VERSION ""

NS_ :

BS_:

BU_: Engine2 Aftertreatment_1_GasOutlet BrakesSystemController Transmission1 Engine1

BO_ 2566799614 LD: 8 Vector__XXX
 SG_ ImplementRearWorkLight : 62|2@1+ (1,0) [0|3] "" Vector__XXX
 SG_ ImplementLeftFacingWorkLight : 60|2@1+ (1,0) [0|3] "" Vector__XXX
 SG_ ImplementRightForwardWorkLight : 58|2@1+ (1,0) [0|3] "" Vector__XXX
 SG_ ImplementLeftForwardWorkLight : 54|2@1+ (1,0) [0|3] "" Vector__XXX
 SG_ ImplementRightFacingWorkLight : 52|2@1+ (1,0) [0|3] "" Vector__XXX
 SG_ ImplementOEMOption1Light : 50|2@1+ (1,0) [0|3] "" Vector__XXX
 SG_ ImplementOEMOption2Light : 48|2@1+ (1,0) [0|3] "" Vector__XXX
 SG_ TrctorFrontHighMountedWorkLights : 46|2@1+ (1,0) [0|3] "" Vector__XXX
 SG_ TractorFrontLowMountedWorkLights : 44|2@1+ (1,0) [0|3] "" Vector__XXX
 SG_ TractorSideHighMountedWorkLights : 42|2@1+ (1,0) [0|3] "" Vector__XXX
 SG_ TractorSideLowMountedWorkLights : 40|2@1+ (1,0) [0|3] "" Vector__XXX
 SG_ TractorRearHighMountedWorkLights : 38|2@1+ (1,0) [0|3] "" Vector__XXX
 SG_ TractorRearLowMountedWorkLights : 36|2@1+ (1,0) [0|3] "" Vector__XXX
 SG_ TrctorUndersideMountedWorkLights : 34|2@1+ (1,0) [0|3] "" Vector__XXX
 SG_ RearFogLights : 32|2@1+ (1,0) [0|3] "" Vector__XXX
 SG_ TractorMarkerLight : 30|2@1+ (1,0) [0|3] "" Vector__XXX
 SG_ ImplementMarkerLight : 28|2@1+ (1,0) [0|3] "" Vector__XXX
 SG_ TractorClearanceLight : 26|2@1+ (1,0) [0|3] "" Vector__XXX
 SG_ ImplementClearanceLight : 24|2@1+ (1,0) [0|3] "" Vector__XXX
 SG_ LeftStopLight : 22|2@1+ (1,0) [0|3] "" Vector__XXX
 SG_ RightStopLight : 20|2@1+ (1,0) [0|3] "" Vector__XXX
 SG_ CenterStopLight : 18|2@1+ (1,0) [0|3] "" Vector__XXX
 SG_ BackUpLightAndAlarmHorn : 16|2@1+ (1,0) [0|3] "" Vector__XXX
 SG_ LeftTurnSignalLights : 14|2@1+ (1,0) [0|3] "" Vector__XXX
 SG_ RightTurnSignalLights : 12|2@1+ (1,0) [0|3] "" Vector__XXX
 SG_ RotatingBeaconLight : 10|2@1+ (1,0) [0|3] "" Vector__XXX
 SG_ TractorFrontFogLights : 8|2@1+ (1,0) [0|3] "" Vector__XXX
 SG_ HighBeamHeadLightData : 6|2@1+ (1,0) [0|3] "" Vector__XXX
 SG_ LowBeamHeadLightData : 4|2@1+ (1,0) [0|3] "" Vector__XXX
 SG_ AltBeamHeadLightData : 2|2@1+ (1,0) [0|3] "" Vector__XXX
 SG_ RunningLight : 0|2@1+ (1,0) [0|3] "" Vector__XXX

BO_ 2365473278 LCMD: 8 Vector__XXX
 SG_ ImplementRearWorkLightCmd : 62|2@1+ (1,0) [0|3] "" Vector__XXX
 SG_ ImplementLeftFacingWorkLightCmd : 60|2@1+ (1,0) [0|3] "" Vector__XXX
 SG_ ImplmentRightForwardWorkLightCmd : 58|2@1+ (1,0) [0|3] "" Vector__XXX
 SG_ LightingDataRqCmd : 56|2@1+ (1,0) [0|3] "" Vector__XXX
 SG_ ImplementLeftForwardWorkLightCmd : 54|2@1+ (1,0) [0|3] "" Vector__XXX
 SG_ ImplementRightFacingWorkLightCmd : 52|2@1+ (1,0) [0|3] "" Vector__XXX
 SG_ ImplementOEMOption1LightCmd : 50|2@1+ (1,0) [0|3] "" Vector__XXX
 SG_ ImplementOEMOption2LightCmd : 48|2@1+ (1,0) [0|3] "" Vector__XXX
 SG_ TrctrFrntHghMountedWorkLightsCmd : 46|2@1+ (1,0) [0|3] "" Vector__XXX
 SG_ TrctrFrntLowMountedWorkLightsCmd : 44|2@1+ (1,0) [0|3] "" Vector__XXX
 SG_ TrctrSdeHighMountedWorkLightsCmd : 42|2@1+ (1,0) [0|3] "" Vector__XXX
 SG_ TrctrSideLowMountedWorkLightsCmd : 40|2@1+ (1,0) [0|3] "" Vector__XXX
 SG_ TrctrRarHighMountedWorkLightsCmd : 38|2@1+ (1,0) [0|3] "" Vector__XXX
 SG_ TrctrRearLowMountedWorkLightsCmd : 36|2@1+ (1,0) [0|3] "" Vector__XXX
 SG_ TrctrUndrsdeMountedWorkLightsCmd : 34|2@1+ (1,0) [0|3] "" Vector__XXX
 SG_ RearFogLightCmd : 32|2@1+ (1,0) [0|3] "" Vector__XXX
 SG_ TractorMarkerLightCmd : 30|2@1+ (1,0) [0|3] "" Vector__XXX
 SG_ ImplementMarkerLightCmd : 28|2@1+ (1,0) [0|3] "" Vector__XXX
 SG_ TractorClearanceLightCmd : 26|2@1+ (1,0) [0|3] "" Vector__XXX
 SG_ ImplementClearanceLightCmd : 24|2@1+ (1,0) [0|3] "" Vector__XXX
 SG_ LeftStopLightCmd : 22|2@1+ (1,0) [0|3] "" Vector__XXX
 SG_ RightStopLightCmd : 20|2@1+ (1,0) [0|3] "" Vector__XXX
 SG_ CenterStopLightCmd : 18|2@1+ (1,0) [0|3] "" Vector__XXX
 SG_ BackUpLightAndAlarmHornCmd : 16|2@1+ (1,0) [0|3] "" Vector__XXX
 SG_ LeftTurnSignalLightsCmd : 14|2@1+ (1,0) [0|3] "" Vector__XXX
 SG_ RightTurnSignalLightsCmd : 12|2@1+ (1,0) [0|3] "" Vector__XXX
 SG_ RotatingBeaconLightCmd : 10|2@1+ (1,0) [0|3] "" Vector__XXX
 SG_ TractorFrontFogLightsCmd : 8|2@1+ (1,0) [0|3] "" Vector__XXX
 SG_ HighBeamHeadLightCmd : 6|2@1+ (1,0) [0|3] "" Vector__XXX
 SG_ LowBeamHeadLightCmd : 4|2@1+ (1,0) [0|3] "" Vector__XXX
 SG_ AltBeamHeadLightCmd : 2|2@1+ (1,0) [0|3] "" Vector__XXX
 SG_ RunningLightCmd : 0|2@1+ (1,0) [0|3] "" Vector__XXX

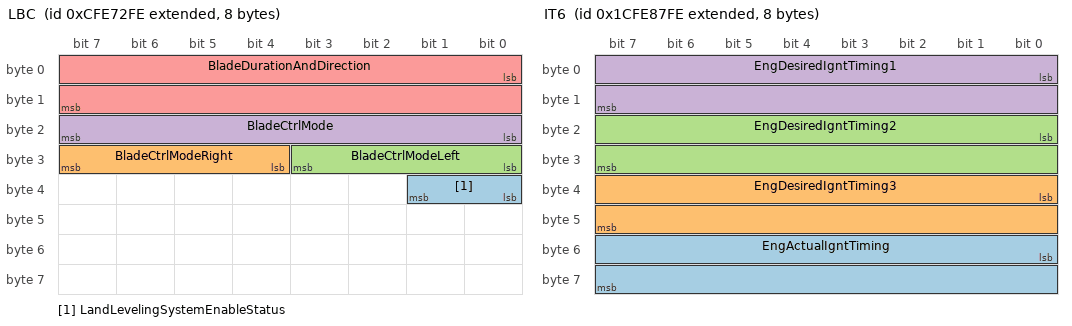
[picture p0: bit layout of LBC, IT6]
BO_ 2365485822 LBC: 8 Vector__XXX
 SG_ LandLevelingSystemEnableStatus : 32|2@1+ (1,0) [0|3] "" Vector__XXX
 SG_ BladeCtrlModeRight : 28|4@1+ (1,0) [0|15] "" Vector__XXX
 SG_ BladeCtrlModeLeft : 24|4@1+ (1,0) [0|15] "" Vector__XXX
 SG_ BladeCtrlMode : 16|8@1+ (1,0) [0|255] "" Vector__XXX
 SG_ BladeDurationAndDirection : 0|16@1+ (0.1,-3276.8) [-3276.8|3148.7] "sec" Vector__XXX

BO_ 2633926654 IT6: 8 Vector__XXX
 SG_ EngActualIgntTiming : 48|16@1+ (0.0078125,-200) [-200|301.99] "deg" Vector__XXX
 SG_ EngDesiredIgntTiming3 : 32|16@1+ (0.0078125,-200) [-200|301.99] "deg" Vector__XXX
 SG_ EngDesiredIgntTiming2 : 16|16@1+ (0.0078125,-200) [-200|301.99] "deg" Vector__XXX
 SG_ EngDesiredIgntTiming1 : 0|16@1+ (0.0078125,-200) [-200|301.99] "deg" Vector__XXX

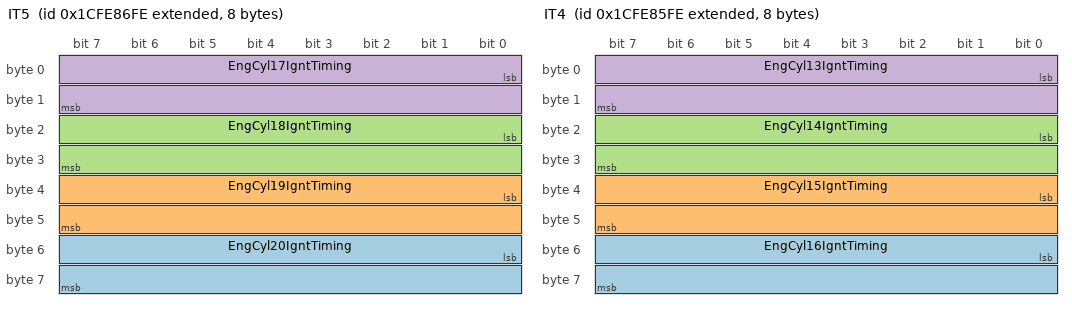
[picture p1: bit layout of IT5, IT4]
BO_ 2633926398 IT5: 8 Vector__XXX
 SG_ EngCyl20IgntTiming : 48|16@1+ (0.0078125,-200) [-200|301.99] "deg" Vector__XXX
 SG_ EngCyl19IgntTiming : 32|16@1+ (0.0078125,-200) [-200|301.99] "deg" Vector__XXX
 SG_ EngCyl18IgntTiming : 16|16@1+ (0.0078125,-200) [-200|301.99] "deg" Vector__XXX
 SG_ EngCyl17IgntTiming : 0|16@1+ (0.0078125,-200) [-200|301.99] "deg" Vector__XXX

BO_ 2633926142 IT4: 8 Vector__XXX
 SG_ EngCyl16IgntTiming : 48|16@1+ (0.0078125,-200) [-200|301.99] "deg" Vector__XXX
 SG_ EngCyl15IgntTiming : 32|16@1+ (0.0078125,-200) [-200|301.99] "deg" Vector__XXX
 SG_ EngCyl14IgntTiming : 16|16@1+ (0.0078125,-200) [-200|301.99] "deg" Vector__XXX
 SG_ EngCyl13IgntTiming : 0|16@1+ (0.0078125,-200) [-200|301.99] "deg" Vector__XXX

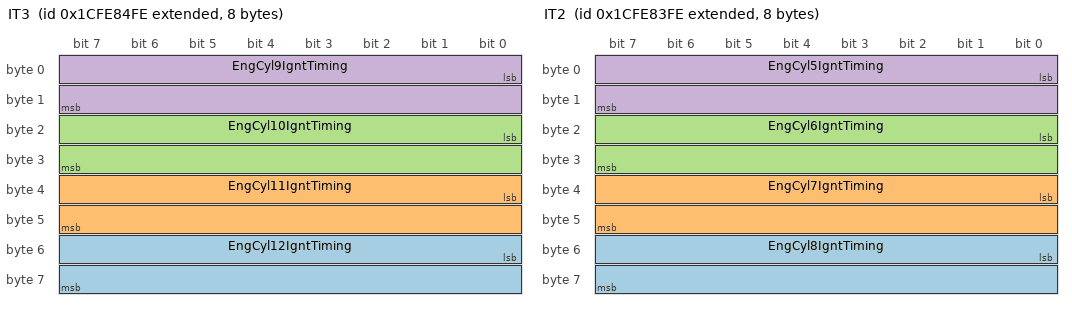
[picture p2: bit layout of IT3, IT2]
BO_ 2633925886 IT3: 8 Vector__XXX
 SG_ EngCyl12IgntTiming : 48|16@1+ (0.0078125,-200) [-200|301.99] "deg" Vector__XXX
 SG_ EngCyl11IgntTiming : 32|16@1+ (0.0078125,-200) [-200|301.99] "deg" Vector__XXX
 SG_ EngCyl10IgntTiming : 16|16@1+ (0.0078125,-200) [-200|301.99] "deg" Vector__XXX
 SG_ EngCyl9IgntTiming : 0|16@1+ (0.0078125,-200) [-200|301.99] "deg" Vector__XXX

BO_ 2633925630 IT2: 8 Vector__XXX
 SG_ EngCyl8IgntTiming : 48|16@1+ (0.0078125,-200) [-200|301.99] "deg" Vector__XXX
 SG_ EngCyl7IgntTiming : 32|16@1+ (0.0078125,-200) [-200|301.99] "deg" Vector__XXX
 SG_ EngCyl6IgntTiming : 16|16@1+ (0.0078125,-200) [-200|301.99] "deg" Vector__XXX
 SG_ EngCyl5IgntTiming : 0|16@1+ (0.0078125,-200) [-200|301.99] "deg" Vector__XXX

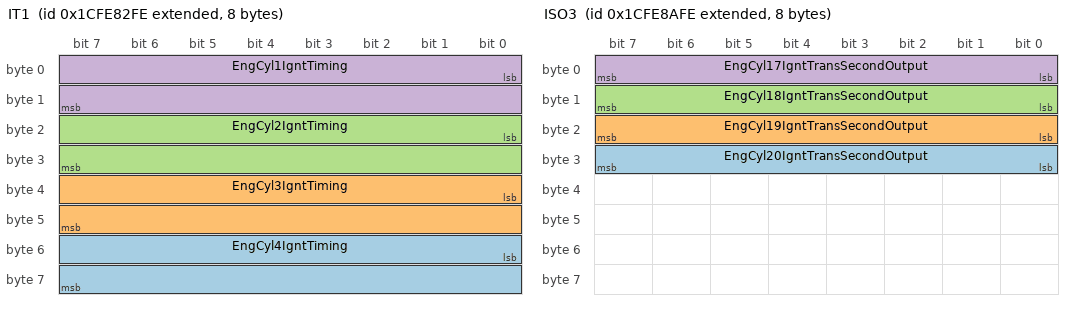
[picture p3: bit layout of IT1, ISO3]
BO_ 2633925374 IT1: 8 Vector__XXX
 SG_ EngCyl4IgntTiming : 48|16@1+ (0.0078125,-200) [-200|301.99] "deg" Vector__XXX
 SG_ EngCyl3IgntTiming : 32|16@1+ (0.0078125,-200) [-200|301.99] "deg" Vector__XXX
 SG_ EngCyl2IgntTiming : 16|16@1+ (0.0078125,-200) [-200|301.99] "deg" Vector__XXX
 SG_ EngCyl1IgntTiming : 0|16@1+ (0.0078125,-200) [-200|301.99] "deg" Vector__XXX

BO_ 2633927422 ISO3: 8 Vector__XXX
 SG_ EngCyl20IgntTransSecondOutput : 24|8@1+ (1,-125) [-125|125] "%" Vector__XXX
 SG_ EngCyl19IgntTransSecondOutput : 16|8@1+ (1,-125) [-125|125] "%" Vector__XXX
 SG_ EngCyl18IgntTransSecondOutput : 8|8@1+ (1,-125) [-125|125] "%" Vector__XXX
 SG_ EngCyl17IgntTransSecondOutput : 0|8@1+ (1,-125) [-125|125] "%" Vector__XXX

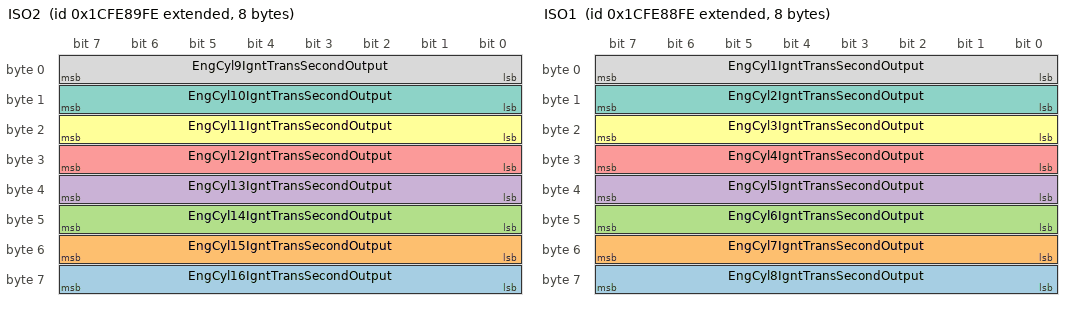
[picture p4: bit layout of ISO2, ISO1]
BO_ 2633927166 ISO2: 8 Vector__XXX
 SG_ EngCyl16IgntTransSecondOutput : 56|8@1+ (1,-125) [-125|125] "%" Vector__XXX
 SG_ EngCyl15IgntTransSecondOutput : 48|8@1+ (1,-125) [-125|125] "%" Vector__XXX
 SG_ EngCyl14IgntTransSecondOutput : 40|8@1+ (1,-125) [-125|125] "%" Vector__XXX
 SG_ EngCyl13IgntTransSecondOutput : 32|8@1+ (1,-125) [-125|125] "%" Vector__XXX
 SG_ EngCyl12IgntTransSecondOutput : 24|8@1+ (1,-125) [-125|125] "%" Vector__XXX
 SG_ EngCyl11IgntTransSecondOutput : 16|8@1+ (1,-125) [-125|125] "%" Vector__XXX
 SG_ EngCyl10IgntTransSecondOutput : 8|8@1+ (1,-125) [-125|125] "%" Vector__XXX
 SG_ EngCyl9IgntTransSecondOutput : 0|8@1+ (1,-125) [-125|125] "%" Vector__XXX

BO_ 2633926910 ISO1: 8 Vector__XXX
 SG_ EngCyl8IgntTransSecondOutput : 56|8@1+ (1,-125) [-125|125] "%" Vector__XXX
 SG_ EngCyl7IgntTransSecondOutput : 48|8@1+ (1,-125) [-125|125] "%" Vector__XXX
 SG_ EngCyl6IgntTransSecondOutput : 40|8@1+ (1,-125) [-125|125] "%" Vector__XXX
 SG_ EngCyl5IgntTransSecondOutput : 32|8@1+ (1,-125) [-125|125] "%" Vector__XXX
 SG_ EngCyl4IgntTransSecondOutput : 24|8@1+ (1,-125) [-125|125] "%" Vector__XXX
 SG_ EngCyl3IgntTransSecondOutput : 16|8@1+ (1,-125) [-125|125] "%" Vector__XXX
 SG_ EngCyl2IgntTransSecondOutput : 8|8@1+ (1,-125) [-125|125] "%" Vector__XXX
 SG_ EngCyl1IgntTransSecondOutput : 0|8@1+ (1,-125) [-125|125] "%" Vector__XXX

BO_ 2566768894 ISCS: 8 Vector__XXX
 SG_ EngOprtrPrmryIntrmdtSpdSlctState : 0|4@1+ (1,0) [0|15] "" Vector__XXX

BO_ 2566769406 ISC: 8 Vector__XXX
 SG_ EngOprtrPrmryIntrmdteSpeedSelect : 0|4@1+ (1,0) [0|15] "" Vector__XXX

BO_ 2566839550 IO: 8 Vector__XXX
 SG_ EngTotalIdleHours : 32|32@1+ (0.05,0) [0|210554060.75] "h" Vector__XXX
 SG_ EngTotalIdleFuelUsed : 0|32@1+ (0.5,0) [0|2105540607.5] "L" Vector__XXX

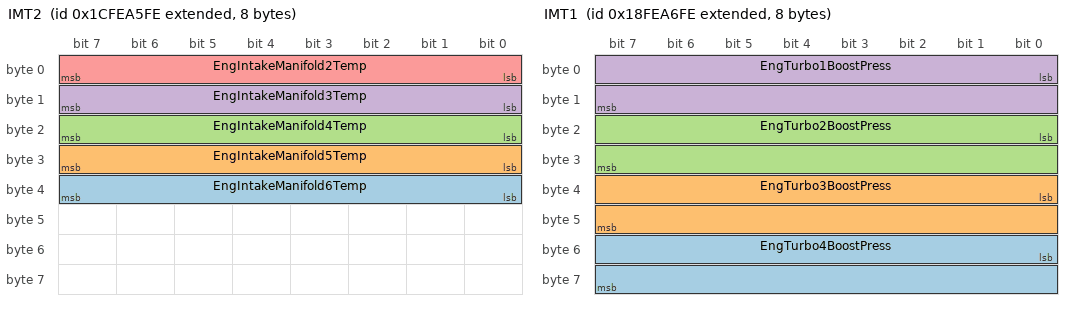
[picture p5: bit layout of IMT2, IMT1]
BO_ 2633934334 IMT2: 8 Vector__XXX
 SG_ EngIntakeManifold6Temp : 32|8@1+ (1,-40) [-40|210] "°C" Vector__XXX
 SG_ EngIntakeManifold5Temp : 24|8@1+ (1,-40) [-40|210] "°C" Vector__XXX
 SG_ EngIntakeManifold4Temp : 16|8@1+ (1,-40) [-40|210] "°C" Vector__XXX
 SG_ EngIntakeManifold3Temp : 8|8@1+ (1,-40) [-40|210] "°C" Vector__XXX
 SG_ EngIntakeManifold2Temp : 0|8@1+ (1,-40) [-40|210] "°C" Vector__XXX

BO_ 2566825726 IMT1: 8 Vector__XXX
 SG_ EngTurbo4BoostPress : 48|16@1+ (0.125,0) [0|8031.875] "kPa" Vector__XXX
 SG_ EngTurbo3BoostPress : 32|16@1+ (0.125,0) [0|8031.875] "kPa" Vector__XXX
 SG_ EngTurbo2BoostPress : 16|16@1+ (0.125,0) [0|8031.875] "kPa" Vector__XXX
 SG_ EngTurbo1BoostPress : 0|16@1+ (0.125,0) [0|8031.875] "kPa" Vector__XXX

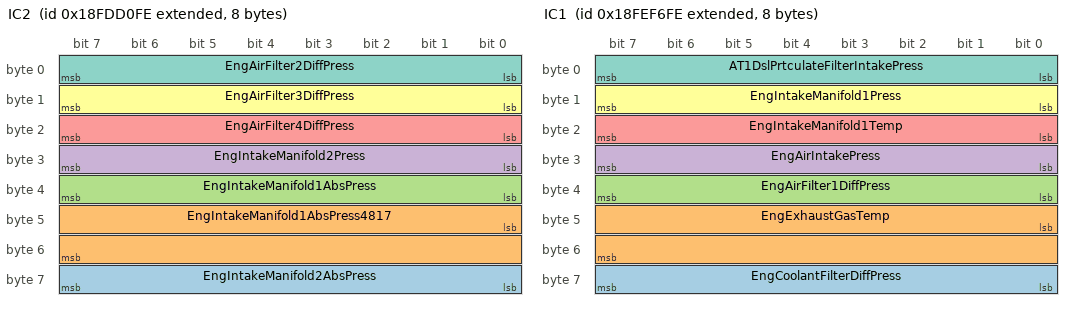
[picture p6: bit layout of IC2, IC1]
BO_ 2566770942 IC2: 8 Vector__XXX
 SG_ EngIntakeManifold2AbsPress : 56|8@1+ (2,0) [0|500] "kPa" Vector__XXX
 SG_ EngIntakeManifold1AbsPress4817 : 40|16@1+ (0.1,0) [0|6425.5] "kPa" Vector__XXX
 SG_ EngIntakeManifold1AbsPress : 32|8@1+ (2,0) [0|500] "kPa" Vector__XXX
 SG_ EngIntakeManifold2Press : 24|8@1+ (2,0) [0|500] "kPa" Vector__XXX
 SG_ EngAirFilter4DiffPress : 16|8@1+ (0.05,0) [0|12.5] "kPa" Vector__XXX
 SG_ EngAirFilter3DiffPress : 8|8@1+ (0.05,0) [0|12.5] "kPa" Vector__XXX
 SG_ EngAirFilter2DiffPress : 0|8@1+ (0.05,0) [0|12.5] "kPa" Vector__XXX

BO_ 2566846206 IC1: 8 Vector__XXX
 SG_ EngCoolantFilterDiffPress : 56|8@1+ (0.5,0) [0|125] "kPa" Vector__XXX
 SG_ EngExhaustGasTemp : 40|16@1+ (0.03125,-273) [-273|1734.96875] "°C" Vector__XXX
 SG_ EngAirFilter1DiffPress : 32|8@1+ (0.05,0) [0|12.5] "kPa" Vector__XXX
 SG_ EngAirIntakePress : 24|8@1+ (2,0) [0|500] "kPa" Vector__XXX
 SG_ EngIntakeManifold1Temp : 16|8@1+ (1,-40) [-40|210] "°C" Vector__XXX
 SG_ EngIntakeManifold1Press : 8|8@1+ (2,0) [0|500] "kPa" Vector__XXX
 SG_ AT1DslPrtculateFilterIntakePress : 0|8@1+ (0.5,0) [0|125] "kPa" Vector__XXX

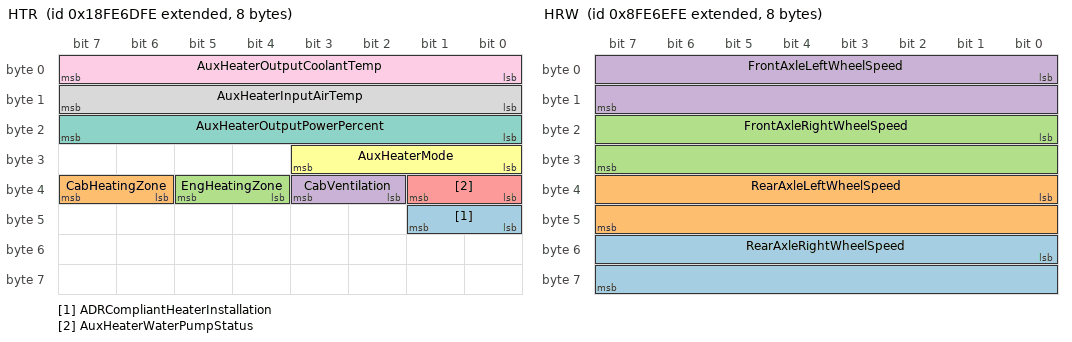
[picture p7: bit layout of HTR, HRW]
BO_ 2566811134 HTR: 8 Vector__XXX
 SG_ ADRCompliantHeaterInstallation : 40|2@1+ (1,0) [0|3] "" Vector__XXX
 SG_ CabHeatingZone : 38|2@1+ (1,0) [0|3] "" Vector__XXX
 SG_ EngHeatingZone : 36|2@1+ (1,0) [0|3] "" Vector__XXX
 SG_ CabVentilation : 34|2@1+ (1,0) [0|3] "" Vector__XXX
 SG_ AuxHeaterWaterPumpStatus : 32|2@1+ (1,0) [0|3] "" Vector__XXX
 SG_ AuxHeaterMode : 24|4@1+ (1,0) [0|15] "" Vector__XXX
 SG_ AuxHeaterOutputPowerPercent : 16|8@1+ (0.4,0) [0|100] "%" Vector__XXX
 SG_ AuxHeaterInputAirTemp : 8|8@1+ (1,-40) [-40|210] "°C" Vector__XXX
 SG_ AuxHeaterOutputCoolantTemp : 0|8@1+ (1,-40) [-40|210] "°C" Vector__XXX

BO_ 2298375934 HRW: 8 Vector__XXX
 SG_ RearAxleRightWheelSpeed : 48|16@1+ (0.00390625,0) [0|250.996] "km/h" Vector__XXX
 SG_ RearAxleLeftWheelSpeed : 32|16@1+ (0.00390625,0) [0|250.996] "km/h" Vector__XXX
 SG_ FrontAxleRightWheelSpeed : 16|16@1+ (0.00390625,0) [0|250.996] "km/h" Vector__XXX
 SG_ FrontAxleLeftWheelSpeed : 0|16@1+ (0.00390625,0) [0|250.996] "km/h" Vector__XXX

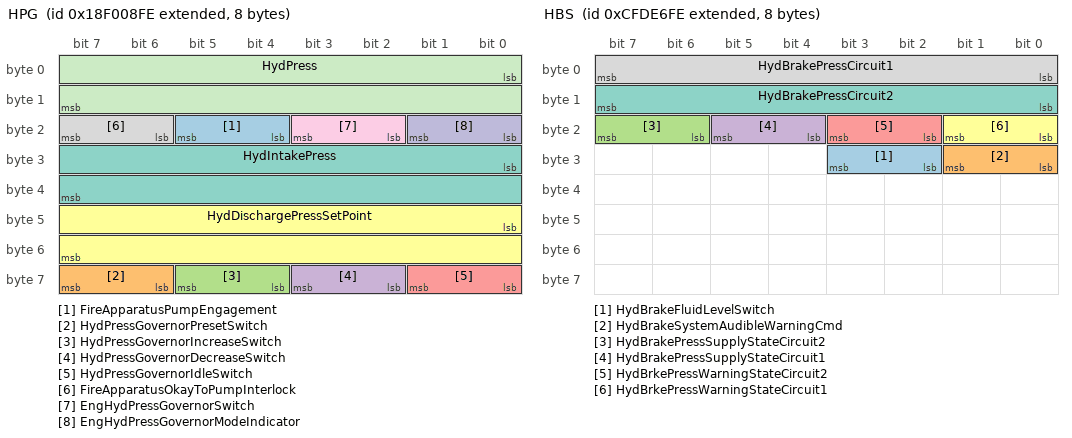
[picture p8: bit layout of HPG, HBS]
BO_ 2565867774 HPG: 8 Vector__XXX
 SG_ FireApparatusPumpEngagement : 20|2@1+ (1,0) [0|3] "" Vector__XXX
 SG_ HydPressGovernorPresetSwitch : 62|2@1+ (1,0) [0|3] "" Vector__XXX
 SG_ HydPressGovernorIncreaseSwitch : 60|2@1+ (1,0) [0|3] "" Vector__XXX
 SG_ HydPressGovernorDecreaseSwitch : 58|2@1+ (1,0) [0|3] "" Vector__XXX
 SG_ HydPressGovernorIdleSwitch : 56|2@1+ (1,0) [0|3] "" Vector__XXX
 SG_ HydDischargePressSetPoint : 40|16@1+ (2,0) [0|128510] "kPa" Vector__XXX
 SG_ HydIntakePress : 24|16@1+ (0.0001220703125,-1) [-1|6.84362793] "MPa" Vector__XXX
 SG_ FireApparatusOkayToPumpInterlock : 22|2@1+ (1,0) [0|3] "" Vector__XXX
 SG_ EngHydPressGovernorSwitch : 18|2@1+ (1,0) [0|3] "" Vector__XXX
 SG_ EngHydPressGovernorModeIndicator : 16|2@1+ (1,0) [0|3] "" Vector__XXX
 SG_ HydPress : 0|16@1+ (2,0) [0|128510] "kPa" Vector__XXX

BO_ 2566841854 HOURS: 8 Vector__XXX
 SG_ EngTotalRevolutions : 32|32@1+ (1000,0) [0|4211081215000] "r" Vector__XXX
 SG_ EngTotalHoursOfOperation : 0|32@1+ (0.05,0) [0|210554060.75] "h" Vector__XXX

BO_ 2365449982 HBS: 8 Vector__XXX
 SG_ HydBrakeFluidLevelSwitch : 26|2@1+ (1,0) [0|3] "" Vector__XXX
 SG_ HydBrakeSystemAudibleWarningCmd : 24|2@1+ (1,0) [0|3] "" Vector__XXX
 SG_ HydBrakePressSupplyStateCircuit2 : 22|2@1+ (1,0) [0|3] "" Vector__XXX
 SG_ HydBrakePressSupplyStateCircuit1 : 20|2@1+ (1,0) [0|3] "" Vector__XXX
 SG_ HydBrkePressWarningStateCircuit2 : 18|2@1+ (1,0) [0|3] "" Vector__XXX
 SG_ HydBrkePressWarningStateCircuit1 : 16|2@1+ (1,0) [0|3] "" Vector__XXX
 SG_ HydBrakePressCircuit2 : 8|8@1+ (100,0) [0|25000] "kPa" Vector__XXX
 SG_ HydBrakePressCircuit1 : 0|8@1+ (100,0) [0|25000] "kPa" Vector__XXX

BO_ 2633939198 GTFI: 22 Vector__XXX
 SG_ TripDriveFuelEconomy : 160|16@1+ (0.001953125,0) [0|125.498046875] "km/kg" Vector__XXX
 SG_ TripCruiseFuelUsed : 128|32@1+ (0.5,0) [0|2105540607.5] "kg" Vector__XXX
 SG_ TripVehicleIdleFuelUsed : 96|32@1+ (0.5,0) [0|2105540607.5] "kg" Vector__XXX
 SG_ TripPTOGovernorNonmovingFuelUsed : 64|32@1+ (0.5,0) [0|2105540607.5] "kg" Vector__XXX
 SG_ TripPTOGovernorMovingFuelUsed : 32|32@1+ (0.5,0) [0|2105540607.5] "kg" Vector__XXX
 SG_ TripDriveFuelUsed : 0|32@1+ (0.5,0) [0|2105540607.5] "kg" Vector__XXX

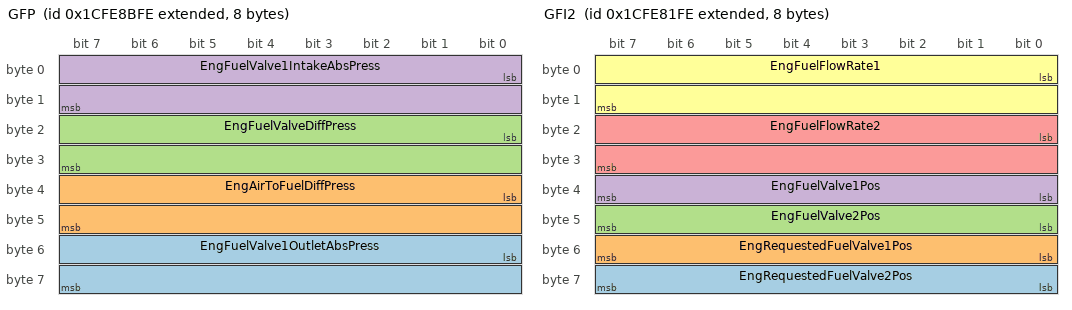
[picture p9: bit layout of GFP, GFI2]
BO_ 2633927678 GFP: 8 Vector__XXX
 SG_ EngFuelValve1OutletAbsPress : 48|16@1+ (0.1,0) [0|6425.5] "kPa" Vector__XXX
 SG_ EngAirToFuelDiffPress : 32|16@1+ (0.1,0) [0|6425.5] "kPa" Vector__XXX
 SG_ EngFuelValveDiffPress : 16|16@1+ (0.1,0) [0|6425.5] "kPa" Vector__XXX
 SG_ EngFuelValve1IntakeAbsPress : 0|16@1+ (0.1,0) [0|6425.5] "kPa" Vector__XXX

BO_ 2633925118 GFI2: 8 Vector__XXX
 SG_ EngRequestedFuelValve2Pos : 56|8@1+ (0.4,0) [0|100] "%" Vector__XXX
 SG_ EngRequestedFuelValve1Pos : 48|8@1+ (0.4,0) [0|100] "%" Vector__XXX
 SG_ EngFuelValve2Pos : 40|8@1+ (0.4,0) [0|100] "%" Vector__XXX
 SG_ EngFuelValve1Pos : 32|8@1+ (0.4,0) [0|100] "%" Vector__XXX
 SG_ EngFuelFlowRate2 : 16|16@1+ (0.1,0) [0|6425.5] "m³/h" Vector__XXX
 SG_ EngFuelFlowRate1 : 0|16@1+ (0.1,0) [0|6425.5] "m³/h" Vector__XXX

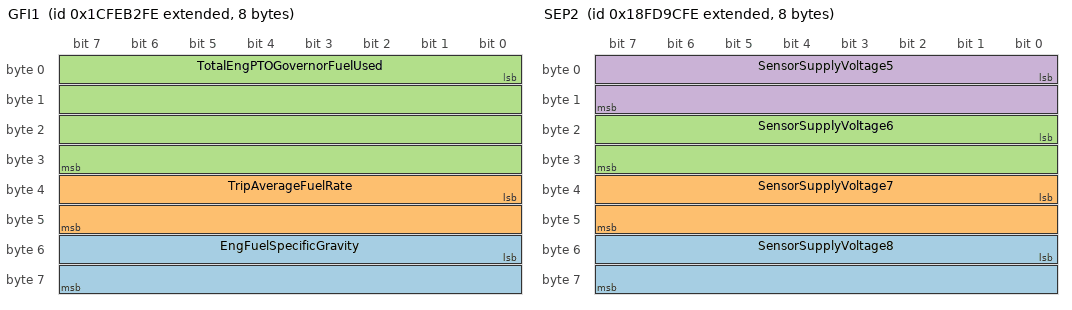
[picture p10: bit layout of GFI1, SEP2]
BO_ 2633937662 GFI1: 8 Vector__XXX
 SG_ EngFuelSpecificGravity : 48|16@1+ (0.0001,0) [0|2] "" Vector__XXX
 SG_ TripAverageFuelRate : 32|16@1+ (0.05,0) [0|3212.75] "kg/h" Vector__XXX
 SG_ TotalEngPTOGovernorFuelUsed : 0|32@1+ (0.5,0) [0|2105540607.5] "kg" Vector__XXX

BO_ 2566804990 GFD: 8 Vector__XXX
 SG_ FuelEnergyContent : 32|16@1+ (0.00390625,0) [0|250.996] "MJ/Nm³" Vector__XXX
 SG_ ReferenceEngGasMassFlowRate : 16|16@1+ (0.05,0) [0|3212.75] "kg/h" Vector__XXX
 SG_ SpecificHeatRatio : 0|16@1+ (0.001,0) [0|2] "" Vector__XXX

BO_ 2633936894 GFC: 8 Vector__XXX
 SG_ TotalFuelUsed : 32|32@1+ (0.5,0) [0|2105540607.5] "kg" Vector__XXX
 SG_ TripFuel : 0|32@1+ (0.5,0) [0|2105540607.5] "kg" Vector__XXX

BO_ 2566757630 SEP2: 8 Vector__XXX
 SG_ SensorSupplyVoltage8 : 48|16@1+ (0.05,0) [0|3212.75] "V" Vector__XXX
 SG_ SensorSupplyVoltage7 : 32|16@1+ (0.05,0) [0|3212.75] "V" Vector__XXX
 SG_ SensorSupplyVoltage6 : 16|16@1+ (0.05,0) [0|3212.75] "V" Vector__XXX
 SG_ SensorSupplyVoltage5 : 0|16@1+ (0.05,0) [0|3212.75] "V" Vector__XXX

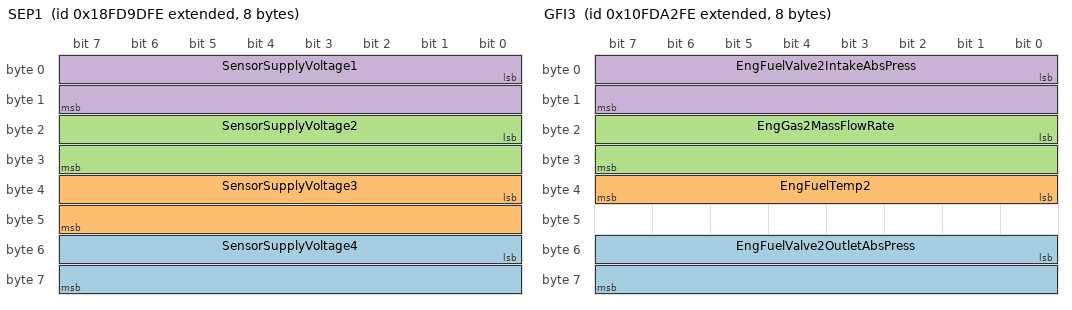
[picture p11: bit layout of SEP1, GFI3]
BO_ 2566757886 SEP1: 8 Vector__XXX
 SG_ SensorSupplyVoltage4 : 48|16@1+ (0.05,0) [0|3212.75] "V" Vector__XXX
 SG_ SensorSupplyVoltage3 : 32|16@1+ (0.05,0) [0|3212.75] "V" Vector__XXX
 SG_ SensorSupplyVoltage2 : 16|16@1+ (0.05,0) [0|3212.75] "V" Vector__XXX
 SG_ SensorSupplyVoltage1 : 0|16@1+ (0.05,0) [0|3212.75] "V" Vector__XXX

BO_ 2566759678 PTODE: 8 Vector__XXX
 SG_ AtLeastOnePTOEngaged : 48|2@1+ (1,0) [0|3] "" Vector__XXX
 SG_ EnggmntSttsPTOEngAccessoryDrive2 : 44|2@1+ (1,0) [0|3] "" Vector__XXX
 SG_ EnggmntSttsPTOEngAccessoryDrive1 : 42|2@1+ (1,0) [0|3] "" Vector__XXX
 SG_ EngagementStatusPTOEngFlywheel : 40|2@1+ (1,0) [0|3] "" Vector__XXX
 SG_ EnggmntStatusTransInputShaftPTO1 : 38|2@1+ (1,0) [0|3] "" Vector__XXX
 SG_ EnggmntStatusTransInputShaftPTO2 : 36|2@1+ (1,0) [0|3] "" Vector__XXX
 SG_ EnggmntStatusTransOutputShaftPTO : 34|2@1+ (1,0) [0|3] "" Vector__XXX
 SG_ EnggmntSttsTrnsfrCsOtputShaftPTO : 32|2@1+ (1,0) [0|3] "" Vector__XXX
 SG_ EnggmntCnsntPTOEngAccssoryDrive2 : 28|2@1+ (1,0) [0|3] "" Vector__XXX
 SG_ EnggmntCnsntPTOEngAccssoryDrive1 : 26|2@1+ (1,0) [0|3] "" Vector__XXX
 SG_ EngagementConsentPTOEngFlywheel : 24|2@1+ (1,0) [0|3] "" Vector__XXX
 SG_ EnggmntCnsentTransInputShaftPTO1 : 22|2@1+ (1,0) [0|3] "" Vector__XXX
 SG_ EnggmntCnsentTransInputShaftPTO2 : 20|2@1+ (1,0) [0|3] "" Vector__XXX
 SG_ EnggmntCnsentTransOutputShaftPTO : 18|2@1+ (1,0) [0|3] "" Vector__XXX
 SG_ EnggmntCnsntTrnsfrCsOtptShaftPTO : 16|2@1+ (1,0) [0|3] "" Vector__XXX
 SG_ EnbleSwitchPTOEngAccessoryDrive2 : 12|2@1+ (1,0) [0|3] "" Vector__XXX
 SG_ EnbleSwitchPTOEngAccessoryDrive1 : 10|2@1+ (1,0) [0|3] "" Vector__XXX
 SG_ EnableSwitchPTOEngFlywheel : 8|2@1+ (1,0) [0|3] "" Vector__XXX
 SG_ EnableSwitchTransInputShaftPTO1 : 6|2@1+ (1,0) [0|3] "" Vector__XXX
 SG_ EnableSwitchTransInputShaftPTO2 : 4|2@1+ (1,0) [0|3] "" Vector__XXX
 SG_ EnableSwitchTransOutputShaftPTO : 2|2@1+ (1,0) [0|3] "" Vector__XXX
 SG_ EnblSwtchTrnsfrCseOutputShaftPTO : 0|2@1+ (1,0) [0|3] "" Vector__XXX

BO_ 2432541438 GFI3: 8 Vector__XXX
 SG_ EngFuelValve2OutletAbsPress : 48|16@1+ (0.1,0) [0|6425.5] "kPa" Vector__XXX
 SG_ EngFuelTemp2 : 32|8@1+ (1,-40) [-40|210] "°C" Vector__XXX
 SG_ EngGas2MassFlowRate : 16|16@1+ (0.05,0) [0|3212.75] "kg/h" Vector__XXX
 SG_ EngFuelValve2IntakeAbsPress : 0|16@1+ (0.1,0) [0|6425.5] "kPa" Vector__XXX

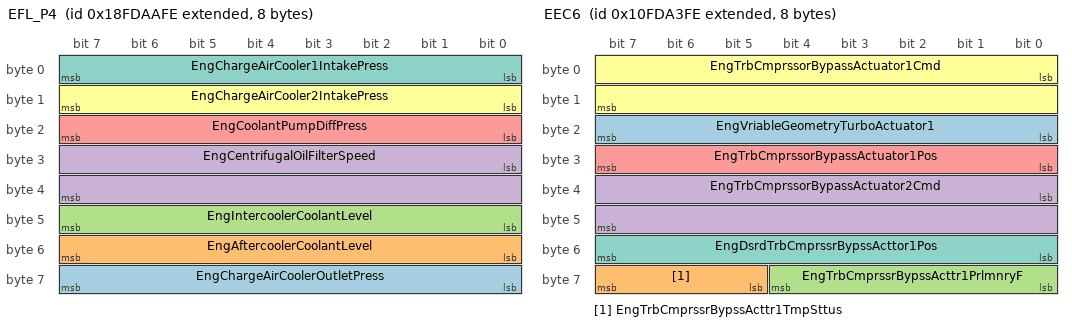
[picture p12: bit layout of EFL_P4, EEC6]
BO_ 2566761214 EFL_P4: 8 Vector__XXX
 SG_ EngChargeAirCoolerOutletPress : 56|8@1+ (2,0) [0|500] "kPa" Vector__XXX
 SG_ EngAftercoolerCoolantLevel : 48|8@1+ (0.4,0) [0|100] "%" Vector__XXX
 SG_ EngIntercoolerCoolantLevel : 40|8@1+ (0.4,0) [0|100] "%" Vector__XXX
 SG_ EngCentrifugalOilFilterSpeed : 24|16@1+ (4,0) [0|257020] "rpm" Vector__XXX
 SG_ EngCoolantPumpDiffPress : 16|8@1+ (1.64,-7) [-7|403] "kPa" Vector__XXX
 SG_ EngChargeAirCooler2IntakePress : 8|8@1+ (2,0) [0|500] "kPa" Vector__XXX
 SG_ EngChargeAirCooler1IntakePress : 0|8@1+ (2,0) [0|500] "kPa" Vector__XXX

BO_ 2432541694 EEC6: 8 Vector__XXX
 SG_ EngVriableGeometryTurboActuator1 : 16|8@1+ (0.4,0) [0|100] "%" Vector__XXX
 SG_ EngTrbCmprssrBypssActtr1TmpSttus : 61|3@1+ (1,0) [0|7] "" Vector__XXX
 SG_ EngTrbCmprssrBypssActtr1PrlmnryF : 56|5@1+ (1,0) [0|31] "" Vector__XXX
 SG_ EngTrbCmprssorBypassActuator2Cmd : 32|16@1+ (0.0025,0) [0|160.6375] "%" Vector__XXX
 SG_ EngTrbCmprssorBypassActuator1Pos : 24|8@1+ (0.4,0) [0|100] "%" Vector__XXX
 SG_ EngTrbCmprssorBypassActuator1Cmd : 0|16@1+ (0.0025,0) [0|100] "%" Vector__XXX
 SG_ EngDsrdTrbCmprssrBypssActtor1Pos : 48|8@1+ (0.4,0) [0|100] "%" Vector__XXX

BO_ 2566759934 DC2: 8 Vector__XXX
 SG_ EnableStatusOfDoor10 : 58|2@1+ (1,0) [0|3] "" Vector__XXX
 SG_ OpenStatusOfDoor10 : 56|2@1+ (1,0) [0|3] "" Vector__XXX
 SG_ LockStatusOfDoor10 : 54|2@1+ (1,0) [0|3] "" Vector__XXX
 SG_ EnableStatusOfDoor9 : 52|2@1+ (1,0) [0|3] "" Vector__XXX
 SG_ OpenStatusOfDoor9 : 50|2@1+ (1,0) [0|3] "" Vector__XXX
 SG_ LockStatusOfDoor9 : 48|2@1+ (1,0) [0|3] "" Vector__XXX
 SG_ EnableStatusOfDoor8 : 46|2@1+ (1,0) [0|3] "" Vector__XXX
 SG_ OpenStatusOfDoor8 : 44|2@1+ (1,0) [0|3] "" Vector__XXX
 SG_ LockStatusOfDoor8 : 42|2@1+ (1,0) [0|3] "" Vector__XXX
 SG_ EnableStatusOfDoor7 : 40|2@1+ (1,0) [0|3] "" Vector__XXX
 SG_ OpenStatusOfDoor7 : 38|2@1+ (1,0) [0|3] "" Vector__XXX
 SG_ LockStatusOfDoor7 : 36|2@1+ (1,0) [0|3] "" Vector__XXX
 SG_ EnableStatusOfDoor6 : 34|2@1+ (1,0) [0|3] "" Vector__XXX
 SG_ OpenStatusOfDoor6 : 32|2@1+ (1,0) [0|3] "" Vector__XXX
 SG_ LockStatusOfDoor6 : 30|2@1+ (1,0) [0|3] "" Vector__XXX
 SG_ EnableStatusOfDoor5 : 28|2@1+ (1,0) [0|3] "" Vector__XXX
 SG_ OpenStatusOfDoor5 : 26|2@1+ (1,0) [0|3] "" Vector__XXX
 SG_ LockStatusOfDoor5 : 24|2@1+ (1,0) [0|3] "" Vector__XXX
 SG_ EnableStatusOfDoor4 : 22|2@1+ (1,0) [0|3] "" Vector__XXX
 SG_ OpenStatusOfDoor4 : 20|2@1+ (1,0) [0|3] "" Vector__XXX
 SG_ LockStatusOfDoor4 : 18|2@1+ (1,0) [0|3] "" Vector__XXX
 SG_ EnableStatusOfDoor3 : 16|2@1+ (1,0) [0|3] "" Vector__XXX
 SG_ OpenStatusOfDoor3 : 14|2@1+ (1,0) [0|3] "" Vector__XXX
 SG_ LockStatusOfDoor3 : 12|2@1+ (1,0) [0|3] "" Vector__XXX
 SG_ EnableStatusOfDoor2 : 10|2@1+ (1,0) [0|3] "" Vector__XXX
 SG_ OpenStatusOfDoor2 : 8|2@1+ (1,0) [0|3] "" Vector__XXX
 SG_ LockStatusOfDoor2 : 6|2@1+ (1,0) [0|3] "" Vector__XXX
 SG_ EnableStatusOfDoor1 : 4|2@1+ (1,0) [0|3] "" Vector__XXX
 SG_ OpenStatusOfDoor1 : 2|2@1+ (1,0) [0|3] "" Vector__XXX
 SG_ LockStatusOfDoor1 : 0|2@1+ (1,0) [0|3] "" Vector__XXX

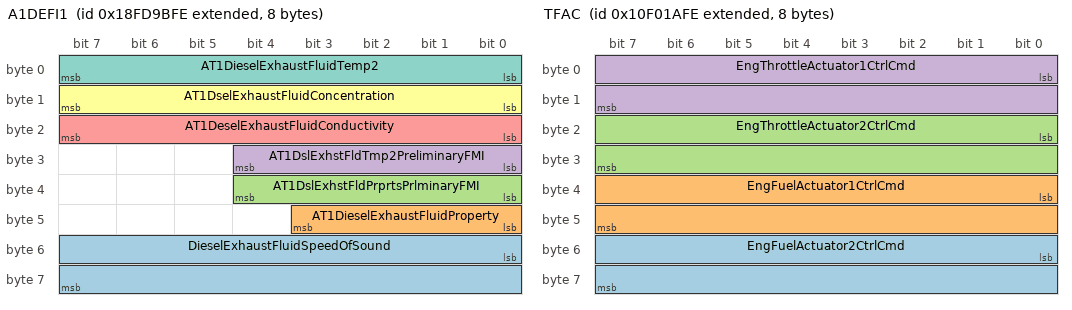
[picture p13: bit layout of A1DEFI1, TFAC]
BO_ 2566757374 A1DEFI1: 8 Vector__XXX
 SG_ DieselExhaustFluidSpeedOfSound : 48|16@1+ (0.1,0) [0|6425.5] "m/s" Vector__XXX
 SG_ AT1DieselExhaustFluidProperty : 40|4@1+ (1,0) [0|15] "" Vector__XXX
 SG_ AT1DslExhstFldPrprtsPrlminaryFMI : 32|5@1+ (1,0) [0|31] "" Vector__XXX
 SG_ AT1DslExhstFldTmp2PreliminaryFMI : 24|5@1+ (1,0) [0|31] "" Vector__XXX
 SG_ AT1DeselExhaustFluidConductivity : 16|8@1+ (5,0) [0|1250] "µSiemens/mm" Vector__XXX
 SG_ AT1DselExhaustFluidConcentration : 8|8@1+ (0.25,0) [0|62.5] "%" Vector__XXX
 SG_ AT1DieselExhaustFluidTemp2 : 0|8@1+ (1,-40) [-40|210] "°C" Vector__XXX

BO_ 2364546302 RGAAC: 8 Vector__XXX
 SG_ RqdGnrtrAvrgLneLineACRMSVoltage : 0|32@1+ (0.0078125,0) [0|32899071] "V" Vector__XXX

BO_ 2431654654 TFAC: 8 Vector__XXX
 SG_ EngFuelActuator2CtrlCmd : 48|16@1+ (0.0025,0) [0|100] "%" Vector__XXX
 SG_ EngFuelActuator1CtrlCmd : 32|16@1+ (0.0025,0) [0|100] "%" Vector__XXX
 SG_ EngThrottleActuator2CtrlCmd : 16|16@1+ (0.0025,0) [0|100] "%" Vector__XXX
 SG_ EngThrottleActuator1CtrlCmd : 0|16@1+ (0.0025,0) [0|100] "%" Vector__XXX

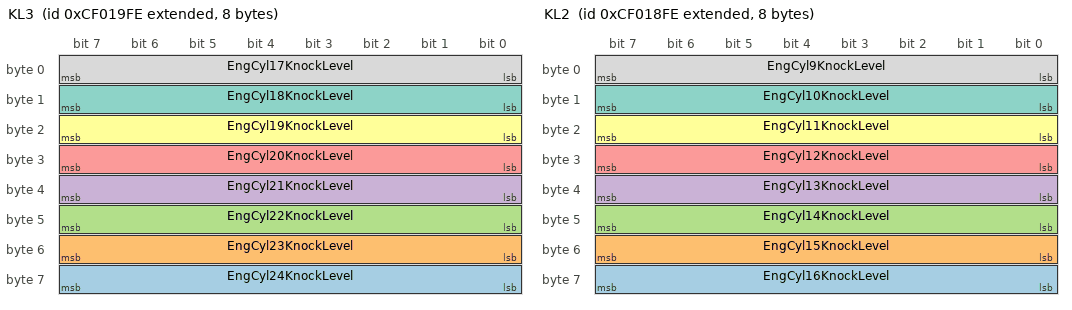
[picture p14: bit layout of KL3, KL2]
BO_ 2364545534 KL3: 8 Vector__XXX
 SG_ EngCyl24KnockLevel : 56|8@1+ (1,0) [0|250] "%" Vector__XXX
 SG_ EngCyl23KnockLevel : 48|8@1+ (1,0) [0|250] "%" Vector__XXX
 SG_ EngCyl22KnockLevel : 40|8@1+ (1,0) [0|250] "%" Vector__XXX
 SG_ EngCyl21KnockLevel : 32|8@1+ (1,0) [0|250] "%" Vector__XXX
 SG_ EngCyl20KnockLevel : 24|8@1+ (1,0) [0|250] "%" Vector__XXX
 SG_ EngCyl19KnockLevel : 16|8@1+ (1,0) [0|250] "%" Vector__XXX
 SG_ EngCyl18KnockLevel : 8|8@1+ (1,0) [0|250] "%" Vector__XXX
 SG_ EngCyl17KnockLevel : 0|8@1+ (1,0) [0|250] "%" Vector__XXX

BO_ 2364545278 KL2: 8 Vector__XXX
 SG_ EngCyl16KnockLevel : 56|8@1+ (1,0) [0|250] "%" Vector__XXX
 SG_ EngCyl15KnockLevel : 48|8@1+ (1,0) [0|250] "%" Vector__XXX
 SG_ EngCyl14KnockLevel : 40|8@1+ (1,0) [0|250] "%" Vector__XXX
 SG_ EngCyl13KnockLevel : 32|8@1+ (1,0) [0|250] "%" Vector__XXX
 SG_ EngCyl12KnockLevel : 24|8@1+ (1,0) [0|250] "%" Vector__XXX
 SG_ EngCyl11KnockLevel : 16|8@1+ (1,0) [0|250] "%" Vector__XXX
 SG_ EngCyl10KnockLevel : 8|8@1+ (1,0) [0|250] "%" Vector__XXX
 SG_ EngCyl9KnockLevel : 0|8@1+ (1,0) [0|250] "%" Vector__XXX

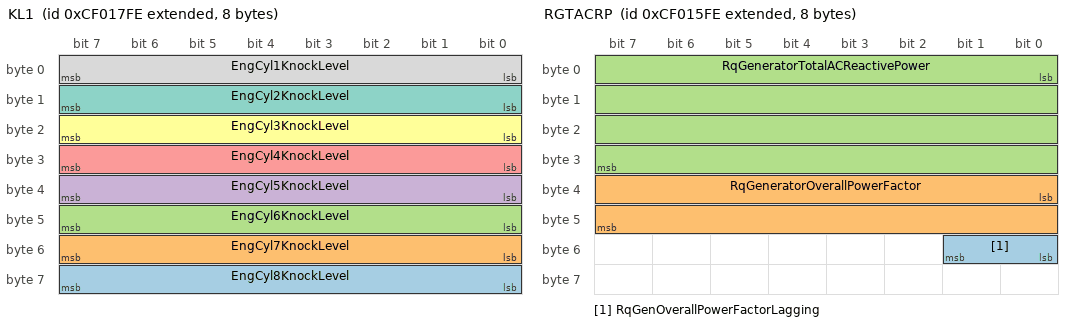
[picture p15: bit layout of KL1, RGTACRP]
BO_ 2364545022 KL1: 8 Vector__XXX
 SG_ EngCyl8KnockLevel : 56|8@1+ (1,0) [0|250] "%" Vector__XXX
 SG_ EngCyl7KnockLevel : 48|8@1+ (1,0) [0|250] "%" Vector__XXX
 SG_ EngCyl6KnockLevel : 40|8@1+ (1,0) [0|250] "%" Vector__XXX
 SG_ EngCyl5KnockLevel : 32|8@1+ (1,0) [0|250] "%" Vector__XXX
 SG_ EngCyl4KnockLevel : 24|8@1+ (1,0) [0|250] "%" Vector__XXX
 SG_ EngCyl3KnockLevel : 16|8@1+ (1,0) [0|250] "%" Vector__XXX
 SG_ EngCyl2KnockLevel : 8|8@1+ (1,0) [0|250] "%" Vector__XXX
 SG_ EngCyl1KnockLevel : 0|8@1+ (1,0) [0|100] "%" Vector__XXX

BO_ 2364544766 CCS: 8 Vector__XXX
 SG_ EngCyl24CombustionStatus : 46|2@1+ (1,0) [0|3] "" Vector__XXX
 SG_ EngCyl23CombustionStatus : 44|2@1+ (1,0) [0|3] "" Vector__XXX
 SG_ EngCyl22CombustionStatus : 42|2@1+ (1,0) [0|3] "" Vector__XXX
 SG_ EngCyl21CombustionStatus : 40|2@1+ (1,0) [0|3] "" Vector__XXX
 SG_ EngCyl20CombustionStatus : 38|2@1+ (1,0) [0|3] "" Vector__XXX
 SG_ EngCyl19CombustionStatus : 36|2@1+ (1,0) [0|3] "" Vector__XXX
 SG_ EngCyl18CombustionStatus : 34|2@1+ (1,0) [0|3] "" Vector__XXX
 SG_ EngCyl17CombustionStatus : 32|2@1+ (1,0) [0|3] "" Vector__XXX
 SG_ EngCyl16CombustionStatus : 30|2@1+ (1,0) [0|3] "" Vector__XXX
 SG_ EngCyl15CombustionStatus : 28|2@1+ (1,0) [0|3] "" Vector__XXX
 SG_ EngCyl14CombustionStatus : 26|2@1+ (1,0) [0|3] "" Vector__XXX
 SG_ EngCyl13CombustionStatus : 24|2@1+ (1,0) [0|3] "" Vector__XXX
 SG_ EngCyl12CombustionStatus : 22|2@1+ (1,0) [0|3] "" Vector__XXX
 SG_ EngCyl11CombustionStatus : 20|2@1+ (1,0) [0|3] "" Vector__XXX
 SG_ EngCyl10CombustionStatus : 18|2@1+ (1,0) [0|3] "" Vector__XXX
 SG_ EngCyl9CombustionStatus : 16|2@1+ (1,0) [0|3] "" Vector__XXX
 SG_ EngCyl8CombustionStatus : 14|2@1+ (1,0) [0|3] "" Vector__XXX
 SG_ EngCyl7CombustionStatus : 12|2@1+ (1,0) [0|3] "" Vector__XXX
 SG_ EngCyl6CombustionStatus : 10|2@1+ (1,0) [0|3] "" Vector__XXX
 SG_ EngCyl5CombustionStatus : 8|2@1+ (1,0) [0|3] "" Vector__XXX
 SG_ EngCyl4CombustionStatus : 6|2@1+ (1,0) [0|3] "" Vector__XXX
 SG_ EngCyl3CombustionStatus : 4|2@1+ (1,0) [0|3] "" Vector__XXX
 SG_ EngCyl2CombustionStatus : 2|2@1+ (1,0) [0|3] "" Vector__XXX
 SG_ EngCyl1CombustionStatus : 0|2@1+ (1,0) [0|3] "" Vector__XXX

BO_ 2364544510 RGTACRP: 8 Vector__XXX
 SG_ RqGenOverallPowerFactorLagging : 48|2@1+ (1,0) [0|3] "" Vector__XXX
 SG_ RqGeneratorOverallPowerFactor : 32|16@1+ (6.103515625E-005,-1) [-1|1] "" Vector__XXX
 SG_ RqGeneratorTotalACReactivePower : 0|32@1+ (1,-2000000000) [-2000000000|2211081215] "VA" Vector__XXX

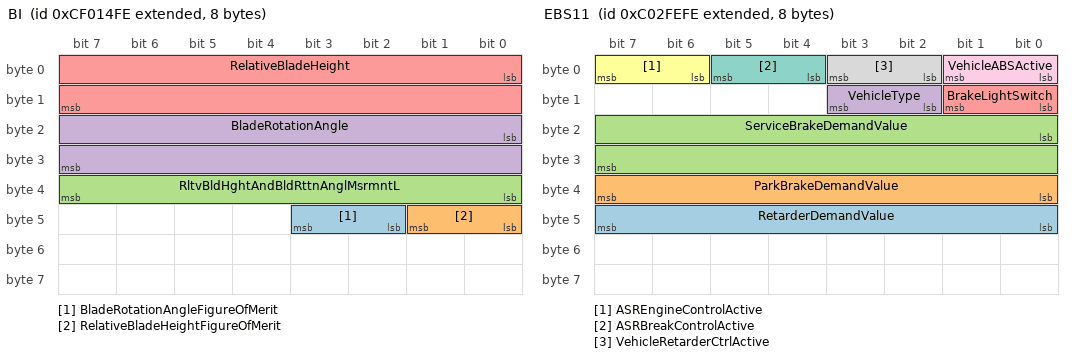
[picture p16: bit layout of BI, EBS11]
BO_ 2364544254 BI: 8 Vector__XXX
 SG_ BladeRotationAngleFigureOfMerit : 42|2@1+ (1,0) [0|3] "" Vector__XXX
 SG_ RelativeBladeHeightFigureOfMerit : 40|2@1+ (1,0) [0|3] "" Vector__XXX
 SG_ RltvBldHghtAndBldRttnAnglMsrmntL : 32|8@1+ (0.5,0) [0|125] "ms" Vector__XXX
 SG_ BladeRotationAngle : 16|16@1+ (0.0078125,-200) [-200|301.99] "deg" Vector__XXX
 SG_ RelativeBladeHeight : 0|16@1+ (0.1,-3200) [-3200|3225.5] "mm" Vector__XXX

BO_ 2349006590 EBS11: 8 Vector__XXX
 SG_ RetarderDemandValue : 40|8@1+ (1,-125) [-125|125] "%" Vector__XXX
 SG_ ParkBrakeDemandValue : 32|8@1+ (0.4,0) [0|100] "%" Vector__XXX
 SG_ ServiceBrakeDemandValue : 16|16@1+ (0.01953125,0) [0|1255] "kPa" Vector__XXX
 SG_ VehicleType : 10|2@1+ (1,0) [0|3] "" Vector__XXX
 SG_ BrakeLightSwitch : 8|2@1+ (1,0) [0|3] "" Vector__XXX
 SG_ ASREngineControlActive : 6|2@1+ (1,0) [0|3] "" Vector__XXX
 SG_ ASRBreakControlActive : 4|2@1+ (1,0) [0|3] "" Vector__XXX
 SG_ VehicleRetarderCtrlActive : 2|2@1+ (1,0) [0|3] "" Vector__XXX
 SG_ VehicleABSActive : 0|2@1+ (1,0) [0|1] "" Vector__XXX

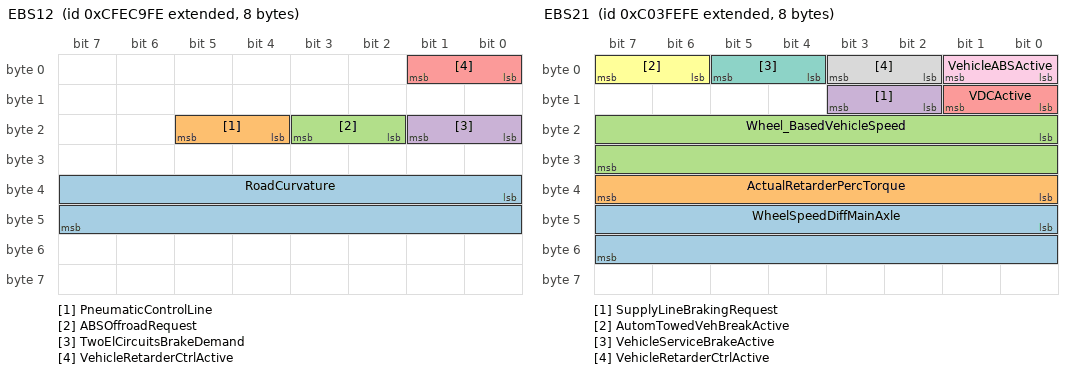
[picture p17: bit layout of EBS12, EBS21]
BO_ 2365508094 EBS12: 8 Vector__XXX
 SG_ RoadCurvature : 32|16@1+ (0.0078125,-250) [-250|251.992] "1/km" Vector__XXX
 SG_ PneumaticControlLine : 20|2@1+ (1,0) [0|1] "" Vector__XXX
 SG_ ABSOffroadRequest : 18|2@1+ (1,0) [0|1] "" Vector__XXX
 SG_ TwoElCircuitsBrakeDemand : 16|2@1+ (1,0) [0|1] "" Vector__XXX
 SG_ VehicleRetarderCtrlActive : 0|2@1+ (1,0) [0|3] "" Vector__XXX

BO_ 2349072126 EBS21: 8 Vector__XXX
 SG_ WheelSpeedDiffMainAxle : 40|16@1+ (0.00390625,-125) [-125|125] "km/hr" Vector__XXX
 SG_ ActualRetarderPercTorque : 32|8@1+ (1,-125) [-125|125] "%" Vector__XXX
 SG_ Wheel_BasedVehicleSpeed : 16|16@1+ (0.00390625,0) [0|251] "km/hr" Vector__XXX
 SG_ SupplyLineBrakingRequest : 10|2@1+ (1,0) [0|1] "" Vector__XXX
 SG_ VDCActive : 8|2@1+ (1,0) [0|1] "" Vector__XXX
 SG_ AutomTowedVehBreakActive : 6|2@1+ (1,0) [0|1] "" Vector__XXX
 SG_ VehicleServiceBrakeActive : 4|2@1+ (1,0) [0|1] "" Vector__XXX
 SG_ VehicleRetarderCtrlActive : 2|2@1+ (1,0) [0|3] "" Vector__XXX
 SG_ VehicleABSActive : 0|2@1+ (1,0) [0|1] "" Vector__XXX

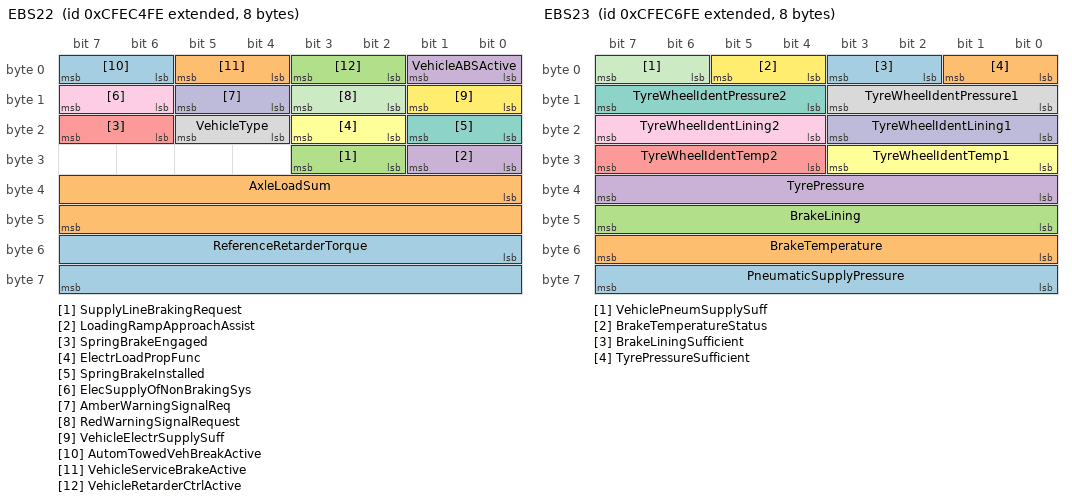
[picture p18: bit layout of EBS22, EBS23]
BO_ 2365506814 EBS22: 8 Vector__XXX
 SG_ ReferenceRetarderTorque : 48|16@1+ (1,0) [0|64255] "Nm" Vector__XXX
 SG_ AxleLoadSum : 32|16@1+ (2,0) [0|128510] "kg" Vector__XXX
 SG_ SupplyLineBrakingRequest : 26|2@1+ (1,0) [0|1] "" Vector__XXX
 SG_ LoadingRampApproachAssist : 24|2@1+ (1,0) [0|1] "" Vector__XXX
 SG_ SpringBrakeEngaged : 22|2@1+ (1,0) [0|1] "" Vector__XXX
 SG_ ElectrLoadPropFunc : 18|2@1+ (1,0) [0|1] "" Vector__XXX
 SG_ SpringBrakeInstalled : 16|2@1+ (1,0) [0|1] "" Vector__XXX
 SG_ VehicleType : 20|2@1+ (1,0) [0|3] "" Vector__XXX
 SG_ ElecSupplyOfNonBrakingSys : 14|2@1+ (1,0) [0|1] "" Vector__XXX
 SG_ AmberWarningSignalReq : 12|2@1+ (1,0) [0|1] "" Vector__XXX
 SG_ RedWarningSignalRequest : 10|2@1+ (1,0) [0|1] "" Vector__XXX
 SG_ VehicleElectrSupplySuff : 8|2@1+ (1,0) [0|1] "" Vector__XXX
 SG_ AutomTowedVehBreakActive : 6|2@1+ (1,0) [0|1] "" Vector__XXX
 SG_ VehicleServiceBrakeActive : 4|2@1+ (1,0) [0|1] "" Vector__XXX
 SG_ VehicleRetarderCtrlActive : 2|2@1+ (1,0) [0|3] "" Vector__XXX
 SG_ VehicleABSActive : 0|2@1+ (1,0) [0|1] "" Vector__XXX

BO_ 2365507326 EBS23: 8 Vector__XXX
 SG_ PneumaticSupplyPressure : 56|8@1+ (5,0) [0|1250] "kPa" Vector__XXX
 SG_ BrakeTemperature : 48|8@1+ (10,0) [0|2500] "°C" Vector__XXX
 SG_ BrakeLining : 40|8@1+ (0.4,0) [0|100] "%" Vector__XXX
 SG_ TyrePressure : 32|8@1+ (10,0) [0|2500] "kPa" Vector__XXX
 SG_ TyreWheelIdentTemp2 : 28|4@1+ (1,0) [0|15] "" Vector__XXX
 SG_ TyreWheelIdentTemp1 : 24|4@1+ (1,0) [0|15] "" Vector__XXX
 SG_ TyreWheelIdentPressure2 : 12|4@1+ (1,0) [0|15] "" Vector__XXX
 SG_ TyreWheelIdentPressure1 : 8|4@1+ (1,0) [0|15] "" Vector__XXX
 SG_ TyreWheelIdentLining2 : 20|4@1+ (1,0) [0|15] "" Vector__XXX
 SG_ TyreWheelIdentLining1 : 16|4@1+ (1,0) [0|15] "" Vector__XXX
 SG_ VehiclePneumSupplySuff : 6|2@1+ (1,0) [0|1] "" Vector__XXX
 SG_ BrakeTemperatureStatus : 4|2@1+ (1,0) [0|1] "" Vector__XXX
 SG_ BrakeLiningSufficient : 2|2@1+ (1,0) [0|1] "" Vector__XXX
 SG_ TyrePressureSufficient : 0|2@1+ (1,0) [0|1] "" Vector__XXX

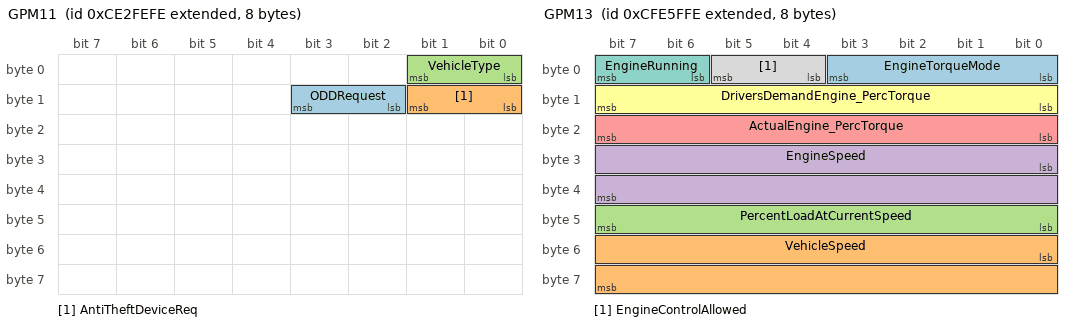
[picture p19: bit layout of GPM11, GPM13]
BO_ 2363686654 GPM11: 8 Vector__XXX
 SG_ ODDRequest : 10|2@1+ (1,0) [0|3] "" Vector__XXX
 SG_ AntiTheftDeviceReq : 8|2@1+ (1,0) [0|3] "" Vector__XXX
 SG_ VehicleType : 0|2@1+ (1,0) [0|3] "" Vector__XXX

BO_ 2365480446 GPM12: 8 Vector__XXX
 SG_ MaxVehicleSpeedLimit : 32|8@1+ (1,0) [0|250] "km/h" Vector__XXX
 SG_ EngineSpeedUpperLimit : 0|16@1+ (0.125,0) [0|8031.875] "rpm" Vector__XXX
 SG_ EngineSpeedLowerLimit : 16|16@1+ (0.125,0) [0|8191.875] "rpm" Vector__XXX

BO_ 2365480958 GPM13: 8 Vector__XXX
 SG_ EngineTorqueMode : 0|4@1+ (1,0) [0|15] "" Vector__XXX
 SG_ VehicleSpeed : 48|16@1+ (0.00390625,0) [0|250.996] "km/hr" Vector__XXX
 SG_ PercentLoadAtCurrentSpeed : 40|8@1+ (1,0) [0|125] "%" Vector__XXX
 SG_ EngineSpeed : 24|16@1+ (0.125,0) [0|8031.88] "rpm" Vector__XXX
 SG_ ActualEngine_PercTorque : 16|8@1+ (1,-125) [-125|125] "%" Vector__XXX
 SG_ DriversDemandEngine_PercTorque : 8|8@1+ (1,-125) [-125|125] "%" Vector__XXX
 SG_ EngineRunning : 6|2@1+ (1,0) [0|1] "" Vector__XXX
 SG_ EngineControlAllowed : 4|2@1+ (1,0) [0|1] "" Vector__XXX

CM_ BO_ 2566799614 "This lighting message is a response to the request for lighting data in the lighting command message.  Each lighting controller on the tractor and attached implements must transmit this message to the Tractor ECU when requested.  The tractor will ...";
CM_ SG_ 2566799614 ImplementRearWorkLight "This parameter provides measured data from the implement rear work lamps.

00 De-activated
01 Activated
10 Fault Detected
11 Not Available";
CM_ SG_ 2566799614 ImplementLeftFacingWorkLight "This parameter provides measured data from the left facing work lights toward the left end of the implement.

00 De-activated
01 Activated
10 Fault Detected
11 Not Available";
CM_ SG_ 2566799614 ImplementRightForwardWorkLight "This parameter provides measured data from the forward facing work lights toward the right end of the implement.

00 De-activated
01 Activated
10 Fault Detected
11 Not Available";
CM_ SG_ 2566799614 ImplementLeftForwardWorkLight "This parameter provides measured data from the work lights mounted on an implement to illuminate the forward left end of the implement.

00 De-activate
01 Activate
10 Fault Detected
11 Not Available";
CM_ SG_ 2566799614 ImplementRightFacingWorkLight "This parameter provides measured data from the work lights mounted on an implement to illuminate beyond right end of the implement.

00 De-activated
01 Activated
10 Fault Detected
11 Not Available";
CM_ SG_ 2566799614 ImplementOEMOption1Light "This parameter provides measured data from the implement OEM option 1 light.

00 De-activated
01 Activated
10 Fault Detected
11 Not Available";
CM_ SG_ 2566799614 ImplementOEMOption2Light "This parameter provides measured data from the implement OEM option 2 light.

00 De-activated
01 Activated
10 Fault Detected
11 Not Available";
CM_ SG_ 2566799614 TrctorFrontHighMountedWorkLights "This parameter provides measured data from the tractor front high mounted work lights. 

00 De-activated
01 Activated
10 Fault Detected
11 Not Available";
CM_ SG_ 2566799614 TractorFrontLowMountedWorkLights "This parameter provides measured data from the tractor front low mounted work lights. 

00 De-activated
01 Activated
10 Fault Detected
11 Not Available";
CM_ SG_ 2566799614 TractorSideHighMountedWorkLights "This parameter provides measured data from the tractor side high mounted work lights. 

00 De-activated
01 Activated
10 Fault Detected
11 Not Available";
CM_ SG_ 2566799614 TractorSideLowMountedWorkLights "This parameter provides measured data from the tractor side low mounted work lights. 

00 De-activated
01 Activated
10 Fault Detected
11 Not Available";
CM_ SG_ 2566799614 TractorRearHighMountedWorkLights "This parameter provides measured data from the tractor rear high mounted work lights. 

00 De-activated
01 Activated
10 Fault Detected
11 Not Available";
CM_ SG_ 2566799614 TractorRearLowMountedWorkLights "This parameter provides measured data from the tractor rear low mounted work lights.

00 De-activated
01 Activated
10 Fault Detected
11 Not Available";
CM_ SG_ 2566799614 TrctorUndersideMountedWorkLights "This parameter provides measured data from the tractor underside mounted work lights. 

00 De-activated
01 Activated
10 Fault Detected
11 Not Available";
CM_ SG_ 2566799614 RearFogLights "This parameter provides measured data from the tractor and/or implement rear fog lights.

00 De-activated
01 Activated
10 Fault Detected
11 Not Available";
CM_ SG_ 2566799614 TractorMarkerLight "This parameter provides measured data from the tractor and attached implement marker lights, including front position lights, rear tail lights, side running lights, license plate lights and instruments and switch back lights.
00 De-activated
01 ...";
CM_ SG_ 2566799614 ImplementMarkerLight "This parameter provides measured data from an attached implement marker lights, including front position lights, rear tail lights, side running lights, license plate lights and instruments and switch back lights.
00 De-activated
01 Activated
10 ...";
CM_ SG_ 2566799614 TractorClearanceLight "This parameter provides measured data from the tractor high mounted clearance and center ID lights.

00 De-activated
01 Activated
10 Fault Detected
11 Not Available";
CM_ SG_ 2566799614 ImplementClearanceLight "This parameter provides measured data from an attached implement high mounted clearance lights.

00 De-activated
01 Activated
10 Fault Detected
11 Not Available";
CM_ SG_ 2566799614 LeftStopLight "This parameter provides measured data from the tractor and attached implement left stop lights.

00 De-activated
01 Activated
10 Fault Detected
11 Not Available";
CM_ SG_ 2566799614 RightStopLight "This parameter provides measured data from the tractor and attached implement right stop lights.

00 De-activated
01 Activated
10 Fault Detected
11 Not Available";
CM_ SG_ 2566799614 CenterStopLight "This parameter provides measured data from the tractor and attached implement center stop lights.

00 De-activated
01 Activated
10 Fault Detected
11 Not Available";
CM_ SG_ 2566799614 BackUpLightAndAlarmHorn "This parameter provides measured data from the back up lights and/ or associated alarm.

00 De-activated
01 Activated
10 Fault Detected
11 Not Available";
CM_ SG_ 2566799614 LeftTurnSignalLights "This parameter provides measured data from the tractor and attached implement left turn signal lights.

00 De-activated
01 Activated
10 Fault Detected
11 Not Available";
CM_ SG_ 2566799614 RightTurnSignalLights "This parameter provides measured data from the tractor and attached implement right turn signal lights.

00 De-activated
01 Activated
10 Fault Detected
11 Not Available";
CM_ SG_ 2566799614 RotatingBeaconLight "This parameter provides measured data from the beacon light on tractor or attached implements.

00 De-activated
01 Activated
10 Fault Detected
11 Not Available";
CM_ SG_ 2566799614 TractorFrontFogLights "This parameter provides measured data from the tractor front fog lights.

00 De-activated
01 Activated
10 Fault Detected
11 Not Available";
CM_ SG_ 2566799614 HighBeamHeadLightData "This parameter provides measured data from the tractor high beam head light lamps. 

00 De-activated
01 Activated
10 Fault Detected
11 Not Available";
CM_ SG_ 2566799614 LowBeamHeadLightData "This parameter provides measured data from the tractor low beam head light lamps. 

00 De-activated
01 Activated
10 Fault Detected
11 Not Available";
CM_ SG_ 2566799614 AltBeamHeadLightData "This parameter provides measured data from the tractor alternate beam head light lamps. 

00 De-activated
01 Activated
10 Fault Detected
11 Not Available";
CM_ SG_ 2566799614 RunningLight "This parameter provides measured data from the vehicle’s running lights.

00 De-activated
01 Activated
10 Fault Detected
11 Not Available";
CM_ BO_ 2365473278 "The lighting command message has been defined as a global message from the tractor to all lighting controllers on the tractor and attached implements.  Separate messages are provided for tractor and implement work and driving lights.  Additional ...";
CM_ SG_ 2365473278 ImplementRearWorkLightCmd "Command to activate or de-activate implement rear work lights.  (This is also the same as Reversing Lights for truck applications.)  

00 De-activate
01 Activate
10 Reserved
11 Don’t Care";
CM_ SG_ 2365473278 ImplementLeftFacingWorkLightCmd "Command to activate or de-activate the left facing work lights toward the left end of the implement.

00 De-activate
01 Activate
10 Reserved
11 Don’t Care";
CM_ SG_ 2365473278 ImplmentRightForwardWorkLightCmd "Command to activate or de-activate the forward facing work lights toward the right end of the implement.

00 De-activate
01 Activate
10 Reserved
11 Don’t Care";
CM_ SG_ 2365473278 LightingDataRqCmd "Command to provide a response of the light state

00 De-activate
01 Activate
10 Reserved
11 Don’t Care";
CM_ SG_ 2365473278 ImplementLeftForwardWorkLightCmd "Command to activate or de-activate work lights mounted on an implement to illuminate beyond left end of the implement.

00 De-activate
01 Activate
10 Reserved
11 Don’t Care";
CM_ SG_ 2365473278 ImplementRightFacingWorkLightCmd "Command to activate or de-activate work lights mounted on an implement to illuminate beyond right end of the implement.

00 De-activate
01 Activate
10 Reserved
11 Don’t Care";
CM_ SG_ 2365473278 ImplementOEMOption1LightCmd "Command to activate or de-activate an implement OEM option 1 light.  This is provided to meet special needs on implements, such as tank inspection or filling lights.

00 De-activate
01 Activate
10 Reserved
11 Don’t Care";
CM_ SG_ 2365473278 ImplementOEMOption2LightCmd "Command to activate or de-activate an implement OEM option 2 light.  This is provided to meet special needs on implements, such as tank inspection or filling lights.

00 De-activate
01 Activate
10 Reserved
11 Don’t Care";
CM_ SG_ 2365473278 TrctrFrntHghMountedWorkLightsCmd "Command to activate or de-activate the tractor front high mounted work lights.

00 De-activate
01 Activate
10 Reserved
11 Don’t Care";
CM_ SG_ 2365473278 TrctrFrntLowMountedWorkLightsCmd "Command to activate or de-activate the tractor front low mounted work lights.

00 De-activate
01 Activate
10 Reserved
11 Don’t Care";
CM_ SG_ 2365473278 TrctrSdeHighMountedWorkLightsCmd "Command to activate or de-activate the tractor side high mounted work lights.

00 De-activate
01 Activate
10 Reserved
11 Don’t Care";
CM_ SG_ 2365473278 TrctrSideLowMountedWorkLightsCmd "Command to activate or de-activate the tractor side low mounted work lights.

00 De-activate
01 Activate
10 Reserved
11 Don’t Care";
CM_ SG_ 2365473278 TrctrRarHighMountedWorkLightsCmd "Command to activate or de-activate the tractor rear high  mounted work lights.

00 De-activate
01 Activate
10 Reserved
11 Don’t Care";
CM_ SG_ 2365473278 TrctrRearLowMountedWorkLightsCmd "Command to activate or de-activate the tractor rear low  mounted work lights.

00 De-activate
01 Activate
10 Reserved
11 Don’t Care";
CM_ SG_ 2365473278 TrctrUndrsdeMountedWorkLightsCmd "Command to activate or de-activate the tractor underside mounted work lights.

00 De-activate
01 Activate
10 Reserved
11 Don’t Care";
CM_ SG_ 2365473278 RearFogLightCmd "Command to activate or de-activate tractor or implement rear fog lights.  

00 De-activate
01 Activate
10 Reserved
11 Don’t Care";
CM_ SG_ 2365473278 TractorMarkerLightCmd "Command to activate or de-activate tractor and implement front position lights, rear red tail lights, side amber running lights, license plate lights and instrument and switch back lights.  

00 De-activate
01 Activate
10 Reserved
11 Don’t Care";
CM_ SG_ 2365473278 ImplementMarkerLightCmd "Command to activate or de-activate implement front position lights, rear red tail lights, side amber running lights, license plate lights and instrument and switch back lights.  

00 De-activate
01 Activate
10 Reserved
11 Don’t Care";
CM_ SG_ 2365473278 TractorClearanceLightCmd "Command to activate or de-activate the tractor high mounted clearance and center ID lights

00 De-activate
01 Activate
10 Reserved
11 Don’t Care";
CM_ SG_ 2365473278 ImplementClearanceLightCmd "Command to activate or de-activate the implement high mounted clearance and lights.  

00 De-activate
01 Activate
10 Reserved
11 Don’t Care";
CM_ SG_ 2365473278 LeftStopLightCmd "Command to activate or de-activate the tractor and implement left stop lights

00 De-activate
01 Activate
10 Reserved
11 Don’t Care";
CM_ SG_ 2365473278 RightStopLightCmd "Command to activate or de-activate the tractor and implement right stop light

00 De-activate
01 Activate
10 Reserved
11 Don’t Care";
CM_ SG_ 2365473278 CenterStopLightCmd "Command to activate or de-activate the tractor and implement center stop light

00 De-activate
01 Activate
10 Reserved
11 Don’t Care";
CM_ SG_ 2365473278 BackUpLightAndAlarmHornCmd "Command to activate or de-activate the back up lights and/ or associated alarm if required

00 De-activate
01 Activate
10 Reserved
11 Don’t Care";
CM_ SG_ 2365473278 LeftTurnSignalLightsCmd "Command to activate or de-activate left turn signal lights on the tractor and all connected implements

00 De-activate
01 Activate
10 Reserved
11 Don’t Care";
CM_ SG_ 2365473278 RightTurnSignalLightsCmd "Command to activate or de-activate right turn signal lights on the tractor and all connected implements

00 De-activate
01 Activate
10 Reserved
11 Don’t Care";
CM_ SG_ 2365473278 RotatingBeaconLightCmd "Command to activate or de-activate slow moving vehicle indicator lights on tractor and/or implements.  Activation of the slow moving vehicle lights implies that the controller should manipulate the lighting as appropriate to provide the slow moving ...";
CM_ SG_ 2365473278 TractorFrontFogLightsCmd "Command to activate or de-activate tractor front fog lights.

00 De-activate
01 Activate
10 Reserved
11 Don’t Care";
CM_ SG_ 2365473278 HighBeamHeadLightCmd "Command to activate or de-activate the tractor high beam head light lamps. 

00 De-activate
01 Activate
10 Reserved
11 Don’t Care";
CM_ SG_ 2365473278 LowBeamHeadLightCmd "Command to activate or de-activate the tractor low beam head light lamps. 

00 De-activate
01 Activate
10 Reserved
11 Don’t Care";
CM_ SG_ 2365473278 AltBeamHeadLightCmd "Command to activate or de-activate the tractor alternate head lights (only low beam is available on alternate head lights).  The alternate position lights are intended for use with loader and snow plows that tend to block the primary head lights.
 ...";
CM_ SG_ 2365473278 RunningLightCmd "Command to activate or de-activate the tractor or powered vehicle running lights.  Usually only used for on road vehicles.

00 De-activate
01 Activate
10 Reserved
11 Don’t Care";
CM_ BO_ 2365485822 "Laser Leveling System Blade Control";
CM_ SG_ 2365485822 LandLevelingSystemEnableStatus "Communicate the enable/disable status of the Land Leveling System.

00 = Disabled
01= Enabled
10 = Error
11 = Not available / Not installed";
CM_ SG_ 2365485822 BladeCtrlModeRight "Indicate if the land leveling system's automatic control is active or inactive for the elevation sensor on the right side of the blade.  The \"left\" notation is applicable to grading machines such tractors and motor graders where \"right\" is the ...";
CM_ SG_ 2365485822 BladeCtrlModeLeft "Indicate if the land leveling system's automatic control is active or inactive for the elevation sensor on the left side of the blade.  The \"left\" notation is applicable to grading machines such tractors and motor graders where \"left\" is the ...";
CM_ SG_ 2365485822 BladeCtrlMode "Allows the user to select the type of blade control for the land leveling system.  

00000000 Manual mode
00000001 Automatic mode
00000010 Inactive automatic mode
All other values Reserved";
CM_ SG_ 2365485822 BladeDurationAndDirection "Used to indicate the duration and direction that the land leveling system blade moves.";
CM_ BO_ 2633926654 "Ignition Timing 6";
CM_ SG_ 2633926654 EngActualIgntTiming "The actual ignition timing at the current engine conditions. This parameter may or may not be equal to one of the desired timing parameters (see SPNs 1433-1435), depending on the status of the engine. Positive values indicate an increasingly ...";
CM_ SG_ 2633926654 EngDesiredIgntTiming3 "A programmable timing value specific to the engine’s application. Factors affecting this value include both fuel type and the nature of the load being driven. Positive values indicate an increasingly advanced timing from TDC.";
CM_ SG_ 2633926654 EngDesiredIgntTiming2 "A programmable timing value specific to the engine’s application. Factors affecting this value include both fuel type and the nature of the load being driven. Positive values indicate an increasingly advanced timing from TDC.";
CM_ SG_ 2633926654 EngDesiredIgntTiming1 "A programmable timing value specific to the engine’s application. Factors affecting this value include both fuel type and the nature of the load being driven. Positive values indicate an increasingly advanced timing from TDC.";
CM_ BO_ 2633926398 "Ignition Timing 5";
CM_ SG_ 2633926398 EngCyl20IgntTiming "The ignition timing (SI engines) or main fuel injection timing (CI engines) of the cylinder. Positive values indicate an increasingly advanced timing from TDC.";
CM_ SG_ 2633926398 EngCyl19IgntTiming "The ignition timing (SI engines) or main fuel injection timing (CI engines) of the cylinder. Positive values indicate an increasingly advanced timing from TDC.";
CM_ SG_ 2633926398 EngCyl18IgntTiming "The ignition timing (SI engines) or main fuel injection timing (CI engines) of the cylinder. Positive values indicate an increasingly advanced timing from TDC.";
CM_ SG_ 2633926398 EngCyl17IgntTiming "The ignition timing (SI engines) or main fuel injection timing (CI engines) of the cylinder. Positive values indicate an increasingly advanced timing from TDC.";
CM_ BO_ 2633926142 "Ignition Timing 4";
CM_ SG_ 2633926142 EngCyl16IgntTiming "The ignition timing (SI engines) or main fuel injection timing (CI engines) of the cylinder. Positive values indicate an increasingly advanced timing from TDC.";
CM_ SG_ 2633926142 EngCyl15IgntTiming "The ignition timing (SI engines) or main fuel injection timing (CI engines) of the cylinder. Positive values indicate an increasingly advanced timing from TDC.";
CM_ SG_ 2633926142 EngCyl14IgntTiming "The ignition timing (SI engines) or main fuel injection timing (CI engines) of the cylinder. Positive values indicate an increasingly advanced timing from TDC.";
CM_ SG_ 2633926142 EngCyl13IgntTiming "The ignition timing (SI engines) or main fuel injection timing (CI engines) of the cylinder. Positive values indicate an increasingly advanced timing from TDC.";
CM_ BO_ 2633925886 "Ignition Timing 3";
CM_ SG_ 2633925886 EngCyl12IgntTiming "The ignition timing (SI engines) or main fuel injection timing (CI engines) of the cylinder. Positive values indicate an increasingly advanced timing from TDC.";
CM_ SG_ 2633925886 EngCyl11IgntTiming "The ignition timing (SI engines) or main fuel injection timing (CI engines) of the cylinder. Positive values indicate an increasingly advanced timing from TDC.";
CM_ SG_ 2633925886 EngCyl10IgntTiming "The ignition timing (SI engines) or main fuel injection timing (CI engines) of the cylinder. Positive values indicate an increasingly advanced timing from TDC.";
CM_ SG_ 2633925886 EngCyl9IgntTiming "The ignition timing (SI engines) or main fuel injection timing (CI engines) of the cylinder. Positive values indicate an increasingly advanced timing from TDC.";
CM_ BO_ 2633925630 "Ignition Timing 2";
CM_ SG_ 2633925630 EngCyl8IgntTiming "The ignition timing (SI engines) or main fuel injection timing (CI engines) of the cylinder. Positive values indicate an increasingly advanced timing from TDC.";
CM_ SG_ 2633925630 EngCyl7IgntTiming "The ignition timing (SI engines) or main fuel injection timing (CI engines) of the cylinder. Positive values indicate an increasingly advanced timing from TDC.";
CM_ SG_ 2633925630 EngCyl6IgntTiming "The ignition timing (SI engines) or main fuel injection timing (CI engines) of the cylinder. Positive values indicate an increasingly advanced timing from TDC.";
CM_ SG_ 2633925630 EngCyl5IgntTiming "The ignition timing (SI engines) or main fuel injection timing (CI engines) of the cylinder. Positive values indicate an increasingly advanced timing from TDC.";
CM_ BO_ 2633925374 "Ignition Timing 1";
CM_ SG_ 2633925374 EngCyl4IgntTiming "The ignition timing (SI engines) or main fuel injection timing (CI engines) of the cylinder. Positive values indicate an increasingly advanced timing from TDC.";
CM_ SG_ 2633925374 EngCyl3IgntTiming "The ignition timing (SI engines) or main fuel injection timing (CI engines) of the cylinder. Positive values indicate an increasingly advanced timing from TDC.";
CM_ SG_ 2633925374 EngCyl2IgntTiming "The ignition timing (SI engines) or main fuel injection timing (CI engines) of the cylinder. Positive values indicate an increasingly advanced timing from TDC.";
CM_ SG_ 2633925374 EngCyl1IgntTiming "The ignition timing (SI engines) or main fuel injection timing (CI engines) of the cylinder. Positive values indicate an increasingly advanced timing from TDC.";
CM_ BO_ 2633927422 "Ignition Transformer Secondary Output 3";
CM_ SG_ 2633927422 EngCyl20IgntTransSecondOutput "This parameter indicates the relative intensity of the secondary output voltage of the ignition transformer.";
CM_ SG_ 2633927422 EngCyl19IgntTransSecondOutput "This parameter indicates the relative intensity of the secondary output voltage of the ignition transformer.";
CM_ SG_ 2633927422 EngCyl18IgntTransSecondOutput "This parameter indicates the relative intensity of the secondary output voltage of the ignition transformer.";
CM_ SG_ 2633927422 EngCyl17IgntTransSecondOutput "This parameter indicates the relative intensity of the secondary output voltage of the ignition transformer.";
CM_ BO_ 2633927166 "Ignition Transformer Secondary Output 2";
CM_ SG_ 2633927166 EngCyl16IgntTransSecondOutput "This parameter indicates the relative intensity of the secondary output voltage of the ignition transformer.";
CM_ SG_ 2633927166 EngCyl15IgntTransSecondOutput "This parameter indicates the relative intensity of the secondary output voltage of the ignition transformer.";
CM_ SG_ 2633927166 EngCyl14IgntTransSecondOutput "This parameter indicates the relative intensity of the secondary output voltage of the ignition transformer.";
CM_ SG_ 2633927166 EngCyl13IgntTransSecondOutput "This parameter indicates the relative intensity of the secondary output voltage of the ignition transformer.";
CM_ SG_ 2633927166 EngCyl12IgntTransSecondOutput "This parameter indicates the relative intensity of the secondary output voltage of the ignition transformer.";
CM_ SG_ 2633927166 EngCyl11IgntTransSecondOutput "This parameter indicates the relative intensity of the secondary output voltage of the ignition transformer.";
CM_ SG_ 2633927166 EngCyl10IgntTransSecondOutput "This parameter indicates the relative intensity of the secondary output voltage of the ignition transformer.";
CM_ SG_ 2633927166 EngCyl9IgntTransSecondOutput "This parameter indicates the relative intensity of the secondary output voltage of the ignition transformer.";
CM_ BO_ 2633926910 "Ignition Transformer Secondary Output 1";
CM_ SG_ 2633926910 EngCyl8IgntTransSecondOutput "This parameter indicates the relative intensity of the secondary output voltage of the ignition transformer.";
CM_ SG_ 2633926910 EngCyl7IgntTransSecondOutput "This parameter indicates the relative intensity of the secondary output voltage of the ignition transformer.";
CM_ SG_ 2633926910 EngCyl6IgntTransSecondOutput "This parameter indicates the relative intensity of the secondary output voltage of the ignition transformer.";
CM_ SG_ 2633926910 EngCyl5IgntTransSecondOutput "This parameter indicates the relative intensity of the secondary output voltage of the ignition transformer.";
CM_ SG_ 2633926910 EngCyl4IgntTransSecondOutput "This parameter indicates the relative intensity of the secondary output voltage of the ignition transformer.";
CM_ SG_ 2633926910 EngCyl3IgntTransSecondOutput "This parameter indicates the relative intensity of the secondary output voltage of the ignition transformer.";
CM_ SG_ 2633926910 EngCyl2IgntTransSecondOutput "This parameter indicates the relative intensity of the secondary output voltage of the ignition transformer.";
CM_ SG_ 2633926910 EngCyl1IgntTransSecondOutput "This parameter indicates the relative intensity of the secondary output voltage of the ignition transformer.";
CM_ BO_ 2566768894 "The Operator Primary Intermediate Speed Control State is used to provide the controller feedback to indicate the controls state achieved.";
CM_ SG_ 2566768894 EngOprtrPrmryIntrmdtSpdSlctState "13 preprogrammed intermediate speed control settings are available for the controlling ECM to select.  If no speed setting is requested, the engine operates normally. The Intermediate Speed Control is widely used in the Industrial application to ...";
CM_ BO_ 2566769406 "The Intermediate Speed Control is widely used in the Industrial application to control the engine to an intermediate speed setting which can bypass the accelerator position control. An example of this operation would be in an agricultural ...";
CM_ SG_ 2566769406 EngOprtrPrmryIntrmdteSpeedSelect "Allows the operator to select one of 13 preprogrammed Intermediate Speed Control settings. If no speed setting is requested, the engine operates normally. The Intermediate Speed Control is widely used in the Industrial application to control the ...";
CM_ BO_ 2566839550 "Idle Operation";
CM_ SG_ 2566839550 EngTotalIdleHours "Accumulated time of operation of the engine while under idle conditions.";
CM_ SG_ 2566839550 EngTotalIdleFuelUsed "Accumulated amount of fuel used during vehicle operation while under idle conditions.";
CM_ BO_ 2633934334 "Intake Manifold Information 2";
CM_ SG_ 2633934334 EngIntakeManifold6Temp "Temperature of pre-combustion air found in intake manifold  number 6 of engine air supply system.";
CM_ SG_ 2633934334 EngIntakeManifold5Temp "Temperature of pre-combustion air found in intake manifold number 5 of engine air supply system.";
CM_ SG_ 2633934334 EngIntakeManifold4Temp "Temperature of pre-combustion air found in intake manifold of engine air supply system.";
CM_ SG_ 2633934334 EngIntakeManifold3Temp "Temperature of pre-combustion air found in intake manifold of engine air supply system.";
CM_ SG_ 2633934334 EngIntakeManifold2Temp "Temperature of pre-combustion air found in intake manifold of engine air supply system.";
CM_ BO_ 2566825726 "Intake Manifold Information 1";
CM_ SG_ 2566825726 EngTurbo4BoostPress "Gage pressure of air measured downstream of the compressor discharge side of the turbocharger.  See also SPN 102 for alternate range and resolution. If there is only one boost pressure to report and the range and resolution in SPN 102 is adequate, ...";
CM_ SG_ 2566825726 EngTurbo3BoostPress "Gage pressure of air measured downstream of the compressor discharge side of the turbocharger.  See also SPN 102 for alternate range and resolution. If there is only one boost pressure to report and the range and resolution in SPN 102 is adequate, ...";
CM_ SG_ 2566825726 EngTurbo2BoostPress "Gage pressure of air measured downstream of the compressor discharge side of the turbocharger.  See also SPN 102 for alternate range and resolution. If there is only one boost pressure to report and the range and resolution in SPN 102  is adequate, ...";
CM_ SG_ 2566825726 EngTurbo1BoostPress "Gage pressure of air measured downstream of the compressor discharge side of the turbocharger.  See also SPN 102 for alternate range and resolution. If there is only one boost pressure to report and the range and resolution in SPN 102 is adequate, ...";
CM_ BO_ 2566770942 "Intake/Exhaust Conditions 2 is a second PGN conveying this type of engine information. Also see PGN 65270.";
CM_ SG_ 2566770942 EngIntakeManifold2AbsPress "The absolute pressure measurement of the air intake manifold for bank 2 or the second air intake manifold. If there are multiple air pressure sensors in the intake stream, this is the last one in flow direction before entering the combustion ...";
CM_ SG_ 2566770942 EngIntakeManifold1AbsPress4817 "The absolute pressure measurement of the air intake manifold. If there are multiple air pressure sensors in the intake stream, this is the last one in flow direction before entering the combustion chamber.  This SPN is a high resolution measurement ...";
CM_ SG_ 2566770942 EngIntakeManifold1AbsPress "The absolute pressure measurement of the air intake manifold. If there are multiple air pressure sensors in the intake stream, this is the last one in flow direction before entering the combustion chamber.";
CM_ SG_ 2566770942 EngIntakeManifold2Press "The gage pressure measurement of the air intake manifold for bank #2 or the second air intake manifold. If there are multiple air pressure sensors in the second intake stream, this is the last one in flow direction before entering the combustion ...";
CM_ SG_ 2566770942 EngAirFilter4DiffPress "Change in engine air system pressure, measured across the fourth air filter, due to the filter and any accumulation of solid foreign matter on or in the filter.
This is for monitoring the air filter on the intake to the fourth turbocharger. Filter ...";
CM_ SG_ 2566770942 EngAirFilter3DiffPress "Change in engine air system pressure, measured across the third air filter, due to the filter and any accumulation of solid foreign matter on or in the filter.
This is for monitoring the air filter on the intake to the third turbocharger. Filter ...";
CM_ SG_ 2566770942 EngAirFilter2DiffPress "Change in engine air system pressure, measured across the second air filter, due to the filter and any accumulation of solid foreign matter on or in the filter.
This is for monitoring the air filter on the intake to the second turbocharger. Filter ...";
CM_ BO_ 2566846206 "Intake/Exhaust Conditions 1";
CM_ SG_ 2566846206 EngCoolantFilterDiffPress "Change in coolant pressure, measured across the filter, due to the filter and any accumulation of solid or semisolid matter on or in the filter.";
CM_ SG_ 2566846206 EngExhaustGasTemp "Temperature of combustion byproducts leaving the engine.  See SPNs 2433, 2434, 5969 and 5970 for engines with more than one exhaust temperature measurement.";
CM_ SG_ 2566846206 EngAirFilter1DiffPress "Change in engine air system pressure, measured across the filter, due to the filter and any accumulation of solid foreign matter on or in the filter.
This is the measurement of the first filter in a multiple air filter system.  In a single air ...";
CM_ SG_ 2566846206 EngAirIntakePress "Absolute air pressure at input port to intake manifold or air box.";
CM_ SG_ 2566846206 EngIntakeManifold1Temp "Temperature of pre-combustion air found in intake manifold of engine air supply system.";
CM_ SG_ 2566846206 EngIntakeManifold1Press "The gage pressure measurement of the air intake manifold. If there are multiple air pressure sensors in the intake stream, this is the last one in flow direction before entering the combustion chamber.  This should be the pressure used to drive ...";
CM_ SG_ 2566846206 AT1DslPrtculateFilterIntakePress "Exhaust pressure as a result of particle accumulation on filter media placed in the exhaust stream.  It is recommended that SPN 3609 be used as it has better resolution.";
CM_ BO_ 2566811134 "Heater Information";
CM_ SG_ 2566811134 ADRCompliantHeaterInstallation "Indicates that the heater is installed in an ADR compliant vehicle.
00 -  Heater installation is not ADR compliant
01 -  Heater installation is ADR compliant
10 -  Error
11 -  Not Available
Note:  ADR is a European agreement concerning the ...";
CM_ SG_ 2566811134 CabHeatingZone "Parameter indicating whether the cab zone is being heated.

00 Cab heating zone off
01 Cab heating zone on
10 Reserved
11 Not available";
CM_ SG_ 2566811134 EngHeatingZone "Parameter indicating whether the engine zone is being heated.

00 Engine heating zone off
01 Engine heating zone on
10 Reserved
11 Not available";
CM_ SG_ 2566811134 CabVentilation "Indicates whether the cab is being ventilated or not.

00 Cab not ventilated
01 Cab is ventilated
10 Reserved
11 Not available";
CM_ SG_ 2566811134 AuxHeaterWaterPumpStatus "Parameter indicating whether the auxiliary heater water pump is running

00 Water Pump is not running
01 Water Pump is  running
10 Reserved
11 Not available";
CM_ SG_ 2566811134 AuxHeaterMode "State of the auxiliary heater
0000 Heater not active
0001 Off due to ADR per European Regulations for Transport of hazardous materials
0010 Economy mode
0011 Normal mode
0100 Heater pump up-keep   (running the equipment in order to keep it in ...";
CM_ SG_ 2566811134 AuxHeaterOutputPowerPercent "Current auxiliary heater output power, relative to the auxiliary heater maximum output power.";
CM_ SG_ 2566811134 AuxHeaterInputAirTemp "Temperature of the input air in an auxiliary heater system.";
CM_ SG_ 2566811134 AuxHeaterOutputCoolantTemp "Temperature of the auxiliary heater output coolant (I.e. water in a water heater system.)";
CM_ BO_ 2298375934 "High Resolution Wheel Speed";
CM_ SG_ 2298375934 RearAxleRightWheelSpeed "High resolution measurement of the speed of the right wheel on the rear axle.";
CM_ SG_ 2298375934 RearAxleLeftWheelSpeed "High resolution measurement of the speed of the left wheel on the rear axle.";
CM_ SG_ 2298375934 FrontAxleRightWheelSpeed "High resolution measurement of the speed of the right wheel on the front axle.";
CM_ SG_ 2298375934 FrontAxleLeftWheelSpeed "High resolution measurement of the speed of the left wheel on the front axle.";
CM_ BO_ 2565867774 "Information to be used for a hydraulic pressure governing control system";
CM_ SG_ 2565867774 FireApparatusPumpEngagement "The measured status of the pump used to provide water in fire fighting apparatus for distribution of water through water cannons or fire hoses.

00 Pump not engaged
01 Pump engaged
10 Error
11 Not available or not installed";
CM_ SG_ 2565867774 HydPressGovernorPresetSwitch "Switch that commands hydraulic pressure governor to increase or decrease engine rpm to achieve a predefined discharge pressure.

00 Preset Switch Inactive
01 Preset Switch Active
10 Error
11 Not available";
CM_ SG_ 2565867774 HydPressGovernorIncreaseSwitch "Switch that commands hydraulic pressure governor to increase engine rpm resulting in expected increase of hydraulic discharge pressure.

00 Increase Switch Inactive
01 Increase Switch Active
10 Error
11 Not available";
CM_ SG_ 2565867774 HydPressGovernorDecreaseSwitch "Switch that commands hydraulic pressure governor to decrease engine rpm resulting in expected decrease of hydraulic discharge pressure.

00 Decrease Switch Inactive
01 Decrease Switch Active
10 Error
11 Not available";
CM_ SG_ 2565867774 HydPressGovernorIdleSwitch "Switch that commands hydraulic pressure governor to decrease engine rpm to its idle position.

00 Idle Switch Inactive
01 Idle Switch Active
10 Error
11 Not available";
CM_ SG_ 2565867774 HydDischargePressSetPoint "Hydraulic pressure governing system discharge pressure set point.";
CM_ SG_ 2565867774 HydIntakePress "Hydraulic pressure measured at the intake of the hydraulic pump.";
CM_ SG_ 2565867774 FireApparatusOkayToPumpInterlock "The measured state of the Okay To Pump interlock of the fire apparatus.
00 Okay to Pump Interlock Inactive
01 Okay to Pump Interlock Active
10 Error
11 Not Available
Note: \"Okay to Pump\" is incorporated into the NFPA 1901 Standard for Fire ...";
CM_ SG_ 2565867774 EngHydPressGovernorSwitch "Switch that sets the  mode of hydraulic governor

00 Pressure Mode Inactive
01 Pressure Mode Active
10 Error Indicator
11 Not Available";
CM_ SG_ 2565867774 EngHydPressGovernorModeIndicator "Mode for governor operation is hydraulic pressure control.

00 Disabled
01 Enabled
10 Error Indicator
11 Not Available";
CM_ SG_ 2565867774 HydPress "Hydraulic pressure measured at the output of the hydraulic pump.";
CM_ BO_ 2566841854 "Engine Hours, Revolutions";
CM_ SG_ 2566841854 EngTotalRevolutions "Accumulated number of revolutions of engine crankshaft during its operation.";
CM_ SG_ 2566841854 EngTotalHoursOfOperation "Accumulated time of operation of engine.";
CM_ BO_ 2365449982 "Used for information on a hydraulic brake system
As an example: this PGN may be used for a two circuit hydraulic brake system with separate circuits for front and rear axle. The hydraulic energy is supplied via two independent electrically driven ...";
CM_ SG_ 2365449982 HydBrakeFluidLevelSwitch "Signal which indicates whether the hydraulic fluid level in the reservoir(s) is sufficient.

00      Fluid level is not sufficient
01      Fluid level is sufficient
10      Error indicator
11      Not available";
CM_ SG_ 2365449982 HydBrakeSystemAudibleWarningCmd "Signal which commands an audible warning by the hydraulic braking system.

00       Audible warning off
01       Audible warning on
10       Reserved
11       Don't care";
CM_ SG_ 2365449982 HydBrakePressSupplyStateCircuit2 "Signal which indicates whether the hydraulic brake pressure supply of circuit 2 is reliable; that is, able to support continued braking.

00 Supply is not reliable
01 Supply is reliable
10 Error indicator
11 Not available";
CM_ SG_ 2365449982 HydBrakePressSupplyStateCircuit1 "Signal which indicates whether the hydraulic brake pressure supply of circuit 1 is reliable; that is, able to support continued braking.

00 Supply is not reliable
01 Supply is reliable
10 Error indicator
11 Not available";
CM_ SG_ 2365449982 HydBrkePressWarningStateCircuit2 "Signal which indicates whether the hydraulic brake pressure of circuit 2 is below the warning level

00 Pressure level sufficient
01 Pressure level below warning level
10 Error indicator
11 Not available";
CM_ SG_ 2365449982 HydBrkePressWarningStateCircuit1 "Signal which indicates whether the hydraulic brake pressure of circuit 1 is below the warning level

00 Pressure level sufficient
01 Pressure level below warning level
10 Error indicator
11 Not available";
CM_ SG_ 2365449982 HydBrakePressCircuit2 "Gage hydraulic pressure in circuit 2 of the hydraulic brake system";
CM_ SG_ 2365449982 HydBrakePressCircuit1 "Gage hydraulic pressure in circuit 1 of the hydraulic brake system";
CM_ BO_ 2633939198 "Trip Fuel Information (Gaseous)";
CM_ SG_ 2633939198 TripDriveFuelEconomy "Trip drive fuel economy is equal to the distance traveled by vehicle in the drive state (engine speed greater than zero, vehicle speed greater than or equal to 2 km/h, and neither the PTO or remote PTO governors are controlling engine power output) ...";
CM_ SG_ 2633939198 TripCruiseFuelUsed "Total fuel consumed while the engine is in the cruise hold state since the last trip reset.  If both cruise control and VSL (vehicle speed limiter) are commanding the same amount of fuel, the cruise control is deemed the active torque mode and fuel ...";
CM_ SG_ 2633939198 TripVehicleIdleFuelUsed "Total fuel consumed while neither the PTO or remote PTO governors are active, the engine speed is greater than zero, and vehicle speed is less than to 2 km/h, since the last trip reset.
NOTE—This parameter is intended for gaseous fueled engines ...";
CM_ SG_ 2633939198 TripPTOGovernorNonmovingFuelUsed "Total fuel consumed while the PTO or remote PTO governors are in the hold state, the engine speed is greater than zero, and vehicle speed is less than to 2 km/h, since the last trip reset.
NOTE—This parameter is intended for gaseous fueled engines ...";
CM_ SG_ 2633939198 TripPTOGovernorMovingFuelUsed "Total fuel consumed while the PTO or remote PTO governors are in the hold state, the engine speed is greater than zero, and vehicle speed is greater than or equal to 2 km/h, since the last trip reset.
NOTE—This parameter is intended for gaseous ...";
CM_ SG_ 2633939198 TripDriveFuelUsed "Total fuel consumed while the engine speed is greater than zero, vehicle speed is greater than or equal to 2 km/h, and neither the PTO or the remote PTO governors are controlling the engine power output, since the last trip reset.
NOTE—This ...";
CM_ BO_ 2633927678 "Gaseous Fuel Pressure";
CM_ SG_ 2633927678 EngFuelValve1OutletAbsPress "Absolute Pressure of gas on outlet side of the first or only fuel system control valve.  See SPN 3469 for the second fuel control valve.";
CM_ SG_ 2633927678 EngAirToFuelDiffPress "The differential pressure between the gaseous fuel and the air intake manifold.";
CM_ SG_ 2633927678 EngFuelValveDiffPress "The differential pressure between the intake and the outlet of the first or only gaseous fuel valve.";
CM_ SG_ 2633927678 EngFuelValve1IntakeAbsPress "The absolute pressure of gas on the intake side of the first system control valve.  See SPN 3466 for Engine Fuel Valve 2, 7505 for Engine Fuel Valve 3 & 7506 for Engine Fuel Valve 4.";
CM_ BO_ 2633925118 "Gaseous fuel information 2";
CM_ SG_ 2633925118 EngRequestedFuelValve2Pos "The commanded position of the second fuel valve that is metering the fuel flow to the engine.";
CM_ SG_ 2633925118 EngRequestedFuelValve1Pos "The commanded position of the first fuel valve that is metering the fuel flow to the engine.";
CM_ SG_ 2633925118 EngFuelValve2Pos "The position of a gaseous fuel valve that is metering the fuel flow to the engine.  0% indicates no fuel flow through valve and 100% means maximum fuel flow through valve.";
CM_ SG_ 2633925118 EngFuelValve1Pos "The position of a gaseous fuel valve that is metering the fuel flow to the engine.  0% indicates no fuel flow through valve and 100% means maximum fuel flow through valve.";
CM_ SG_ 2633925118 EngFuelFlowRate2 "The rate at which the fuel is flowing through a fuel valve.";
CM_ SG_ 2633925118 EngFuelFlowRate1 "The rate at which the fuel is flowing through a fuel valve.";
CM_ BO_ 2633937662 "Fuel Information 1 (Gaseous)";
CM_ SG_ 2633937662 EngFuelSpecificGravity "This parameter conveys the specific gravity of the gaseous fuel being used by the engine.  The specific gravity of the fuel can then be used to compute the density of the fuel.";
CM_ SG_ 2633937662 TripAverageFuelRate "Average fuel rate, equal to trip fuel divided by trip time while the engine speed is above zero, since the last trip reset.  This includes idle, engine PTO governor (both moving and non-moving) and drive operation but excludes ignition-on time while ...";
CM_ SG_ 2633937662 TotalEngPTOGovernorFuelUsed "Total fuel used while the PTO or remote PTO governors are in the hold state and engine speed is above zero, over the life of the engine.

NOTE—This parameter is intended for gaseous fueled engines.  See SPN 1028 for alternate resolution.";
CM_ BO_ 2566804990 "Gaseous Fuel Properties";
CM_ SG_ 2566804990 FuelEnergyContent "Energy content (lower heating value) of the gaseous fuel.
Note:  For gaseous fuels, the fuel's energy content (lower heating value) is commonly defined in terms of energy / volume. The gas volume is defined for regular pressure and temperature ...";
CM_ SG_ 2566804990 ReferenceEngGasMassFlowRate "Configuration of the mass flow rate of gaseous fuel expected for 100% engine fuel valve control command.
Note:  The actuator will request this parameter from the ECU in order to determine what mass fuel flow to associate with a command of 100% from ...";
CM_ SG_ 2566804990 SpecificHeatRatio "The specific heat ratio of the fuel.";
CM_ BO_ 2633936894 "Fuel Consumption (Gaseous)";
CM_ SG_ 2633936894 TotalFuelUsed "Total fuel consumed (trip drive fuel + trip PTO governor moving fuel + trip PTO governor non-moving fuel + trip idle fuel) over the life of the engine.";
CM_ SG_ 2633936894 TripFuel "Total fuel consumed (trip drive fuel + trip PTO governor moving fuel + trip PTO governor non-moving fuel + trip idle fuel) since the last trip reset.";
CM_ BO_ 2566757630 "Voltage supplies for sensors #2";
CM_ SG_ 2566757630 SensorSupplyVoltage8 "Sensor ECU supply voltage 8";
CM_ SG_ 2566757630 SensorSupplyVoltage7 "Sensor ECU supply voltage 7";
CM_ SG_ 2566757630 SensorSupplyVoltage6 "Sensor ECU supply voltage 6";
CM_ SG_ 2566757630 SensorSupplyVoltage5 "Sensor ECU supply voltage 5";
CM_ BO_ 2566757886 "Voltage supplies for sensors #1";
CM_ SG_ 2566757886 SensorSupplyVoltage4 "Sensor ECU supply voltage 4";
CM_ SG_ 2566757886 SensorSupplyVoltage3 "Sensor ECU supply voltage 3";
CM_ SG_ 2566757886 SensorSupplyVoltage2 "Sensor ECU supply voltage 2";
CM_ SG_ 2566757886 SensorSupplyVoltage1 "Sensor ECU supply voltage 1";
CM_ BO_ 2566759678 "Information relating to the request for engagement, consent for engagement, and status of engagement of various specific physical PTO drives.  This message may be broadcast by one or all controllers involved in the enabling of a given PTO drive.";
CM_ SG_ 2566759678 AtLeastOnePTOEngaged "Indicates that at least one PTO is engaged
00 No PTO drive is engaged
01 At least one PTO drive is engaged
10 Error
11 Not available
Note:  This parameter should only be sent by the controller that has knowledge of all PTO drives on the vehicle ...";
CM_ SG_ 2566759678 EnggmntSttsPTOEngAccessoryDrive2 "Engagement status of the PTO engine accessory drive 2

00 Drive not engaged
01 Drive engaged
10 Error
11 Not available";
CM_ SG_ 2566759678 EnggmntSttsPTOEngAccessoryDrive1 "Engagement status of the PTO engine accessory drive 1

00 Drive not engaged
01 Drive engaged
10 Error
11 Not available";
CM_ SG_ 2566759678 EngagementStatusPTOEngFlywheel "Engagement status of the PTO Engine Flywheel

00 Drive not engaged
01 Drive engaged
10 Error
11 Not available";
CM_ SG_ 2566759678 EnggmntStatusTransInputShaftPTO1 "Reports if this specific PTO drive is engaged.  This parameter should be broadcast only by the controller(s) receiving feedback about the specific drive.
For example, a pressure switch may be used to determine if a PTO-driven pump has been engaged ...";
CM_ SG_ 2566759678 EnggmntStatusTransInputShaftPTO2 "Reports if this specific PTO drive is engaged.  This parameter should be broadcast only by the controller(s) receiving feedback about the specific drive.
For example, a pressure switch may be used to determine if a PTO-driven pump has been engaged ...";
CM_ SG_ 2566759678 EnggmntStatusTransOutputShaftPTO "Reports if this specific PTO drive is engaged.  This parameter should be broadcast only by the controller(s) receiving feedback about the specific drive.
For example, a pressure switch may be used to determine if a PTO-driven pump has been engaged ...";
CM_ SG_ 2566759678 EnggmntSttsTrnsfrCsOtputShaftPTO "Reports if this specific PTO drive is engaged.  This parameter should be broadcast only by the controller(s) receiving feedback about the specific drive.
For example, a pressure switch may be used to determine if a PTO-driven pump has been engaged ...";
CM_ SG_ 2566759678 EnggmntCnsntPTOEngAccssoryDrive2 "Engagement Consent status for the PTO engine accessory drive 2 

00 Consent not given – PTO drive may not be engaged
01 Consent given – PTO drive may be engaged
10 Error
11 Not available";
CM_ SG_ 2566759678 EnggmntCnsntPTOEngAccssoryDrive1 "Engagement consent status for the PTO engine accessory drive 1

00 Consent not given – PTO drive may not be engaged
01 Consent given – PTO drive may be engaged
10 Error
11 Not available";
CM_ SG_ 2566759678 EngagementConsentPTOEngFlywheel "Engagement Consent status for the PTO Engine Flywheel

00 Consent not given – PTO drive may not be engaged
01 Consent given – PTO drive may be engaged
10 Error
11 Not available";
CM_ SG_ 2566759678 EnggmntCnsentTransInputShaftPTO1 "Status of the transmission controller’s consent to engage the first or sole PTO drive mounted on the transmission case.  The controller in charge of the PTO drive should monitor this parameter and only engage the drive when consent is given.  If ...";
CM_ SG_ 2566759678 EnggmntCnsentTransInputShaftPTO2 "Status of the transmission controller’s consent to engage the second PTO drive mounted on the transmission case.  The controller in charge of the PTO drive should monitor this parameter and only engage the drive when consent is given.  If consent is ...";
CM_ SG_ 2566759678 EnggmntCnsentTransOutputShaftPTO "Status of the transmission controller’s consent to engage the PTO drive connected to the transmission output shaft.  The controller in charge of the PTO drive should monitor this parameter and only engage the drive when consent is given.  If consent ...";
CM_ SG_ 2566759678 EnggmntCnsntTrnsfrCsOtptShaftPTO "Status of the transmission controller’s consent to engage the PTO drive connected to the transfer case output shaft.  The controller in charge of the PTO drive should monitor this parameter and only engage the drive when consent is given.  If ...";
CM_ SG_ 2566759678 EnbleSwitchPTOEngAccessoryDrive2 "Status of the PTO engine accessory drive 2 enable switch

00 Enable switch off – PTO operation not desired
01 Enable switch on – PTO operation desired
10 Error
11 Not available";
CM_ SG_ 2566759678 EnbleSwitchPTOEngAccessoryDrive1 "Status of the PTO engine accessory drive 1 enable switch

00 Enable switch off – PTO operation not desired
01 Enable switch on – PTO operation desired
10 Error
11 Not available";
CM_ SG_ 2566759678 EnableSwitchPTOEngFlywheel "Status of the PTO Engine Flywheel enable switch

00 Enable switch off – PTO operation not desired
01 Enable switch on – PTO operation desired 
10 Error
11 Not available";
CM_ SG_ 2566759678 EnableSwitchTransInputShaftPTO1 "Status of the operator’s switch or other input which indicates the desire for engaging the first PTO drive mounted on the transmission case.  There may be more than one PTO drive mounted on the transmission case.
00   Enable switch off – PTO ...";
CM_ SG_ 2566759678 EnableSwitchTransInputShaftPTO2 "Status of the operator’s switch or other input which indicates the desire for engaging the second PTO drive mounted on the transmission case.   If there is only one PTO drive on the transmission case, use SPN 3452 Enable Switch – Transmission input ...";
CM_ SG_ 2566759678 EnableSwitchTransOutputShaftPTO "Status of the operator’s switch or other input which indicates the desire for engaging the PTO drive mounted on the transmission output shaft.
00   Enable switch off – PTO operation not desired
01   Enable switch on – PTO operation desired
10 ...";
CM_ SG_ 2566759678 EnblSwtchTrnsfrCseOutputShaftPTO "Status of the operator’s switch or other input which indicates the desire for engaging the PTO drive mounted on the output shaft of the transfer case.
00   Enable switch off – PTO operation not desired
01   Enable switch on – PTO operation desired
 ...";
CM_ BO_ 2432541438 "Gaseous fuel information 3";
CM_ SG_ 2432541438 EngFuelValve2OutletAbsPress "Absolute pressure of gas on outlet side of the second fuel system control valve.  See SPN 2980 for the first or only fuel system control valve.";
CM_ SG_ 2432541438 EngFuelTemp2 "Temperature 2 of fuel (or gas).   See SPN 174 for fuel temperature 1.";
CM_ SG_ 2432541438 EngGas2MassFlowRate "Gas mass flow rate delivered to an engine through its second fuel control system, using standard convention for determining position.
In a system with two fuel system control valves, left/front is #1 (SPN 1241) and right/rear is #2 (SPN 3467).
In ...";
CM_ SG_ 2432541438 EngFuelValve2IntakeAbsPress "Absolute pressure of gas on intake side of the second fuel system control valve, using standard convention for determining position.
In a system with two fuel system control valves, left/front is #1 (SPN 1390) and right/rear is #2 (SPN 3466).
In a ...";
CM_ BO_ 2566761214 "4th PGN which identifies parameters that are either measuring various pressures within the engine or identifying engine fluid levels";
CM_ SG_ 2566761214 EngChargeAirCoolerOutletPress "Measures pressure of air at outlet from charge air cooler";
CM_ SG_ 2566761214 EngAftercoolerCoolantLevel "Ratio of aftercooler coolant system volume of liquid to total cooling system volume.  The engine aftercooler coolant level is for  the low temperature (LT) cooling circuit used for the compressor outlet air or charge aftercooling.
SPN 111 \"Coolant ...";
CM_ SG_ 2566761214 EngIntercoolerCoolantLevel "Ratio of volume of liquid found in an engine charge air cooler cooling system to total engine charge air cooler cooling system volume.";
CM_ SG_ 2566761214 EngCentrifugalOilFilterSpeed "The speed of a rotating (centrifugal) engine oil filter.";
CM_ SG_ 2566761214 EngCoolantPumpDiffPress "The differential pressure measured across the input and output of the engine coolant pump.";
CM_ SG_ 2566761214 EngChargeAirCooler2IntakePress "Pressure of air at intake to 2nd charge air cooler, from multiple first stage turbochargers being cooled and feeding multiple second stage turbochargers.";
CM_ SG_ 2566761214 EngChargeAirCooler1IntakePress "Pressure of air at intake to 1st or only charge air cooler, from multiple first stage turbochargers being cooled and feeding multiple second stage turbochargers.";
CM_ BO_ 2432541694 "Engine related parameters";
CM_ SG_ 2432541694 EngVriableGeometryTurboActuator1 "Actuator that controls the variable geometry turbocharger geometry.The control command to the actuator, normalized to percent, where 0% nominally represents fully closed (smallest turbocharger geometry) and 100% represents fully open (largest ...";
CM_ SG_ 2432541694 EngTrbCmprssrBypssActtr1TmpSttus "Used to identify the status of the Engine Turbocharger Compresssor Bypass Actuator 1 drive circuitry temperature.  Temperature excursions may affect the torque output.
000 – High Most severe
001 – High Least severe
010 – In Range
011 – Low Least ...";
CM_ SG_ 2432541694 EngTrbCmprssrBypssActtr1PrlmnryF "Used to identify  the appplicable J1939-73 FMI detected in the Engine Turbocharger Compressor Bypass Actuator 1 by the manufacturers software. When there is no failure FMI 31 is transmitted. When there is multiple failures, the most severe is ...";
CM_ SG_ 2432541694 EngTrbCmprssorBypassActuator2Cmd "The command to a compressor bypass actuator 2, normalized to percent, where 0% nominally represents fully closed and 100% represents fully open. Typically, the turbocharger compressor bypass actuator is used to keep the engine out of surge by ...";
CM_ SG_ 2432541694 EngTrbCmprssorBypassActuator1Pos "Measures the position of the turbocharger compressor bypass actuator, where 0% represents bypass fully closed and 100% represents bypass fully open.  Typically, the compressor bypass is used to lower the compressor outlet pressure and/or intake ...";
CM_ SG_ 2432541694 EngTrbCmprssorBypassActuator1Cmd "The command to a compressor bypass actuator, normalized to percent, where 0% nominally represents fully closed and 100% represents fully open.  Typically, the turbocharger compressor bypass actuator is used to keep the engine out of surge by ...";
CM_ SG_ 2432541694 EngDsrdTrbCmprssrBypssActtor1Pos "The requested position of the Engine Turbocharger Compressor Bypass actuator by the engine ECU, where 0% represents bypass fully closed and 100% represents bypass fully open.

This is the position that the device is attempting to achieve.";
CM_ BO_ 2566759934 "Used for door information.";
CM_ SG_ 2566759934 EnableStatusOfDoor10 "Enable status of bus door 10.  Enabled means the bus doors are able to be automatically opened or closed.

00  door disabled
01  door enabled
10  error
11  not available";
CM_ SG_ 2566759934 OpenStatusOfDoor10 "Open status of bus door 10

00  door closed
01  door opened
10  error
11  not available";
CM_ SG_ 2566759934 LockStatusOfDoor10 "Lock status of bus door 10

00  unlocked 
01  locked
10  error
11  not available";
CM_ SG_ 2566759934 EnableStatusOfDoor9 "Enable status of bus door 9.  Enabled means the bus doors are able to be automatically opened or closed.

00  door disabled
01  door enabled
10  error
11  not available";
CM_ SG_ 2566759934 OpenStatusOfDoor9 "Open status of bus door 9

00  door closed
01  door opened
10  error
11  not available";
CM_ SG_ 2566759934 LockStatusOfDoor9 "Lock status of bus door 9

00  unlocked 
01  locked
10  error
11  not available";
CM_ SG_ 2566759934 EnableStatusOfDoor8 "Enable status of bus door 8.  Enabled means the bus doors are able to be automatically opened or closed.

00  door disabled
01  door enabled
10  error
11  not available";
CM_ SG_ 2566759934 OpenStatusOfDoor8 "Open status of bus door 8

00  door closed
01  door opened
10  error
11  not available";
CM_ SG_ 2566759934 LockStatusOfDoor8 "Lock status of bus door 8

00  unlocked 
01  locked
10  error
11  not available";
CM_ SG_ 2566759934 EnableStatusOfDoor7 "Enable status of bus door 7.  Enabled means the bus doors are able to be automatically opened or closed.

00  door disabled
01  door enabled
10  error
11  not available";
CM_ SG_ 2566759934 OpenStatusOfDoor7 "Open status of bus door 7

00  door closed
01  door opened
10  error
11  not available";
CM_ SG_ 2566759934 LockStatusOfDoor7 "Lock status of bus door 7

00  unlocked 
01  locked
10  error
11  not available";
CM_ SG_ 2566759934 EnableStatusOfDoor6 "Enable status of bus door 6.  Enabled means the bus doors are able to be automatically opened or closed.

00  door disabled
01  door enabled
10  error
11  not available";
CM_ SG_ 2566759934 OpenStatusOfDoor6 "Open status of bus door 6

00  door closed
01  door opened
10  error
11  not available";
CM_ SG_ 2566759934 LockStatusOfDoor6 "Lock status of bus door 6

00  unlocked 
01  locked
10  error
11  not available";
CM_ SG_ 2566759934 EnableStatusOfDoor5 "Enable status of bus door 5.  Enabled means the bus doors are able to be automatically opened or closed.

00  door disabled
01  door enabled
10  error
11  not available";
CM_ SG_ 2566759934 OpenStatusOfDoor5 "Open status of bus door 5

00  door closed
01  door opened
10  error
11  not available";
CM_ SG_ 2566759934 LockStatusOfDoor5 "Lock status of bus door 5

00  unlocked 
01  locked
10  error
11  not available";
CM_ SG_ 2566759934 EnableStatusOfDoor4 "Enable status of bus door 4.  Enabled means the bus doors are able to be automatically opened or closed.

00  door disabled
01  door enabled
10  error
11  not available";
CM_ SG_ 2566759934 OpenStatusOfDoor4 "Open status of bus door 4

00  door closed
01  door opened
10  error
11  not available";
CM_ SG_ 2566759934 LockStatusOfDoor4 "Lock status of bus door 4

00  unlocked 
01  locked
10  error
11  not available";
CM_ SG_ 2566759934 EnableStatusOfDoor3 "Enable status of bus door 3.  Enabled means the bus doors are able to be automatically opened or closed.

00  door disabled
01  door enabled
10  error
11  not available";
CM_ SG_ 2566759934 OpenStatusOfDoor3 "Open status of bus door 3

00  door closed
01  door opened
10  error
11  not available";
CM_ SG_ 2566759934 LockStatusOfDoor3 "Lock status of bus door 3

00  unlocked 
01  locked
10  error
11  not available";
CM_ SG_ 2566759934 EnableStatusOfDoor2 "Enable status of bus door 2.  Enabled means the bus doors are able to be automatically opened or closed.

00  door disabled
01  door enabled
10  error
11  not available";
CM_ SG_ 2566759934 OpenStatusOfDoor2 "Open status of bus door 2

00  door closed
01  door opened
10  error
11  not available";
CM_ SG_ 2566759934 LockStatusOfDoor2 "Lock status of bus door 2

00  unlocked 
01  locked
10  error
11  not available";
CM_ SG_ 2566759934 EnableStatusOfDoor1 "Enable status of bus door 1.  Enabled means the bus doors are able to be automatically opened or closed.

00  door disabled
01  door enabled
10  error
11  not available";
CM_ SG_ 2566759934 OpenStatusOfDoor1 "Open status of bus door 1

00  door closed
01  door opened
10  error
11  not available";
CM_ SG_ 2566759934 LockStatusOfDoor1 "Lock status of bus door 1

00  unlocked 
01  locked
10  error
11  not available";
CM_ BO_ 2566757374 "Sensor Information which measures temperature, concentration, and conductivity of the diesel exhaust fluid of the aftertreatment 1 system.";
CM_ SG_ 2566757374 DieselExhaustFluidSpeedOfSound "The speed of sound in the fluid that is in the diesel exhaust fluid tank.";
CM_ SG_ 2566757374 AT1DieselExhaustFluidProperty "This parameter indicates the property of the fluid compound in the tank.  A value of 0011 indicates uncontaminated Diesel Exhaust Fluid.
0000 - Urea concentration too high
0001 - Urea concentration too low
0010 - Fluid is diesel
0011 - Diesel ...";
CM_ SG_ 2566757374 AT1DslExhstFldPrprtsPrlminaryFMI "Used to identify the applicable J1939-73 FMI that applies to the most significant failure of the diesel exhaust fluid properties sensor.  This may be used for indicating failures of the diesel exhaust fluid concentration, diesel exhaust fluid ...";
CM_ SG_ 2566757374 AT1DslExhstFldTmp2PreliminaryFMI "Used to identify the applicable J1939-73 FMI that applies to the most significant failure of the diesel exhaust fluid temperature sensor.  When there is no failure FMI 31 is sent. In the case of multiple failures the most severe is communicated.";
CM_ SG_ 2566757374 AT1DeselExhaustFluidConductivity "A measure of the conductivity of the diesel exhaust fluid at the sensor.  The conductivity is an indication of the diesel exhaust fluid's chemical make up.";
CM_ SG_ 2566757374 AT1DselExhaustFluidConcentration "A measure of the concentration of urea in water.  Zero percent means that the tank contains no urea.  A 32.5% value indicates that the diesel exhaust fluid is of the proper concentration.  The 32.5% value indicates that the concentration is highest ...";
CM_ SG_ 2566757374 AT1DieselExhaustFluidTemp2 "Temperature of the diesel exhaust fluid at the device measuring diesel exhaust fluid quality";
CM_ BO_ 2364546302 "Contains Requested Generator Average Basic AC Quantities";
CM_ SG_ 2364546302 RqdGnrtrAvrgLneLineACRMSVoltage "The requested average AC RMS voltage to be delivered by the generator.";
CM_ BO_ 2431654654 "Used to control networked electronic throttle control actuator and/or fuel control actuator valves.  Otherwise, this PGN can be used to monitor commanded % positioning to electronic throttle control actuator and/or fuel control actuator valves.";
CM_ SG_ 2431654654 EngFuelActuator2CtrlCmd "The control command to fuel actuator 2, normalized to percent, where 0% represents fully closed and 100% represents fully open.  Typically, this fuel actuator is used to regulate low pressure natural gas flow rate, mixing into the air flow, which ...";
CM_ SG_ 2431654654 EngFuelActuator1CtrlCmd "The control command to fuel actuator 1, normalized to percent, where 0% represents fully closed and 100% represents fully open.  Typically, this fuel actuator is used to regulate low pressure natural gas flow rate, mixing into the air flow, which ...";
CM_ SG_ 2431654654 EngThrottleActuator2CtrlCmd "The control command to throttle actuator 2, normalized to percent, where 0% represents fully closed and 100% represents fully open.  Typically, this throttle actuator is used to regulate air or air / fuel mix to the engine. Using the standard ...";
CM_ SG_ 2431654654 EngThrottleActuator1CtrlCmd "The control command to throttle actuator 1, normalized to percent, where 0% represents fully closed and 100% represents fully open.  Typically, this throttle actuator is used to regulate air or air / fuel mix to the engine. Using the standard ...";
CM_ BO_ 2364545534 "Used to send the SPNs containing information relating to the level of knock for 8 cylinders. When knock is detected on any one cylinder, this PGN needs to be sent every crank revolution (engine speed dependant). If there is no knock detected on any ...";
CM_ SG_ 2364545534 EngCyl24KnockLevel "Used to indicate the level of knock for engine cylinder 24. The level of knock is reported using a relative scale where 0% is least level of knock, and increasing levels indicate more knock until 100% indicates the most severe level of knock allowed ...";
CM_ SG_ 2364545534 EngCyl23KnockLevel "Used to indicate the level of knock for engine cylinder 23. The level of knock is reported using a relative scale where 0% is least level of knock, and increasing levels indicate more knock until 100% indicates the most severe level of knock allowed ...";
CM_ SG_ 2364545534 EngCyl22KnockLevel "Used to indicate the level of knock for engine cylinder 22. The level of knock is reported using a relative scale where 0% is least level of knock, and increasing levels indicate more knock until 100% indicates the most severe level of knock allowed ...";
CM_ SG_ 2364545534 EngCyl21KnockLevel "Used to indicate the level of knock for engine cylinder 21. The level of knock is reported using a relative scale where 0% is least level of knock, and increasing levels indicate more knock until 100% indicates the most severe level of knock allowed ...";
CM_ SG_ 2364545534 EngCyl20KnockLevel "Used to indicate the level of knock for engine cylinder 20. The level of knock is reported using a relative scale where 0% is least level of knock, and increasing levels indicate more knock until 100% indicates the most severe level of knock allowed ...";
CM_ SG_ 2364545534 EngCyl19KnockLevel "Used to indicate the level of knock for engine cylinder 19. The level of knock is reported using a relative scale where 0% is least level of knock, and increasing levels indicate more knock until 100% indicates the most severe level of knock allowed ...";
CM_ SG_ 2364545534 EngCyl18KnockLevel "Used to indicate the level of knock for engine cylinder 18. The level of knock is reported using a relative scale where 0% is least level of knock, and increasing levels indicate more knock until 100% indicates the most severe level of knock allowed ...";
CM_ SG_ 2364545534 EngCyl17KnockLevel "Used to indicate the level of knock for engine cylinder 17. The level of knock is reported using a relative scale where 0% is least level of knock, and increasing levels indicate more knock until 100% indicates the most severe level of knock allowed ...";
CM_ BO_ 2364545278 "Used to send the SPNs containing information relating to the level of knock for 8 cylinders. When knock is detected on any one cylinder, this PGN needs to be sent every crank revolution (engine speed dependant). If there is no knock detected on any ...";
CM_ SG_ 2364545278 EngCyl16KnockLevel "Used to indicate the level of knock for engine cylinder 16. The level of knock is reported using a relative scale where 0% is least level of knock, and increasing levels indicate more knock until 100% indicates the most severe level of knock allowed ...";
CM_ SG_ 2364545278 EngCyl15KnockLevel "Used to indicate the level of knock for engine cylinder 15. The level of knock is reported using a relative scale where 0% is least level of knock, and increasing levels indicate more knock until 100% indicates the most severe level of knock allowed ...";
CM_ SG_ 2364545278 EngCyl14KnockLevel "Used to indicate the level of knock for engine cylinder 14. The level of knock is reported using a relative scale where 0% is least level of knock, and increasing levels indicate more knock until 100% indicates the most severe level of knock allowed ...";
CM_ SG_ 2364545278 EngCyl13KnockLevel "Used to indicate the level of knock for engine cylinder 13. The level of knock is reported using a relative scale where 0% is least level of knock, and increasing levels indicate more knock until 100% indicates the most severe level of knock allowed ...";
CM_ SG_ 2364545278 EngCyl12KnockLevel "Used to indicate the level of knock for engine cylinder 12. The level of knock is reported using a relative scale where 0% is least level of knock, and increasing levels indicate more knock until 100% indicates the most severe level of knock allowed ...";
CM_ SG_ 2364545278 EngCyl11KnockLevel "Used to indicate the level of knock for engine cylinder 11. The level of knock is reported using a relative scale where 0% is least level of knock, and increasing levels indicate more knock until 100% indicates the most severe level of knock allowed ...";
CM_ SG_ 2364545278 EngCyl10KnockLevel "Used to indicate the level of knock for engine cylinder 10. The level of knock is reported using a relative scale where 0% is least level of knock, and increasing levels indicate more knock until 100% indicates the most severe level of knock allowed ...";
CM_ SG_ 2364545278 EngCyl9KnockLevel "Used to indicate the level of knock for engine cylinder 9. The level of knock is reported using a relative scale where 0% is least level of knock, and increasing levels indicate more knock until 100% indicates the most severe level of knock allowed ...";
CM_ BO_ 2364545022 "Used to send the SPNs containing information relating to the level of knock for 8 cylinders. When knock is detected on any one cylinder, this PGN needs to be sent every crank revolution (engine speed dependant). If there is no knock detected on any ...";
CM_ SG_ 2364545022 EngCyl8KnockLevel "Used to indicate the level of knock for engine cylinder 8. The level of knock is reported using a relative scale where 0% is least level of knock, and increasing levels indicate more knock until 100% indicates the most severe level of knock allowed ...";
CM_ SG_ 2364545022 EngCyl7KnockLevel "Used to indicate the level of knock for engine cylinder 7. The level of knock is reported using a relative scale where 0% is least level of knock, and increasing levels indicate more knock until 100% indicates the most severe level of knock allowed ...";
CM_ SG_ 2364545022 EngCyl6KnockLevel "Used to indicate the level of knock for engine cylinder 6. The level of knock is reported using a relative scale where 0% is least level of knock, and increasing levels indicate more knock until 100% indicates the most severe level of knock allowed ...";
CM_ SG_ 2364545022 EngCyl5KnockLevel "Used to indicate the level of knock for engine cylinder 5. The level of knock is reported using a relative scale where 0% is least level of knock, and increasing levels indicate more knock until 100% indicates the most severe level of knock allowed ...";
CM_ SG_ 2364545022 EngCyl4KnockLevel "Used to indicate the level of knock for engine cylinder 4. The level of knock is reported using a relative scale where 0% is least level of knock, and increasing levels indicate more knock until 100% indicates the most severe level of knock allowed ...";
CM_ SG_ 2364545022 EngCyl3KnockLevel "Used to indicate the level of knock for engine cylinder 3. The level of knock is reported using a relative scale where 0% is least level of knock, and increasing levels indicate more knock until 100% indicates the most severe level of knock allowed ...";
CM_ SG_ 2364545022 EngCyl2KnockLevel "Used to indicate the level of knock for engine cylinder 2. The level of knock is reported using a relative scale where 0% is least level of knock, and increasing levels indicate more knock until 100% indicates the most severe level of knock allowed ...";
CM_ SG_ 2364545022 EngCyl1KnockLevel "Used to indicate the level of knock for engine cylinder 1. The level of knock is reported using a relative scale where 0% is least level of knock, and increasing levels indicate more knock until 100% indicates the most severe level of knock allowed ...";
CM_ BO_ 2364544766 "Used to send the SPNs containing information relating to the state of combustion for 24 cylinders. When there is no combustion detected on any one cylinder, this PGN needs to be sent every crank revolution (engine speed dependant). If combustion is ...";
CM_ SG_ 2364544766 EngCyl24CombustionStatus "This parameter is used to indicate state of combustion in engine cylinder #24

00        No combustion
01        Combustion exists
10        Error
11        Not available";
CM_ SG_ 2364544766 EngCyl23CombustionStatus "This parameter is used to indicate state of combustion in engine cylinder #23

00        No combustion
01        Combustion exists
10        Error
11        Not available";
CM_ SG_ 2364544766 EngCyl22CombustionStatus "This parameter is used to indicate state of combustion in engine cylinder #22

00        No combustion
01        Combustion exists
10        Error
11        Not available";
CM_ SG_ 2364544766 EngCyl21CombustionStatus "This parameter is used to indicate state of combustion in engine cylinder #21

00        No combustion
01        Combustion exists
10        Error
11        Not available";
CM_ SG_ 2364544766 EngCyl20CombustionStatus "This parameter is used to indicate state of combustion in engine cylinder #20

00        No combustion
01        Combustion exists
10        Error
11        Not available";
CM_ SG_ 2364544766 EngCyl19CombustionStatus "This parameter is used to indicate state of combustion in engine cylinder #19

00        No combustion
01        Combustion exists
10        Error
11        Not available";
CM_ SG_ 2364544766 EngCyl18CombustionStatus "This parameter is used to indicate state of combustion in engine cylinder #18

00        No combustion
01        Combustion exists
10        Error
11        Not available";
CM_ SG_ 2364544766 EngCyl17CombustionStatus "This parameter is used to indicate state of combustion in engine cylinder #17

00        No combustion
01        Combustion exists
10        Error
11        Not available";
CM_ SG_ 2364544766 EngCyl16CombustionStatus "This parameter is used to indicate state of combustion in engine cylinder #16

00        No combustion
01        Combustion exists
10        Error
11        Not available";
CM_ SG_ 2364544766 EngCyl15CombustionStatus "This parameter is used to indicate state of combustion in engine cylinder #15

00        No combustion
01        Combustion exists
10        Error
11        Not available";
CM_ SG_ 2364544766 EngCyl14CombustionStatus "This parameter is used to indicate state of combustion in engine cylinder #14
00        No combustion
01        Combustion exists
10        Error
11        Not available";
CM_ SG_ 2364544766 EngCyl13CombustionStatus "This parameter is used to indicate state of combustion in engine cylinder #13

00        No combustion
01        Combustion exists
10        Error
11        Not available";
CM_ SG_ 2364544766 EngCyl12CombustionStatus "This parameter is used to indicate state of combustion in engine cylinder #12

00        No combustion
01        Combustion exists
10        Error
11        Not available";
CM_ SG_ 2364544766 EngCyl11CombustionStatus "This parameter is used to indicate state of combustion in engine cylinder #11

00        No combustion
01        Combustion exists
10        Error
11        Not available";
CM_ SG_ 2364544766 EngCyl10CombustionStatus "This parameter is used to indicate state of combustion in engine cylinder #10

00        No combustion
01        Combustion exists
10        Error
11        Not available";
CM_ SG_ 2364544766 EngCyl9CombustionStatus "This parameter is used to indicate state of combustion in engine cylinder #9

00        No combustion
01        Combustion exists
10        Error
11        Not available";
CM_ SG_ 2364544766 EngCyl8CombustionStatus "This parameter is used to indicate state of combustion in engine cylinder #8

00        No combustion
01        Combustion exists
10        Error
11        Not available";
CM_ SG_ 2364544766 EngCyl7CombustionStatus "This parameter is used to indicate state of combustion in engine cylinder #7

00        No combustion
01        Combustion exists
10        Error
11        Not available";
CM_ SG_ 2364544766 EngCyl6CombustionStatus "This parameter is used to indicate state of combustion in engine cylinder #6

00        No combustion
01        Combustion exists
10        Error
11        Not available";
CM_ SG_ 2364544766 EngCyl5CombustionStatus "This parameter is used to indicate state of combustion in engine cylinder #5

00        No combustion
01        Combustion exists
10        Error
11        Not available";
CM_ SG_ 2364544766 EngCyl4CombustionStatus "This parameter is used to indicate state of combustion in engine cylinder #4

00        No combustion
01        Combustion exists
10        Error
11        Not available";
CM_ SG_ 2364544766 EngCyl3CombustionStatus "This parameter is used to indicate state of combustion in engine cylinder #3

00        No combustion
01        Combustion exists
10        Error
11        Not available";
CM_ SG_ 2364544766 EngCyl2CombustionStatus "This parameter is used to indicate state of combustion in engine cylinder #2

00        No combustion
01        Combustion exists
10        Error
11        Not available";
CM_ SG_ 2364544766 EngCyl1CombustionStatus "This parameter is used to indicate state of combustion in engine cylinder #1

00        No combustion
01        Combustion exists
10        Error
11        Not available";
CM_ BO_ 2364544510 "Contains requested reactive and power factor control values";
CM_ SG_ 2364544510 RqGenOverallPowerFactorLagging "The requested lead/lag status for the generator average AC power factor

00 - Leading
01 - Lagging
10 - Reserved
11 - Not available or Not installed";
CM_ SG_ 2364544510 RqGeneratorOverallPowerFactor "The requested average power factor of the generator.";
CM_ SG_ 2364544510 RqGeneratorTotalACReactivePower "The total reactive power requested to be delivered by the generator";
CM_ BO_ 2364544254 "A measurement of the machine's relative blade height and a rotational angle measurement of the machine blade yaw angle around the machine z-axis.  The vehicle dynamics measurements in this message shall be according to a Z-Down axis system as ...";
CM_ SG_ 2364544254 BladeRotationAngleFigureOfMerit "Figure of merit for blade rotation measurement.
Bits
00  Blade Rotation Angle fully functional.  Data is within sensor specification.
01  Blade Rotation Angle  degraded.  Data is suspect due to environmental conditions.
10  Blade Rotation Angle ...";
CM_ SG_ 2364544254 RelativeBladeHeightFigureOfMerit "Figure of merit for blade height measurement.
Bits
00  Relative Blade Height fully functional.  Data is within sensor specification.
01  Relative Blade Height degraded.  Data is suspect due to environmental conditions.
10  Relative Blade Height ...";
CM_ SG_ 2364544254 RltvBldHghtAndBldRttnAnglMsrmntL "The estimated measurement latency of the measurement.
NOTE: This is only the sensor latency and does not include any additional latencies that might exist because of the CAN Bus or overall system implementation.
For example, if the technique used ...";
CM_ SG_ 2364544254 BladeRotationAngle "The blade rotation angle measurement around the yaw (z-axis).  The Blade Rotation Angle is defined to be the angle from the null position on the machine.  The null position is orthogonal from the z-axis along the x-axis.  A positive blade angle ...";
CM_ SG_ 2364544254 RelativeBladeHeight "The measured vertical distance from a fixed location on the machine blade to a ground-based reference (i.e. relative height).  Examples of a ground based reference include a curb, a stringline or the ground itself.  The measurement may be positive ...";
CM_ BO_ 2349006590 "Message to transmit data of the towing vehicle to the towed vehicle. See ISO 11992-2.";
CM_ SG_ 2349006590 RetarderDemandValue "The demanded value of the retarder on the towed vehicle(s) as a percentage of the absolute peak torque of retarder.";
CM_ SG_ 2349006590 ParkBrakeDemandValue "The requested brake pressure value of the parking brake as a percentage of maximum.";
CM_ SG_ 2349006590 ServiceBrakeDemandValue "The requested brake pressure value of the service brake demanded by the driver.";
CM_ SG_ 2349006590 VehicleType "Information to identify a dolly axle within the road train.";
CM_ SG_ 2349006590 BrakeLightSwitch "Signal which indicates that the brake pedal is being pressed.";
CM_ SG_ 2349006590 ASREngineControlActive "Signal which indicates that ASR engine control is active/passive.";
CM_ SG_ 2349006590 ASRBreakControlActive "Signal which indicates that ASR brake control is active/passive.";
CM_ SG_ 2349006590 VehicleRetarderCtrlActive "This signal indicates the active/passive state in all cases when the installed retarder is applied by the driver’s demand or by other systems (brakes).";
CM_ SG_ 2349006590 VehicleABSActive "Signal indicating the ABS is active/passive.";
CM_ BO_ 2365508094 "Message to transmit data of the towing vehicle to the towed vehicle. See ISO 11992-2.";
CM_ SG_ 2365508094 RoadCurvature "Estimated value of the current road curvature for use by the adaptive cruise control system.  Positive values are used for left curves.  Curvature is the inverse of the radius and is zero for straight roads.";
CM_ SG_ 2365508094 PneumaticControlLine "Signal which indicates that the towing vehicle has a pneumatic control line for the towed vehicle service braking system";
CM_ SG_ 2365508094 ABSOffroadRequest "Request to activate the ABS off-road function. The switch signal is independent of an actual ABS control situation.";
CM_ SG_ 2365508094 TwoElCircuitsBrakeDemand "Signal which indicates that the service brake demand value sent by the towing vehicle can be generated by one or two independent electrical braking circuit(s).";
CM_ SG_ 2365508094 VehicleRetarderCtrlActive "This signal indicates the active/passive state in all cases when the installed retarder is applied by the driver’s demand or by other systems (brakes).";
CM_ BO_ 2349072126 "Message to transmit data of the towed vehicle to the towing vehicle. See ISO 11992-2.";
CM_ SG_ 2349072126 WheelSpeedDiffMainAxle "Difference between the wheel speed at the right side and and the left side of the main axle.";
CM_ SG_ 2349072126 ActualRetarderPercTorque "Actual torque of the retarder as negative percentage of maximum.";
CM_ SG_ 2349072126 Wheel_BasedVehicleSpeed "Actual speed of the vehicle (positive value for forward and backward speed) calculated as the average of the wheel speeds of one axle influenced by slip and filtered by a frequency range of 5 Hz to 20 Hz.";
CM_ SG_ 2349072126 SupplyLineBrakingRequest "Signal indicating the trailer is requesting to be braked by the commercial vehicle by means of bleeding the pneumatic supply line.";
CM_ SG_ 2349072126 VDCActive "Signal which indicates that Vehicle Dynamic Control (VDC) is active/passive.";
CM_ SG_ 2349072126 AutomTowedVehBreakActive "Signal indicating the automatic towed vehicle braking is active/passive.";
CM_ SG_ 2349072126 VehicleServiceBrakeActive "Signal indicating the service brake of the towed vehicle is active/passive, by observing the brake pressure.";
CM_ SG_ 2349072126 VehicleRetarderCtrlActive "This signal indicates the active/passive state in all cases when the installed retarder is applied by the driver’s demand or by other systems (brakes).";
CM_ SG_ 2349072126 VehicleABSActive "Signal indicating the ABS is active/passive.";
CM_ BO_ 2365506814 "Message to transmit data of the towed vehicle to the towing vehicle. See ISO 11992-2.";
CM_ SG_ 2365506814 ReferenceRetarderTorque "This parameter is the 100% reference value for all defined indicated retarder torque parameters.  It is only defined once and doesn't change if a different retarder torque map becomes valid.";
CM_ SG_ 2365506814 AxleLoadSum "Sum of the static vertical loads of the vehicle axles.";
CM_ SG_ 2365506814 SupplyLineBrakingRequest "Signal indicating the trailer is requesting to be braked by the commercial vehicle by means of bleeding the pneumatic supply line.";
CM_ SG_ 2365506814 LoadingRampApproachAssist "The parameter indicates whether the loading ramp approach assistance is activated.";
CM_ SG_ 2365506814 SpringBrakeEngaged "Signal indicating the vehicle spring brake is engaged.";
CM_ SG_ 2365506814 ElectrLoadPropFunc "Signal indicating the vehicle is equipped with an electrical load proportional function.";
CM_ SG_ 2365506814 SpringBrakeInstalled "Signal indicating the vehicle has one or more axle(s) fitted with spring brakes.";
CM_ SG_ 2365506814 VehicleType "Information to identify a dolly axle within the road train.";
CM_ SG_ 2365506814 ElecSupplyOfNonBrakingSys "Signal which indicates the status of the supply of non-braking systems.";
CM_ SG_ 2365506814 AmberWarningSignalReq "Request from the towed vehicle to the commercial vehicle to activate the amber warning signal on the commercial vehicle.";
CM_ SG_ 2365506814 RedWarningSignalRequest "Request from the towed vehicle to the commercial vehicle to activate the red warning signal on the commercial vehicle, which indicates certain specified failures within the braking equipment of the towed vehicles.";
CM_ SG_ 2365506814 VehicleElectrSupplySuff "Signal indicating the actual supply voltage is sufficient/insufficient for proper brake function (including over voltage).";
CM_ SG_ 2365506814 AutomTowedVehBreakActive "Signal indicating the automatic towed vehicle braking is active/passive.";
CM_ SG_ 2365506814 VehicleServiceBrakeActive "Signal indicating the service brake of the towed vehicle is active/passive, by observing the brake pressure.";
CM_ SG_ 2365506814 VehicleRetarderCtrlActive "This signal indicates the active/passive state in all cases when the installed retarder is applied by the driver’s demand or by other systems (brakes).";
CM_ SG_ 2365506814 VehicleABSActive "Signal indicating the ABS is active/passive.";
CM_ BO_ 2365507326 "Message to transmit data of the towed vehicle to the towing vehicle. See ISO 11992-2.";
CM_ SG_ 2365507326 PneumaticSupplyPressure "Actual supply pressure of the reservoir of the braking system.";
CM_ SG_ 2365507326 BrakeTemperature "Actual brake temperature.";
CM_ SG_ 2365507326 BrakeLining "Actual relative value of brake lining of a specific brake.";
CM_ SG_ 2365507326 TyrePressure "Actual tyre pressure without corrections.";
CM_ SG_ 2365507326 TyreWheelIdentTemp2 "Second part of identification number of the tyre or wheel (the number of axles).";
CM_ SG_ 2365507326 TyreWheelIdentTemp1 "First part of identification number of the tyre or wheel (position on each axle).";
CM_ SG_ 2365507326 TyreWheelIdentPressure2 "Second part of identification number of the tyre or wheel (the number of axles).";
CM_ SG_ 2365507326 TyreWheelIdentPressure1 "First part of identification number of the tyre or wheel (position on each axle).";
CM_ SG_ 2365507326 TyreWheelIdentLining2 "Second part of identification number of the tyre or wheel (the number of axles).";
CM_ SG_ 2365507326 TyreWheelIdentLining1 "First part of identification number of the tyre or wheel (position on each axle).";
CM_ SG_ 2365507326 VehiclePneumSupplySuff "Signal indicating the actual supply pressure of the reservoir of the braking system is insufficient or sufficient.";
CM_ SG_ 2365507326 BrakeTemperatureStatus "Signal which indicates that the brake temperature is higher than a specific level.";
CM_ SG_ 2365507326 BrakeLiningSufficient "Signal which indicates that the brake lining is sufficient/insufficient.";
CM_ SG_ 2365507326 TyrePressureSufficient "Signal which indicates that the tyre pressure is insufficient";
CM_ BO_ 2363686654 "Message to transmit data of the towing vehicle to the towed vehicle. See ISO 11992-3.";
CM_ SG_ 2363686654 ODDRequest "Command signal to switch on or off the obstacle detection device (ODD).";
CM_ SG_ 2363686654 AntiTheftDeviceReq "Command signal to activate the anti-theft device.";
CM_ SG_ 2363686654 VehicleType "Information to identify a dolly axle within the road train.";
CM_ BO_ 2365480446 "Message to transmit data of the towing vehicle to the towed vehicle. See ISO 11992-3.";
CM_ SG_ 2365480446 MaxVehicleSpeedLimit "Maximum vehicle velocity allowed.   See SPN 6808 for an alternate resolution.";
CM_ SG_ 2365480446 EngineSpeedUpperLimit "The engine speed which cannot be exceeded.";
CM_ SG_ 2365480446 EngineSpeedLowerLimit "The minimum engine speed which the engine is allowed to reach.";
CM_ BO_ 2365480958 "Message to transmit data of the towing vehicle to the towed vehicle. See ISO 11992-3.";
CM_ SG_ 2365480958 EngineTorqueMode "State signal which indicates which engine torque mode is currently generating, limiting, or controlling the torque";
CM_ SG_ 2365480958 PercentLoadAtCurrentSpeed "The ratio of actual engine percent torque to maximum indicated torque available at the current engine speed, clipped to zero torque during engine braking.";
CM_ SG_ 2365480958 EngineSpeed "Actual engine speed which is calculated over a minimum crankshaft angle of 720 degrees divided by
the number of cylinders.";
CM_ SG_ 2365480958 ActualEngine_PercTorque "The calculated output torque of the engine.";
CM_ SG_ 2365480958 DriversDemandEngine_PercTorque "The torque output of the engine requested by the driver.";
CM_ SG_ 2365480958 EngineRunning "Signal which indicates whether the engine is running.";
CM_ SG_ 2365480958 EngineControlAllowed "Switch signal which indicates that engine control is allowed.";
BA_DEF_ SG_  "SigType" ENUM  "Default","Range","RangeSigned","ASCII","Discrete","Control","ReferencePGN","DTC","StringDelimiter","StringLength","StringLengthControl","MessageCounter","MessageChecksum";
BA_DEF_ SG_  "GenSigStartValue" INT 0 10000;
BA_DEF_ SG_  "GenSigSendType" ENUM  "Cyclic","OnWrite","OnWriteWithRepetition","OnChange","OnChangeWithRepetition","IfActive","IfActiveWithRepetition","NoSigSendType";
BA_DEF_ SG_  "GenSigILSupport" ENUM  "No","Yes";
BA_DEF_ SG_  "GenSigEVName" STRING ;
BA_DEF_ SG_  "SPN" INT 0 524287;
BA_DEF_ BO_  "TpJ1939VarDlc" ENUM  "No","Yes";
BA_DEF_ BO_  "GenMsgStartDelayTime" INT 0 100000;
BA_DEF_ BO_  "GenMsgILSupport" ENUM  "No","Yes";
BA_DEF_ BO_  "GenMsgDelayTime" INT 0 1000;
BA_DEF_ BO_  "GenMsgRequestable" INT 0 1;
BA_DEF_ BO_  "GenMsgSendType" ENUM  "cyclic","NotUsed","NotUsed","NotUsed","NotUsed","NotUsed","NotUsed","IfActive","noMsgSendType";
BA_DEF_ BO_  "VFrameFormat" ENUM  "StandardCAN","ExtendedCAN","reserved","J1939PG";
BA_DEF_ BO_  "GenMsgCycleTime" INT 0 3600000;
BA_DEF_ SG_  "SystemSignalLongSymbol" STRING ;
BA_DEF_DEF_  "SigType" "Default";
BA_DEF_DEF_  "GenSigStartValue" 0;
BA_DEF_DEF_  "GenSigSendType" "NoSigSendType";
BA_DEF_DEF_  "GenSigILSupport" "Yes";
BA_DEF_DEF_  "GenSigEVName" "Env@Nodename_@Signame";
BA_DEF_DEF_  "SPN" 0;
BA_DEF_DEF_  "TpJ1939VarDlc" "No";
BA_DEF_DEF_  "GenMsgStartDelayTime" 0;
BA_DEF_DEF_  "GenMsgILSupport" "Yes";
BA_DEF_DEF_  "GenMsgDelayTime" 0;
BA_DEF_DEF_  "GenMsgRequestable" 1;
BA_DEF_DEF_  "GenMsgSendType" "noMsgSendType";
BA_DEF_DEF_  "VFrameFormat" "J1939PG";
BA_DEF_DEF_  "GenMsgCycleTime" 0;
BA_DEF_DEF_  "SystemSignalLongSymbol" "";
BA_ "GenMsgCycleTime" BO_ 2365473278 1000;
BA_ "GenMsgSendType" BO_ 2365473278 0;
BA_ "GenMsgDelayTime" BO_ 2365473278 100;
BA_ "GenMsgCycleTime" BO_ 2365485822 50;
BA_ "GenMsgSendType" BO_ 2365485822 0;
BA_ "GenMsgCycleTime" BO_ 2566768894 1000;
BA_ "GenMsgSendType" BO_ 2566768894 0;
BA_ "GenMsgCycleTime" BO_ 2566769406 1000;
BA_ "GenMsgSendType" BO_ 2566769406 0;
BA_ "TpJ1939VarDlc" BO_ 2566839550 1;
BA_ "GenMsgCycleTime" BO_ 2633934334 1000;
BA_ "GenMsgSendType" BO_ 2633934334 0;
BA_ "GenMsgCycleTime" BO_ 2566825726 5000;
BA_ "GenMsgSendType" BO_ 2566825726 0;
BA_ "GenMsgCycleTime" BO_ 2566770942 5000;
BA_ "GenMsgSendType" BO_ 2566770942 0;
BA_ "GenMsgCycleTime" BO_ 2566846206 5000;
BA_ "GenMsgSendType" BO_ 2566846206 0;
BA_ "GenMsgCycleTime" BO_ 2566811134 1000;
BA_ "GenMsgSendType" BO_ 2566811134 0;
BA_ "GenMsgCycleTime" BO_ 2298375934 20;
BA_ "GenMsgSendType" BO_ 2298375934 0;
BA_ "GenMsgCycleTime" BO_ 2565867774 50;
BA_ "GenMsgSendType" BO_ 2565867774 0;
BA_ "GenMsgCycleTime" BO_ 2365449982 100;
BA_ "GenMsgSendType" BO_ 2365449982 0;
BA_ "GenMsgCycleTime" BO_ 2566757630 1000;
BA_ "GenMsgSendType" BO_ 2566757630 0;
BA_ "GenMsgCycleTime" BO_ 2566757886 1000;
BA_ "GenMsgSendType" BO_ 2566757886 0;
BA_ "GenMsgCycleTime" BO_ 2566759678 100;
BA_ "GenMsgSendType" BO_ 2566759678 0;
BA_ "GenMsgCycleTime" BO_ 2432541438 500;
BA_ "GenMsgSendType" BO_ 2432541438 0;
BA_ "GenMsgCycleTime" BO_ 2566761214 500;
BA_ "GenMsgSendType" BO_ 2566761214 0;
BA_ "GenMsgCycleTime" BO_ 2432541694 100;
BA_ "GenMsgSendType" BO_ 2432541694 0;
BA_ "GenMsgCycleTime" BO_ 2566759934 100;
BA_ "GenMsgSendType" BO_ 2566759934 0;
BA_ "GenMsgCycleTime" BO_ 2566757374 1000;
BA_ "GenMsgSendType" BO_ 2566757374 0;
BA_ "GenMsgCycleTime" BO_ 2364546302 100;
BA_ "GenMsgSendType" BO_ 2364546302 0;
BA_ "GenMsgCycleTime" BO_ 2431654654 50;
BA_ "GenMsgSendType" BO_ 2431654654 0;
BA_ "GenMsgCycleTime" BO_ 2364545534 5000;
BA_ "GenMsgSendType" BO_ 2364545534 0;
BA_ "GenMsgCycleTime" BO_ 2364545278 5000;
BA_ "GenMsgSendType" BO_ 2364545278 0;
BA_ "GenMsgCycleTime" BO_ 2364545022 5000;
BA_ "GenMsgSendType" BO_ 2364545022 0;
BA_ "GenMsgCycleTime" BO_ 2364544766 5000;
BA_ "GenMsgSendType" BO_ 2364544766 0;
BA_ "GenMsgCycleTime" BO_ 2364544510 100;
BA_ "GenMsgSendType" BO_ 2364544510 0;
BA_ "GenMsgCycleTime" BO_ 2364544254 50;
BA_ "GenMsgSendType" BO_ 2364544254 0;
BA_ "GenMsgCycleTime" BO_ 2349006590 10;
BA_ "GenMsgSendType" BO_ 2349006590 0;
BA_ "GenMsgCycleTime" BO_ 2365508094 100;
BA_ "GenMsgSendType" BO_ 2365508094 0;
BA_ "GenMsgCycleTime" BO_ 2349072126 10;
BA_ "GenMsgSendType" BO_ 2349072126 0;
BA_ "GenMsgCycleTime" BO_ 2365506814 100;
BA_ "GenMsgSendType" BO_ 2365506814 0;
BA_ "GenMsgCycleTime" BO_ 2365507326 100;
BA_ "GenMsgSendType" BO_ 2365507326 0;
BA_ "GenMsgCycleTime" BO_ 2363686654 100;
BA_ "GenMsgSendType" BO_ 2363686654 0;
BA_ "GenMsgCycleTime" BO_ 2365480446 500;
BA_ "GenMsgSendType" BO_ 2365480446 0;
BA_ "GenMsgCycleTime" BO_ 2365480958 50;
BA_ "GenMsgSendType" BO_ 2365480958 0;
BA_ "SPN" SG_ 2566799614 ImplementRearWorkLight 2394;
BA_ "SigType" SG_ 2566799614 ImplementRearWorkLight 4;
BA_ "SPN" SG_ 2566799614 ImplementLeftFacingWorkLight 2400;
BA_ "SigType" SG_ 2566799614 ImplementLeftFacingWorkLight 4;
BA_ "SPN" SG_ 2566799614 ImplementRightForwardWorkLight 2402;
BA_ "SigType" SG_ 2566799614 ImplementRightForwardWorkLight 4;
BA_ "SPN" SG_ 2566799614 ImplementLeftForwardWorkLight 2598;
BA_ "SigType" SG_ 2566799614 ImplementLeftForwardWorkLight 4;
BA_ "SPN" SG_ 2566799614 ImplementRightFacingWorkLight 2407;
BA_ "SigType" SG_ 2566799614 ImplementRightFacingWorkLight 4;
BA_ "SPN" SG_ 2566799614 ImplementOEMOption1Light 2396;
BA_ "SigType" SG_ 2566799614 ImplementOEMOption1Light 4;
BA_ "SPN" SG_ 2566799614 ImplementOEMOption2Light 2398;
BA_ "SigType" SG_ 2566799614 ImplementOEMOption2Light 4;
BA_ "SPN" SG_ 2566799614 TrctorFrontHighMountedWorkLights 2356;
BA_ "SigType" SG_ 2566799614 TrctorFrontHighMountedWorkLights 4;
BA_ "SPN" SG_ 2566799614 TractorFrontLowMountedWorkLights 2354;
BA_ "SigType" SG_ 2566799614 TractorFrontLowMountedWorkLights 4;
BA_ "SPN" SG_ 2566799614 TractorSideHighMountedWorkLights 2366;
BA_ "SigType" SG_ 2566799614 TractorSideHighMountedWorkLights 4;
BA_ "SPN" SG_ 2566799614 TractorSideLowMountedWorkLights 2364;
BA_ "SigType" SG_ 2566799614 TractorSideLowMountedWorkLights 4;
BA_ "SPN" SG_ 2566799614 TractorRearHighMountedWorkLights 2362;
BA_ "SigType" SG_ 2566799614 TractorRearHighMountedWorkLights 4;
BA_ "SPN" SG_ 2566799614 TractorRearLowMountedWorkLights 2360;
BA_ "SigType" SG_ 2566799614 TractorRearLowMountedWorkLights 4;
BA_ "SPN" SG_ 2566799614 TrctorUndersideMountedWorkLights 2358;
BA_ "SigType" SG_ 2566799614 TrctorUndersideMountedWorkLights 4;
BA_ "SPN" SG_ 2566799614 RearFogLights 2390;
BA_ "SigType" SG_ 2566799614 RearFogLights 4;
BA_ "SPN" SG_ 2566799614 TractorMarkerLight 2378;
BA_ "SigType" SG_ 2566799614 TractorMarkerLight 4;
BA_ "SPN" SG_ 2566799614 ImplementMarkerLight 2380;
BA_ "SigType" SG_ 2566799614 ImplementMarkerLight 4;
BA_ "SPN" SG_ 2566799614 TractorClearanceLight 2382;
BA_ "SigType" SG_ 2566799614 TractorClearanceLight 4;
BA_ "SPN" SG_ 2566799614 ImplementClearanceLight 2384;
BA_ "SigType" SG_ 2566799614 ImplementClearanceLight 4;
BA_ "SPN" SG_ 2566799614 LeftStopLight 2372;
BA_ "SigType" SG_ 2566799614 LeftStopLight 4;
BA_ "SPN" SG_ 2566799614 RightStopLight 2374;
BA_ "SigType" SG_ 2566799614 RightStopLight 4;
BA_ "SPN" SG_ 2566799614 CenterStopLight 2376;
BA_ "SigType" SG_ 2566799614 CenterStopLight 4;
BA_ "SPN" SG_ 2566799614 BackUpLightAndAlarmHorn 2392;
BA_ "SigType" SG_ 2566799614 BackUpLightAndAlarmHorn 4;
BA_ "SPN" SG_ 2566799614 LeftTurnSignalLights 2368;
BA_ "SigType" SG_ 2566799614 LeftTurnSignalLights 4;
BA_ "SPN" SG_ 2566799614 RightTurnSignalLights 2370;
BA_ "SigType" SG_ 2566799614 RightTurnSignalLights 4;
BA_ "SPN" SG_ 2566799614 RotatingBeaconLight 2386;
BA_ "SigType" SG_ 2566799614 RotatingBeaconLight 4;
BA_ "SPN" SG_ 2566799614 TractorFrontFogLights 2388;
BA_ "SigType" SG_ 2566799614 TractorFrontFogLights 4;
BA_ "SPN" SG_ 2566799614 HighBeamHeadLightData 2348;
BA_ "SigType" SG_ 2566799614 HighBeamHeadLightData 4;
BA_ "SPN" SG_ 2566799614 LowBeamHeadLightData 2350;
BA_ "SigType" SG_ 2566799614 LowBeamHeadLightData 4;
BA_ "SPN" SG_ 2566799614 AltBeamHeadLightData 2352;
BA_ "SigType" SG_ 2566799614 AltBeamHeadLightData 4;
BA_ "SPN" SG_ 2566799614 RunningLight 2404;
BA_ "SigType" SG_ 2566799614 RunningLight 4;
BA_ "SPN" SG_ 2365473278 ImplementRearWorkLightCmd 2405;
BA_ "SigType" SG_ 2365473278 ImplementRearWorkLightCmd 5;
BA_ "SPN" SG_ 2365473278 ImplementLeftFacingWorkLightCmd 2399;
BA_ "SigType" SG_ 2365473278 ImplementLeftFacingWorkLightCmd 5;
BA_ "SPN" SG_ 2365473278 ImplmentRightForwardWorkLightCmd 2401;
BA_ "SigType" SG_ 2365473278 ImplmentRightForwardWorkLightCmd 5;
BA_ "SPN" SG_ 2365473278 LightingDataRqCmd 2393;
BA_ "SigType" SG_ 2365473278 LightingDataRqCmd 5;
BA_ "SPN" SG_ 2365473278 ImplementLeftForwardWorkLightCmd 2597;
BA_ "SigType" SG_ 2365473278 ImplementLeftForwardWorkLightCmd 5;
BA_ "SPN" SG_ 2365473278 ImplementRightFacingWorkLightCmd 2406;
BA_ "SigType" SG_ 2365473278 ImplementRightFacingWorkLightCmd 5;
BA_ "SPN" SG_ 2365473278 ImplementOEMOption1LightCmd 2395;
BA_ "SigType" SG_ 2365473278 ImplementOEMOption1LightCmd 5;
BA_ "SPN" SG_ 2365473278 ImplementOEMOption2LightCmd 2397;
BA_ "SigType" SG_ 2365473278 ImplementOEMOption2LightCmd 5;
BA_ "SPN" SG_ 2365473278 TrctrFrntHghMountedWorkLightsCmd 2355;
BA_ "SigType" SG_ 2365473278 TrctrFrntHghMountedWorkLightsCmd 5;
BA_ "SPN" SG_ 2365473278 TrctrFrntLowMountedWorkLightsCmd 2353;
BA_ "SigType" SG_ 2365473278 TrctrFrntLowMountedWorkLightsCmd 5;
BA_ "SPN" SG_ 2365473278 TrctrSdeHighMountedWorkLightsCmd 2365;
BA_ "SigType" SG_ 2365473278 TrctrSdeHighMountedWorkLightsCmd 5;
BA_ "SPN" SG_ 2365473278 TrctrSideLowMountedWorkLightsCmd 2363;
BA_ "SigType" SG_ 2365473278 TrctrSideLowMountedWorkLightsCmd 5;
BA_ "SPN" SG_ 2365473278 TrctrRarHighMountedWorkLightsCmd 2361;
BA_ "SigType" SG_ 2365473278 TrctrRarHighMountedWorkLightsCmd 5;
BA_ "SPN" SG_ 2365473278 TrctrRearLowMountedWorkLightsCmd 2359;
BA_ "SigType" SG_ 2365473278 TrctrRearLowMountedWorkLightsCmd 5;
BA_ "SPN" SG_ 2365473278 TrctrUndrsdeMountedWorkLightsCmd 2357;
BA_ "SigType" SG_ 2365473278 TrctrUndrsdeMountedWorkLightsCmd 5;
BA_ "SPN" SG_ 2365473278 RearFogLightCmd 2389;
BA_ "SigType" SG_ 2365473278 RearFogLightCmd 5;
BA_ "SPN" SG_ 2365473278 TractorMarkerLightCmd 2377;
BA_ "SigType" SG_ 2365473278 TractorMarkerLightCmd 5;
BA_ "SPN" SG_ 2365473278 ImplementMarkerLightCmd 2379;
BA_ "SigType" SG_ 2365473278 ImplementMarkerLightCmd 5;
BA_ "SPN" SG_ 2365473278 TractorClearanceLightCmd 2381;
BA_ "SigType" SG_ 2365473278 TractorClearanceLightCmd 5;
BA_ "SPN" SG_ 2365473278 ImplementClearanceLightCmd 2383;
BA_ "SigType" SG_ 2365473278 ImplementClearanceLightCmd 5;
BA_ "SPN" SG_ 2365473278 LeftStopLightCmd 2371;
BA_ "SigType" SG_ 2365473278 LeftStopLightCmd 5;
BA_ "SPN" SG_ 2365473278 RightStopLightCmd 2373;
BA_ "SigType" SG_ 2365473278 RightStopLightCmd 5;
BA_ "SPN" SG_ 2365473278 CenterStopLightCmd 2375;
BA_ "SigType" SG_ 2365473278 CenterStopLightCmd 5;
BA_ "SPN" SG_ 2365473278 BackUpLightAndAlarmHornCmd 2391;
BA_ "SigType" SG_ 2365473278 BackUpLightAndAlarmHornCmd 5;
BA_ "SPN" SG_ 2365473278 LeftTurnSignalLightsCmd 2367;
BA_ "SigType" SG_ 2365473278 LeftTurnSignalLightsCmd 5;
BA_ "SPN" SG_ 2365473278 RightTurnSignalLightsCmd 2369;
BA_ "SigType" SG_ 2365473278 RightTurnSignalLightsCmd 5;
BA_ "SPN" SG_ 2365473278 RotatingBeaconLightCmd 2385;
BA_ "SigType" SG_ 2365473278 RotatingBeaconLightCmd 5;
BA_ "SPN" SG_ 2365473278 TractorFrontFogLightsCmd 2387;
BA_ "SigType" SG_ 2365473278 TractorFrontFogLightsCmd 5;
BA_ "SPN" SG_ 2365473278 HighBeamHeadLightCmd 2347;
BA_ "SigType" SG_ 2365473278 HighBeamHeadLightCmd 5;
BA_ "SPN" SG_ 2365473278 LowBeamHeadLightCmd 2349;
BA_ "SigType" SG_ 2365473278 LowBeamHeadLightCmd 5;
BA_ "SPN" SG_ 2365473278 AltBeamHeadLightCmd 2351;
BA_ "SigType" SG_ 2365473278 AltBeamHeadLightCmd 5;
BA_ "SPN" SG_ 2365473278 RunningLightCmd 2403;
BA_ "SigType" SG_ 2365473278 RunningLightCmd 5;
BA_ "SPN" SG_ 2365485822 LandLevelingSystemEnableStatus 5409;
BA_ "SigType" SG_ 2365485822 LandLevelingSystemEnableStatus 5;
BA_ "SPN" SG_ 2365485822 BladeCtrlModeRight 5408;
BA_ "SPN" SG_ 2365485822 BladeCtrlModeLeft 5407;
BA_ "SPN" SG_ 2365485822 BladeCtrlMode 1578;
BA_ "SPN" SG_ 2365485822 BladeDurationAndDirection 1577;
BA_ "SigType" SG_ 2365485822 BladeDurationAndDirection 1;
BA_ "SPN" SG_ 2633926654 EngActualIgntTiming 1436;
BA_ "SigType" SG_ 2633926654 EngActualIgntTiming 1;
BA_ "SPN" SG_ 2633926654 EngDesiredIgntTiming3 1435;
BA_ "SigType" SG_ 2633926654 EngDesiredIgntTiming3 1;
BA_ "SPN" SG_ 2633926654 EngDesiredIgntTiming2 1434;
BA_ "SigType" SG_ 2633926654 EngDesiredIgntTiming2 1;
BA_ "SPN" SG_ 2633926654 EngDesiredIgntTiming1 1433;
BA_ "SigType" SG_ 2633926654 EngDesiredIgntTiming1 1;
BA_ "SPN" SG_ 2633926398 EngCyl20IgntTiming 1432;
BA_ "SigType" SG_ 2633926398 EngCyl20IgntTiming 1;
BA_ "SPN" SG_ 2633926398 EngCyl19IgntTiming 1431;
BA_ "SigType" SG_ 2633926398 EngCyl19IgntTiming 1;
BA_ "SPN" SG_ 2633926398 EngCyl18IgntTiming 1430;
BA_ "SigType" SG_ 2633926398 EngCyl18IgntTiming 1;
BA_ "SPN" SG_ 2633926398 EngCyl17IgntTiming 1429;
BA_ "SigType" SG_ 2633926398 EngCyl17IgntTiming 1;
BA_ "SPN" SG_ 2633926142 EngCyl16IgntTiming 1428;
BA_ "SigType" SG_ 2633926142 EngCyl16IgntTiming 1;
BA_ "SPN" SG_ 2633926142 EngCyl15IgntTiming 1427;
BA_ "SigType" SG_ 2633926142 EngCyl15IgntTiming 1;
BA_ "SPN" SG_ 2633926142 EngCyl14IgntTiming 1426;
BA_ "SigType" SG_ 2633926142 EngCyl14IgntTiming 1;
BA_ "SPN" SG_ 2633926142 EngCyl13IgntTiming 1425;
BA_ "SigType" SG_ 2633926142 EngCyl13IgntTiming 1;
BA_ "SPN" SG_ 2633925886 EngCyl12IgntTiming 1424;
BA_ "SigType" SG_ 2633925886 EngCyl12IgntTiming 1;
BA_ "SPN" SG_ 2633925886 EngCyl11IgntTiming 1423;
BA_ "SigType" SG_ 2633925886 EngCyl11IgntTiming 1;
BA_ "SPN" SG_ 2633925886 EngCyl10IgntTiming 1422;
BA_ "SigType" SG_ 2633925886 EngCyl10IgntTiming 1;
BA_ "SPN" SG_ 2633925886 EngCyl9IgntTiming 1421;
BA_ "SigType" SG_ 2633925886 EngCyl9IgntTiming 1;
BA_ "SPN" SG_ 2633925630 EngCyl8IgntTiming 1420;
BA_ "SigType" SG_ 2633925630 EngCyl8IgntTiming 1;
BA_ "SPN" SG_ 2633925630 EngCyl7IgntTiming 1419;
BA_ "SigType" SG_ 2633925630 EngCyl7IgntTiming 1;
BA_ "SPN" SG_ 2633925630 EngCyl6IgntTiming 1418;
BA_ "SigType" SG_ 2633925630 EngCyl6IgntTiming 1;
BA_ "SPN" SG_ 2633925630 EngCyl5IgntTiming 1417;
BA_ "SigType" SG_ 2633925630 EngCyl5IgntTiming 1;
BA_ "SPN" SG_ 2633925374 EngCyl4IgntTiming 1416;
BA_ "SigType" SG_ 2633925374 EngCyl4IgntTiming 1;
BA_ "SPN" SG_ 2633925374 EngCyl3IgntTiming 1415;
BA_ "SigType" SG_ 2633925374 EngCyl3IgntTiming 1;
BA_ "SPN" SG_ 2633925374 EngCyl2IgntTiming 1414;
BA_ "SigType" SG_ 2633925374 EngCyl2IgntTiming 1;
BA_ "SPN" SG_ 2633925374 EngCyl1IgntTiming 1413;
BA_ "SigType" SG_ 2633925374 EngCyl1IgntTiming 1;
BA_ "SPN" SG_ 2633927422 EngCyl20IgntTransSecondOutput 1412;
BA_ "SigType" SG_ 2633927422 EngCyl20IgntTransSecondOutput 1;
BA_ "SPN" SG_ 2633927422 EngCyl19IgntTransSecondOutput 1411;
BA_ "SigType" SG_ 2633927422 EngCyl19IgntTransSecondOutput 1;
BA_ "SPN" SG_ 2633927422 EngCyl18IgntTransSecondOutput 1410;
BA_ "SigType" SG_ 2633927422 EngCyl18IgntTransSecondOutput 1;
BA_ "SPN" SG_ 2633927422 EngCyl17IgntTransSecondOutput 1409;
BA_ "SigType" SG_ 2633927422 EngCyl17IgntTransSecondOutput 1;
BA_ "SPN" SG_ 2633927166 EngCyl16IgntTransSecondOutput 1408;
BA_ "SigType" SG_ 2633927166 EngCyl16IgntTransSecondOutput 1;
BA_ "SPN" SG_ 2633927166 EngCyl15IgntTransSecondOutput 1407;
BA_ "SigType" SG_ 2633927166 EngCyl15IgntTransSecondOutput 1;
BA_ "SPN" SG_ 2633927166 EngCyl14IgntTransSecondOutput 1406;
BA_ "SigType" SG_ 2633927166 EngCyl14IgntTransSecondOutput 1;
BA_ "SPN" SG_ 2633927166 EngCyl13IgntTransSecondOutput 1405;
BA_ "SigType" SG_ 2633927166 EngCyl13IgntTransSecondOutput 1;
BA_ "SPN" SG_ 2633927166 EngCyl12IgntTransSecondOutput 1404;
BA_ "SigType" SG_ 2633927166 EngCyl12IgntTransSecondOutput 1;
BA_ "SPN" SG_ 2633927166 EngCyl11IgntTransSecondOutput 1403;
BA_ "SigType" SG_ 2633927166 EngCyl11IgntTransSecondOutput 1;
BA_ "SPN" SG_ 2633927166 EngCyl10IgntTransSecondOutput 1402;
BA_ "SigType" SG_ 2633927166 EngCyl10IgntTransSecondOutput 1;
BA_ "SPN" SG_ 2633927166 EngCyl9IgntTransSecondOutput 1401;
BA_ "SigType" SG_ 2633927166 EngCyl9IgntTransSecondOutput 1;
BA_ "SPN" SG_ 2633926910 EngCyl8IgntTransSecondOutput 1400;
BA_ "SigType" SG_ 2633926910 EngCyl8IgntTransSecondOutput 1;
BA_ "SPN" SG_ 2633926910 EngCyl7IgntTransSecondOutput 1399;
BA_ "SigType" SG_ 2633926910 EngCyl7IgntTransSecondOutput 1;
BA_ "SPN" SG_ 2633926910 EngCyl6IgntTransSecondOutput 1398;
BA_ "SigType" SG_ 2633926910 EngCyl6IgntTransSecondOutput 1;
BA_ "SPN" SG_ 2633926910 EngCyl5IgntTransSecondOutput 1397;
BA_ "SigType" SG_ 2633926910 EngCyl5IgntTransSecondOutput 1;
BA_ "SPN" SG_ 2633926910 EngCyl4IgntTransSecondOutput 1396;
BA_ "SigType" SG_ 2633926910 EngCyl4IgntTransSecondOutput 1;
BA_ "SPN" SG_ 2633926910 EngCyl3IgntTransSecondOutput 1395;
BA_ "SigType" SG_ 2633926910 EngCyl3IgntTransSecondOutput 1;
BA_ "SPN" SG_ 2633926910 EngCyl2IgntTransSecondOutput 1394;
BA_ "SigType" SG_ 2633926910 EngCyl2IgntTransSecondOutput 1;
BA_ "SPN" SG_ 2633926910 EngCyl1IgntTransSecondOutput 1393;
BA_ "SigType" SG_ 2633926910 EngCyl1IgntTransSecondOutput 1;
BA_ "SPN" SG_ 2566768894 EngOprtrPrmryIntrmdtSpdSlctState 2892;
BA_ "SPN" SG_ 2566769406 EngOprtrPrmryIntrmdteSpeedSelect 2880;
BA_ "SPN" SG_ 2566839550 EngTotalIdleHours 235;
BA_ "SigType" SG_ 2566839550 EngTotalIdleHours 1;
BA_ "SPN" SG_ 2566839550 EngTotalIdleFuelUsed 236;
BA_ "SigType" SG_ 2566839550 EngTotalIdleFuelUsed 1;
BA_ "SPN" SG_ 2633934334 EngIntakeManifold6Temp 1803;
BA_ "SigType" SG_ 2633934334 EngIntakeManifold6Temp 1;
BA_ "SPN" SG_ 2633934334 EngIntakeManifold5Temp 1802;
BA_ "SigType" SG_ 2633934334 EngIntakeManifold5Temp 1;
BA_ "SPN" SG_ 2633934334 EngIntakeManifold4Temp 1133;
BA_ "SigType" SG_ 2633934334 EngIntakeManifold4Temp 1;
BA_ "SPN" SG_ 2633934334 EngIntakeManifold3Temp 1132;
BA_ "SigType" SG_ 2633934334 EngIntakeManifold3Temp 1;
BA_ "SPN" SG_ 2633934334 EngIntakeManifold2Temp 1131;
BA_ "SigType" SG_ 2633934334 EngIntakeManifold2Temp 1;
BA_ "SPN" SG_ 2566825726 EngTurbo4BoostPress 1130;
BA_ "SigType" SG_ 2566825726 EngTurbo4BoostPress 1;
BA_ "SPN" SG_ 2566825726 EngTurbo3BoostPress 1129;
BA_ "SigType" SG_ 2566825726 EngTurbo3BoostPress 1;
BA_ "SPN" SG_ 2566825726 EngTurbo2BoostPress 1128;
BA_ "SigType" SG_ 2566825726 EngTurbo2BoostPress 1;
BA_ "SPN" SG_ 2566825726 EngTurbo1BoostPress 1127;
BA_ "SigType" SG_ 2566825726 EngTurbo1BoostPress 1;
BA_ "SPN" SG_ 2566770942 EngIntakeManifold2AbsPress 5422;
BA_ "SigType" SG_ 2566770942 EngIntakeManifold2AbsPress 1;
BA_ "SPN" SG_ 2566770942 EngIntakeManifold1AbsPress4817 4817;
BA_ "SigType" SG_ 2566770942 EngIntakeManifold1AbsPress4817 1;
BA_ "SPN" SG_ 2566770942 EngIntakeManifold1AbsPress 3563;
BA_ "SigType" SG_ 2566770942 EngIntakeManifold1AbsPress 1;
BA_ "SPN" SG_ 2566770942 EngIntakeManifold2Press 3562;
BA_ "SigType" SG_ 2566770942 EngIntakeManifold2Press 1;
BA_ "SPN" SG_ 2566770942 EngAirFilter4DiffPress 2811;
BA_ "SigType" SG_ 2566770942 EngAirFilter4DiffPress 1;
BA_ "SPN" SG_ 2566770942 EngAirFilter3DiffPress 2810;
BA_ "SigType" SG_ 2566770942 EngAirFilter3DiffPress 1;
BA_ "SPN" SG_ 2566770942 EngAirFilter2DiffPress 2809;
BA_ "SigType" SG_ 2566770942 EngAirFilter2DiffPress 1;
BA_ "SPN" SG_ 2566846206 EngCoolantFilterDiffPress 112;
BA_ "SigType" SG_ 2566846206 EngCoolantFilterDiffPress 1;
BA_ "SPN" SG_ 2566846206 EngExhaustGasTemp 173;
BA_ "SigType" SG_ 2566846206 EngExhaustGasTemp 1;
BA_ "SPN" SG_ 2566846206 EngAirFilter1DiffPress 107;
BA_ "SigType" SG_ 2566846206 EngAirFilter1DiffPress 1;
BA_ "SPN" SG_ 2566846206 EngAirIntakePress 106;
BA_ "SigType" SG_ 2566846206 EngAirIntakePress 1;
BA_ "SPN" SG_ 2566846206 EngIntakeManifold1Temp 105;
BA_ "SigType" SG_ 2566846206 EngIntakeManifold1Temp 1;
BA_ "SPN" SG_ 2566846206 EngIntakeManifold1Press 102;
BA_ "SigType" SG_ 2566846206 EngIntakeManifold1Press 1;
BA_ "SPN" SG_ 2566846206 AT1DslPrtculateFilterIntakePress 81;
BA_ "SigType" SG_ 2566846206 AT1DslPrtculateFilterIntakePress 1;
BA_ "SPN" SG_ 2566811134 ADRCompliantHeaterInstallation 6821;
BA_ "SigType" SG_ 2566811134 ADRCompliantHeaterInstallation 5;
BA_ "SPN" SG_ 2566811134 CabHeatingZone 1680;
BA_ "SigType" SG_ 2566811134 CabHeatingZone 5;
BA_ "SPN" SG_ 2566811134 EngHeatingZone 1679;
BA_ "SigType" SG_ 2566811134 EngHeatingZone 5;
BA_ "SPN" SG_ 2566811134 CabVentilation 1678;
BA_ "SigType" SG_ 2566811134 CabVentilation 5;
BA_ "SPN" SG_ 2566811134 AuxHeaterWaterPumpStatus 1676;
BA_ "SigType" SG_ 2566811134 AuxHeaterWaterPumpStatus 5;
BA_ "SPN" SG_ 2566811134 AuxHeaterMode 1677;
BA_ "SPN" SG_ 2566811134 AuxHeaterOutputPowerPercent 1689;
BA_ "SigType" SG_ 2566811134 AuxHeaterOutputPowerPercent 1;
BA_ "SPN" SG_ 2566811134 AuxHeaterInputAirTemp 1688;
BA_ "SigType" SG_ 2566811134 AuxHeaterInputAirTemp 1;
BA_ "SPN" SG_ 2566811134 AuxHeaterOutputCoolantTemp 1687;
BA_ "SigType" SG_ 2566811134 AuxHeaterOutputCoolantTemp 1;
BA_ "SPN" SG_ 2298375934 RearAxleRightWheelSpeed 1595;
BA_ "SigType" SG_ 2298375934 RearAxleRightWheelSpeed 1;
BA_ "SPN" SG_ 2298375934 RearAxleLeftWheelSpeed 1594;
BA_ "SigType" SG_ 2298375934 RearAxleLeftWheelSpeed 1;
BA_ "SPN" SG_ 2298375934 FrontAxleRightWheelSpeed 1593;
BA_ "SigType" SG_ 2298375934 FrontAxleRightWheelSpeed 1;
BA_ "SPN" SG_ 2298375934 FrontAxleLeftWheelSpeed 1592;
BA_ "SigType" SG_ 2298375934 FrontAxleLeftWheelSpeed 1;
BA_ "SPN" SG_ 2565867774 FireApparatusPumpEngagement 2599;
BA_ "SigType" SG_ 2565867774 FireApparatusPumpEngagement 4;
BA_ "SPN" SG_ 2565867774 HydPressGovernorPresetSwitch 6706;
BA_ "SigType" SG_ 2565867774 HydPressGovernorPresetSwitch 4;
BA_ "SPN" SG_ 2565867774 HydPressGovernorIncreaseSwitch 6703;
BA_ "SigType" SG_ 2565867774 HydPressGovernorIncreaseSwitch 4;
BA_ "SPN" SG_ 2565867774 HydPressGovernorDecreaseSwitch 6704;
BA_ "SigType" SG_ 2565867774 HydPressGovernorDecreaseSwitch 4;
BA_ "SPN" SG_ 2565867774 HydPressGovernorIdleSwitch 6705;
BA_ "SigType" SG_ 2565867774 HydPressGovernorIdleSwitch 4;
BA_ "SPN" SG_ 2565867774 HydDischargePressSetPoint 6708;
BA_ "SigType" SG_ 2565867774 HydDischargePressSetPoint 1;
BA_ "SPN" SG_ 2565867774 HydIntakePress 6707;
BA_ "SigType" SG_ 2565867774 HydIntakePress 1;
BA_ "SPN" SG_ 2565867774 FireApparatusOkayToPumpInterlock 6702;
BA_ "SigType" SG_ 2565867774 FireApparatusOkayToPumpInterlock 4;
BA_ "SPN" SG_ 2565867774 EngHydPressGovernorSwitch 1764;
BA_ "SigType" SG_ 2565867774 EngHydPressGovernorSwitch 4;
BA_ "SPN" SG_ 2565867774 EngHydPressGovernorModeIndicator 1763;
BA_ "SigType" SG_ 2565867774 EngHydPressGovernorModeIndicator 5;
BA_ "SPN" SG_ 2565867774 HydPress 1762;
BA_ "SigType" SG_ 2565867774 HydPress 1;
BA_ "SPN" SG_ 2566841854 EngTotalRevolutions 249;
BA_ "SigType" SG_ 2566841854 EngTotalRevolutions 1;
BA_ "SPN" SG_ 2566841854 EngTotalHoursOfOperation 247;
BA_ "SigType" SG_ 2566841854 EngTotalHoursOfOperation 1;
BA_ "SPN" SG_ 2365449982 HydBrakeFluidLevelSwitch 2931;
BA_ "SigType" SG_ 2365449982 HydBrakeFluidLevelSwitch 4;
BA_ "SPN" SG_ 2365449982 HydBrakeSystemAudibleWarningCmd 2930;
BA_ "SigType" SG_ 2365449982 HydBrakeSystemAudibleWarningCmd 5;
BA_ "SPN" SG_ 2365449982 HydBrakePressSupplyStateCircuit2 2583;
BA_ "SigType" SG_ 2365449982 HydBrakePressSupplyStateCircuit2 4;
BA_ "SPN" SG_ 2365449982 HydBrakePressSupplyStateCircuit1 2582;
BA_ "SigType" SG_ 2365449982 HydBrakePressSupplyStateCircuit1 4;
BA_ "SPN" SG_ 2365449982 HydBrkePressWarningStateCircuit2 2585;
BA_ "SigType" SG_ 2365449982 HydBrkePressWarningStateCircuit2 4;
BA_ "SPN" SG_ 2365449982 HydBrkePressWarningStateCircuit1 2584;
BA_ "SigType" SG_ 2365449982 HydBrkePressWarningStateCircuit1 4;
BA_ "SPN" SG_ 2365449982 HydBrakePressCircuit2 2581;
BA_ "SigType" SG_ 2365449982 HydBrakePressCircuit2 1;
BA_ "SPN" SG_ 2365449982 HydBrakePressCircuit1 2580;
BA_ "SigType" SG_ 2365449982 HydBrakePressCircuit1 1;
BA_ "SPN" SG_ 2633939198 TripDriveFuelEconomy 1012;
BA_ "SigType" SG_ 2633939198 TripDriveFuelEconomy 1;
BA_ "SPN" SG_ 2633939198 TripCruiseFuelUsed 1011;
BA_ "SigType" SG_ 2633939198 TripCruiseFuelUsed 1;
BA_ "SPN" SG_ 2633939198 TripVehicleIdleFuelUsed 1010;
BA_ "SigType" SG_ 2633939198 TripVehicleIdleFuelUsed 1;
BA_ "SPN" SG_ 2633939198 TripPTOGovernorNonmovingFuelUsed 1009;
BA_ "SigType" SG_ 2633939198 TripPTOGovernorNonmovingFuelUsed 1;
BA_ "SPN" SG_ 2633939198 TripPTOGovernorMovingFuelUsed 1008;
BA_ "SigType" SG_ 2633939198 TripPTOGovernorMovingFuelUsed 1;
BA_ "SPN" SG_ 2633939198 TripDriveFuelUsed 1007;
BA_ "SigType" SG_ 2633939198 TripDriveFuelUsed 1;
BA_ "SPN" SG_ 2633927678 EngFuelValve1OutletAbsPress 2980;
BA_ "SigType" SG_ 2633927678 EngFuelValve1OutletAbsPress 1;
BA_ "SPN" SG_ 2633927678 EngAirToFuelDiffPress 1392;
BA_ "SigType" SG_ 2633927678 EngAirToFuelDiffPress 1;
BA_ "SPN" SG_ 2633927678 EngFuelValveDiffPress 1391;
BA_ "SigType" SG_ 2633927678 EngFuelValveDiffPress 1;
BA_ "SPN" SG_ 2633927678 EngFuelValve1IntakeAbsPress 1390;
BA_ "SigType" SG_ 2633927678 EngFuelValve1IntakeAbsPress 1;
BA_ "SPN" SG_ 2633925118 EngRequestedFuelValve2Pos 1766;
BA_ "SigType" SG_ 2633925118 EngRequestedFuelValve2Pos 1;
BA_ "SPN" SG_ 2633925118 EngRequestedFuelValve1Pos 1765;
BA_ "SigType" SG_ 2633925118 EngRequestedFuelValve1Pos 1;
BA_ "SPN" SG_ 2633925118 EngFuelValve2Pos 1443;
BA_ "SigType" SG_ 2633925118 EngFuelValve2Pos 1;
BA_ "SPN" SG_ 2633925118 EngFuelValve1Pos 1442;
BA_ "SigType" SG_ 2633925118 EngFuelValve1Pos 1;
BA_ "SPN" SG_ 2633925118 EngFuelFlowRate2 1441;
BA_ "SigType" SG_ 2633925118 EngFuelFlowRate2 1;
BA_ "SPN" SG_ 2633925118 EngFuelFlowRate1 1440;
BA_ "SigType" SG_ 2633925118 EngFuelFlowRate1 1;
BA_ "SPN" SG_ 2633937662 EngFuelSpecificGravity 1389;
BA_ "SigType" SG_ 2633937662 EngFuelSpecificGravity 1;
BA_ "SPN" SG_ 2633937662 TripAverageFuelRate 1031;
BA_ "SigType" SG_ 2633937662 TripAverageFuelRate 1;
BA_ "SPN" SG_ 2633937662 TotalEngPTOGovernorFuelUsed 1030;
BA_ "SigType" SG_ 2633937662 TotalEngPTOGovernorFuelUsed 1;
BA_ "SPN" SG_ 2566804990 FuelEnergyContent 4245;
BA_ "SigType" SG_ 2566804990 FuelEnergyContent 1;
BA_ "SPN" SG_ 2566804990 ReferenceEngGasMassFlowRate 5684;
BA_ "SigType" SG_ 2566804990 ReferenceEngGasMassFlowRate 1;
BA_ "SPN" SG_ 2566804990 SpecificHeatRatio 1767;
BA_ "SigType" SG_ 2566804990 SpecificHeatRatio 1;
BA_ "SPN" SG_ 2633936894 TotalFuelUsed 1040;
BA_ "SigType" SG_ 2633936894 TotalFuelUsed 1;
BA_ "SPN" SG_ 2633936894 TripFuel 1039;
BA_ "SigType" SG_ 2633936894 TripFuel 1;
BA_ "SPN" SG_ 2566757630 SensorSupplyVoltage8 5126;
BA_ "SigType" SG_ 2566757630 SensorSupplyVoltage8 1;
BA_ "SPN" SG_ 2566757630 SensorSupplyVoltage7 5125;
BA_ "SigType" SG_ 2566757630 SensorSupplyVoltage7 1;
BA_ "SPN" SG_ 2566757630 SensorSupplyVoltage6 3514;
BA_ "SigType" SG_ 2566757630 SensorSupplyVoltage6 1;
BA_ "SPN" SG_ 2566757630 SensorSupplyVoltage5 3513;
BA_ "SigType" SG_ 2566757630 SensorSupplyVoltage5 1;
BA_ "SPN" SG_ 2566757886 SensorSupplyVoltage4 3512;
BA_ "SigType" SG_ 2566757886 SensorSupplyVoltage4 1;
BA_ "SPN" SG_ 2566757886 SensorSupplyVoltage3 3511;
BA_ "SigType" SG_ 2566757886 SensorSupplyVoltage3 1;
BA_ "SPN" SG_ 2566757886 SensorSupplyVoltage2 3510;
BA_ "SigType" SG_ 2566757886 SensorSupplyVoltage2 1;
BA_ "SPN" SG_ 2566757886 SensorSupplyVoltage1 3509;
BA_ "SigType" SG_ 2566757886 SensorSupplyVoltage1 1;
BA_ "SPN" SG_ 2566759678 AtLeastOnePTOEngaged 3948;
BA_ "SigType" SG_ 2566759678 AtLeastOnePTOEngaged 5;
BA_ "SPN" SG_ 2566759678 EnggmntSttsPTOEngAccessoryDrive2 3947;
BA_ "SigType" SG_ 2566759678 EnggmntSttsPTOEngAccessoryDrive2 5;
BA_ "SPN" SG_ 2566759678 EnggmntSttsPTOEngAccessoryDrive1 3944;
BA_ "SigType" SG_ 2566759678 EnggmntSttsPTOEngAccessoryDrive1 5;
BA_ "SPN" SG_ 2566759678 EngagementStatusPTOEngFlywheel 3941;
BA_ "SigType" SG_ 2566759678 EngagementStatusPTOEngFlywheel 5;
BA_ "SPN" SG_ 2566759678 EnggmntStatusTransInputShaftPTO1 3460;
BA_ "SigType" SG_ 2566759678 EnggmntStatusTransInputShaftPTO1 5;
BA_ "SPN" SG_ 2566759678 EnggmntStatusTransInputShaftPTO2 3461;
BA_ "SigType" SG_ 2566759678 EnggmntStatusTransInputShaftPTO2 5;
BA_ "SPN" SG_ 2566759678 EnggmntStatusTransOutputShaftPTO 3462;
BA_ "SigType" SG_ 2566759678 EnggmntStatusTransOutputShaftPTO 5;
BA_ "SPN" SG_ 2566759678 EnggmntSttsTrnsfrCsOtputShaftPTO 3463;
BA_ "SigType" SG_ 2566759678 EnggmntSttsTrnsfrCsOtputShaftPTO 5;
BA_ "SPN" SG_ 2566759678 EnggmntCnsntPTOEngAccssoryDrive2 3946;
BA_ "SigType" SG_ 2566759678 EnggmntCnsntPTOEngAccssoryDrive2 5;
BA_ "SPN" SG_ 2566759678 EnggmntCnsntPTOEngAccssoryDrive1 3943;
BA_ "SigType" SG_ 2566759678 EnggmntCnsntPTOEngAccssoryDrive1 5;
BA_ "SPN" SG_ 2566759678 EngagementConsentPTOEngFlywheel 3940;
BA_ "SigType" SG_ 2566759678 EngagementConsentPTOEngFlywheel 5;
BA_ "SPN" SG_ 2566759678 EnggmntCnsentTransInputShaftPTO1 3456;
BA_ "SigType" SG_ 2566759678 EnggmntCnsentTransInputShaftPTO1 5;
BA_ "SPN" SG_ 2566759678 EnggmntCnsentTransInputShaftPTO2 3457;
BA_ "SigType" SG_ 2566759678 EnggmntCnsentTransInputShaftPTO2 5;
BA_ "SPN" SG_ 2566759678 EnggmntCnsentTransOutputShaftPTO 3458;
BA_ "SigType" SG_ 2566759678 EnggmntCnsentTransOutputShaftPTO 5;
BA_ "SPN" SG_ 2566759678 EnggmntCnsntTrnsfrCsOtptShaftPTO 3459;
BA_ "SigType" SG_ 2566759678 EnggmntCnsntTrnsfrCsOtptShaftPTO 5;
BA_ "SPN" SG_ 2566759678 EnbleSwitchPTOEngAccessoryDrive2 3945;
BA_ "SigType" SG_ 2566759678 EnbleSwitchPTOEngAccessoryDrive2 5;
BA_ "SPN" SG_ 2566759678 EnbleSwitchPTOEngAccessoryDrive1 3942;
BA_ "SigType" SG_ 2566759678 EnbleSwitchPTOEngAccessoryDrive1 5;
BA_ "SPN" SG_ 2566759678 EnableSwitchPTOEngFlywheel 3939;
BA_ "SigType" SG_ 2566759678 EnableSwitchPTOEngFlywheel 5;
BA_ "SPN" SG_ 2566759678 EnableSwitchTransInputShaftPTO1 3452;
BA_ "SigType" SG_ 2566759678 EnableSwitchTransInputShaftPTO1 5;
BA_ "SPN" SG_ 2566759678 EnableSwitchTransInputShaftPTO2 3453;
BA_ "SigType" SG_ 2566759678 EnableSwitchTransInputShaftPTO2 5;
BA_ "SPN" SG_ 2566759678 EnableSwitchTransOutputShaftPTO 3454;
BA_ "SigType" SG_ 2566759678 EnableSwitchTransOutputShaftPTO 5;
BA_ "SPN" SG_ 2566759678 EnblSwtchTrnsfrCseOutputShaftPTO 3455;
BA_ "SigType" SG_ 2566759678 EnblSwtchTrnsfrCseOutputShaftPTO 5;
BA_ "SPN" SG_ 2432541438 EngFuelValve2OutletAbsPress 3469;
BA_ "SigType" SG_ 2432541438 EngFuelValve2OutletAbsPress 1;
BA_ "SPN" SG_ 2432541438 EngFuelTemp2 3468;
BA_ "SigType" SG_ 2432541438 EngFuelTemp2 1;
BA_ "SPN" SG_ 2432541438 EngGas2MassFlowRate 3467;
BA_ "SigType" SG_ 2432541438 EngGas2MassFlowRate 1;
BA_ "SPN" SG_ 2432541438 EngFuelValve2IntakeAbsPress 3466;
BA_ "SigType" SG_ 2432541438 EngFuelValve2IntakeAbsPress 1;
BA_ "SPN" SG_ 2566761214 EngChargeAirCoolerOutletPress 2631;
BA_ "SigType" SG_ 2566761214 EngChargeAirCoolerOutletPress 1;
BA_ "SPN" SG_ 2566761214 EngAftercoolerCoolantLevel 3676;
BA_ "SigType" SG_ 2566761214 EngAftercoolerCoolantLevel 1;
BA_ "SPN" SG_ 2566761214 EngIntercoolerCoolantLevel 3668;
BA_ "SigType" SG_ 2566761214 EngIntercoolerCoolantLevel 1;
BA_ "SPN" SG_ 2566761214 EngCentrifugalOilFilterSpeed 3343;
BA_ "SigType" SG_ 2566761214 EngCentrifugalOilFilterSpeed 1;
BA_ "SPN" SG_ 2566761214 EngCoolantPumpDiffPress 3342;
BA_ "SigType" SG_ 2566761214 EngCoolantPumpDiffPress 1;
BA_ "SPN" SG_ 2566761214 EngChargeAirCooler2IntakePress 3341;
BA_ "SigType" SG_ 2566761214 EngChargeAirCooler2IntakePress 1;
BA_ "SPN" SG_ 2566761214 EngChargeAirCooler1IntakePress 3340;
BA_ "SigType" SG_ 2566761214 EngChargeAirCooler1IntakePress 1;
BA_ "SPN" SG_ 2432541694 EngVriableGeometryTurboActuator1 641;
BA_ "SigType" SG_ 2432541694 EngVriableGeometryTurboActuator1 1;
BA_ "SPN" SG_ 2432541694 EngTrbCmprssrBypssActtr1TmpSttus 5368;
BA_ "SPN" SG_ 2432541694 EngTrbCmprssrBypssActtr1PrlmnryF 5367;
BA_ "SPN" SG_ 2432541694 EngTrbCmprssorBypassActuator2Cmd 5369;
BA_ "SigType" SG_ 2432541694 EngTrbCmprssorBypassActuator2Cmd 1;
BA_ "SPN" SG_ 2432541694 EngTrbCmprssorBypassActuator1Pos 3675;
BA_ "SigType" SG_ 2432541694 EngTrbCmprssorBypassActuator1Pos 1;
BA_ "SPN" SG_ 2432541694 EngTrbCmprssorBypassActuator1Cmd 3470;
BA_ "SigType" SG_ 2432541694 EngTrbCmprssorBypassActuator1Cmd 1;
BA_ "SPN" SG_ 2432541694 EngDsrdTrbCmprssrBypssActtor1Pos 5366;
BA_ "SigType" SG_ 2432541694 EngDsrdTrbCmprssrBypssActtor1Pos 1;
BA_ "SPN" SG_ 2566759934 EnableStatusOfDoor10 3441;
BA_ "SigType" SG_ 2566759934 EnableStatusOfDoor10 4;
BA_ "SPN" SG_ 2566759934 OpenStatusOfDoor10 3440;
BA_ "SigType" SG_ 2566759934 OpenStatusOfDoor10 4;
BA_ "SPN" SG_ 2566759934 LockStatusOfDoor10 3439;
BA_ "SigType" SG_ 2566759934 LockStatusOfDoor10 4;
BA_ "SPN" SG_ 2566759934 EnableStatusOfDoor9 3438;
BA_ "SigType" SG_ 2566759934 EnableStatusOfDoor9 4;
BA_ "SPN" SG_ 2566759934 OpenStatusOfDoor9 3437;
BA_ "SigType" SG_ 2566759934 OpenStatusOfDoor9 4;
BA_ "SPN" SG_ 2566759934 LockStatusOfDoor9 3436;
BA_ "SigType" SG_ 2566759934 LockStatusOfDoor9 4;
BA_ "SPN" SG_ 2566759934 EnableStatusOfDoor8 3435;
BA_ "SigType" SG_ 2566759934 EnableStatusOfDoor8 4;
BA_ "SPN" SG_ 2566759934 OpenStatusOfDoor8 3434;
BA_ "SigType" SG_ 2566759934 OpenStatusOfDoor8 4;
BA_ "SPN" SG_ 2566759934 LockStatusOfDoor8 3433;
BA_ "SigType" SG_ 2566759934 LockStatusOfDoor8 4;
BA_ "SPN" SG_ 2566759934 EnableStatusOfDoor7 3432;
BA_ "SigType" SG_ 2566759934 EnableStatusOfDoor7 4;
BA_ "SPN" SG_ 2566759934 OpenStatusOfDoor7 3431;
BA_ "SigType" SG_ 2566759934 OpenStatusOfDoor7 4;
BA_ "SPN" SG_ 2566759934 LockStatusOfDoor7 3430;
BA_ "SigType" SG_ 2566759934 LockStatusOfDoor7 4;
BA_ "SPN" SG_ 2566759934 EnableStatusOfDoor6 3429;
BA_ "SigType" SG_ 2566759934 EnableStatusOfDoor6 4;
BA_ "SPN" SG_ 2566759934 OpenStatusOfDoor6 3428;
BA_ "SigType" SG_ 2566759934 OpenStatusOfDoor6 4;
BA_ "SPN" SG_ 2566759934 LockStatusOfDoor6 3427;
BA_ "SigType" SG_ 2566759934 LockStatusOfDoor6 4;
BA_ "SPN" SG_ 2566759934 EnableStatusOfDoor5 3426;
BA_ "SigType" SG_ 2566759934 EnableStatusOfDoor5 4;
BA_ "SPN" SG_ 2566759934 OpenStatusOfDoor5 3425;
BA_ "SigType" SG_ 2566759934 OpenStatusOfDoor5 4;
BA_ "SPN" SG_ 2566759934 LockStatusOfDoor5 3424;
BA_ "SigType" SG_ 2566759934 LockStatusOfDoor5 4;
BA_ "SPN" SG_ 2566759934 EnableStatusOfDoor4 3423;
BA_ "SigType" SG_ 2566759934 EnableStatusOfDoor4 4;
BA_ "SPN" SG_ 2566759934 OpenStatusOfDoor4 3422;
BA_ "SigType" SG_ 2566759934 OpenStatusOfDoor4 4;
BA_ "SPN" SG_ 2566759934 LockStatusOfDoor4 3421;
BA_ "SigType" SG_ 2566759934 LockStatusOfDoor4 4;
BA_ "SPN" SG_ 2566759934 EnableStatusOfDoor3 3420;
BA_ "SigType" SG_ 2566759934 EnableStatusOfDoor3 4;
BA_ "SPN" SG_ 2566759934 OpenStatusOfDoor3 3419;
BA_ "SigType" SG_ 2566759934 OpenStatusOfDoor3 4;
BA_ "SPN" SG_ 2566759934 LockStatusOfDoor3 3418;
BA_ "SigType" SG_ 2566759934 LockStatusOfDoor3 4;
BA_ "SPN" SG_ 2566759934 EnableStatusOfDoor2 3417;
BA_ "SigType" SG_ 2566759934 EnableStatusOfDoor2 4;
BA_ "SPN" SG_ 2566759934 OpenStatusOfDoor2 3416;
BA_ "SigType" SG_ 2566759934 OpenStatusOfDoor2 4;
BA_ "SPN" SG_ 2566759934 LockStatusOfDoor2 3415;
BA_ "SigType" SG_ 2566759934 LockStatusOfDoor2 4;
BA_ "SPN" SG_ 2566759934 EnableStatusOfDoor1 3414;
BA_ "SigType" SG_ 2566759934 EnableStatusOfDoor1 4;
BA_ "SPN" SG_ 2566759934 OpenStatusOfDoor1 3413;
BA_ "SigType" SG_ 2566759934 OpenStatusOfDoor1 4;
BA_ "SPN" SG_ 2566759934 LockStatusOfDoor1 3412;
BA_ "SigType" SG_ 2566759934 LockStatusOfDoor1 4;
BA_ "SPN" SG_ 2566757374 DieselExhaustFluidSpeedOfSound 7346;
BA_ "SigType" SG_ 2566757374 DieselExhaustFluidSpeedOfSound 1;
BA_ "SPN" SG_ 2566757374 AT1DieselExhaustFluidProperty 3521;
BA_ "SPN" SG_ 2566757374 AT1DslExhstFldPrprtsPrlminaryFMI 3520;
BA_ "SPN" SG_ 2566757374 AT1DslExhstFldTmp2PreliminaryFMI 3519;
BA_ "SPN" SG_ 2566757374 AT1DeselExhaustFluidConductivity 3518;
BA_ "SigType" SG_ 2566757374 AT1DeselExhaustFluidConductivity 1;
BA_ "SPN" SG_ 2566757374 AT1DselExhaustFluidConcentration 3516;
BA_ "SigType" SG_ 2566757374 AT1DselExhaustFluidConcentration 1;
BA_ "SPN" SG_ 2566757374 AT1DieselExhaustFluidTemp2 3515;
BA_ "SigType" SG_ 2566757374 AT1DieselExhaustFluidTemp2 1;
BA_ "SPN" SG_ 2364546302 RqdGnrtrAvrgLneLineACRMSVoltage 3386;
BA_ "SigType" SG_ 2364546302 RqdGnrtrAvrgLneLineACRMSVoltage 1;
BA_ "SPN" SG_ 2431654654 EngFuelActuator2CtrlCmd 1244;
BA_ "SigType" SG_ 2431654654 EngFuelActuator2CtrlCmd 1;
BA_ "SPN" SG_ 2431654654 EngFuelActuator1CtrlCmd 633;
BA_ "SigType" SG_ 2431654654 EngFuelActuator1CtrlCmd 1;
BA_ "SPN" SG_ 2431654654 EngThrottleActuator2CtrlCmd 3465;
BA_ "SigType" SG_ 2431654654 EngThrottleActuator2CtrlCmd 1;
BA_ "SPN" SG_ 2431654654 EngThrottleActuator1CtrlCmd 3464;
BA_ "SigType" SG_ 2431654654 EngThrottleActuator1CtrlCmd 1;
BA_ "SPN" SG_ 2364545534 EngCyl24KnockLevel 1375;
BA_ "SigType" SG_ 2364545534 EngCyl24KnockLevel 1;
BA_ "SPN" SG_ 2364545534 EngCyl23KnockLevel 1374;
BA_ "SigType" SG_ 2364545534 EngCyl23KnockLevel 1;
BA_ "SPN" SG_ 2364545534 EngCyl22KnockLevel 1373;
BA_ "SigType" SG_ 2364545534 EngCyl22KnockLevel 1;
BA_ "SPN" SG_ 2364545534 EngCyl21KnockLevel 1372;
BA_ "SigType" SG_ 2364545534 EngCyl21KnockLevel 1;
BA_ "SPN" SG_ 2364545534 EngCyl20KnockLevel 1371;
BA_ "SigType" SG_ 2364545534 EngCyl20KnockLevel 1;
BA_ "SPN" SG_ 2364545534 EngCyl19KnockLevel 1370;
BA_ "SigType" SG_ 2364545534 EngCyl19KnockLevel 1;
BA_ "SPN" SG_ 2364545534 EngCyl18KnockLevel 1369;
BA_ "SigType" SG_ 2364545534 EngCyl18KnockLevel 1;
BA_ "SPN" SG_ 2364545534 EngCyl17KnockLevel 1368;
BA_ "SigType" SG_ 2364545534 EngCyl17KnockLevel 1;
BA_ "SPN" SG_ 2364545278 EngCyl16KnockLevel 1367;
BA_ "SigType" SG_ 2364545278 EngCyl16KnockLevel 1;
BA_ "SPN" SG_ 2364545278 EngCyl15KnockLevel 1366;
BA_ "SigType" SG_ 2364545278 EngCyl15KnockLevel 1;
BA_ "SPN" SG_ 2364545278 EngCyl14KnockLevel 1365;
BA_ "SigType" SG_ 2364545278 EngCyl14KnockLevel 1;
BA_ "SPN" SG_ 2364545278 EngCyl13KnockLevel 1364;
BA_ "SigType" SG_ 2364545278 EngCyl13KnockLevel 1;
BA_ "SPN" SG_ 2364545278 EngCyl12KnockLevel 1363;
BA_ "SigType" SG_ 2364545278 EngCyl12KnockLevel 1;
BA_ "SPN" SG_ 2364545278 EngCyl11KnockLevel 1362;
BA_ "SigType" SG_ 2364545278 EngCyl11KnockLevel 1;
BA_ "SPN" SG_ 2364545278 EngCyl10KnockLevel 1361;
BA_ "SigType" SG_ 2364545278 EngCyl10KnockLevel 1;
BA_ "SPN" SG_ 2364545278 EngCyl9KnockLevel 1360;
BA_ "SigType" SG_ 2364545278 EngCyl9KnockLevel 1;
BA_ "SPN" SG_ 2364545022 EngCyl8KnockLevel 1359;
BA_ "SigType" SG_ 2364545022 EngCyl8KnockLevel 1;
BA_ "SPN" SG_ 2364545022 EngCyl7KnockLevel 1358;
BA_ "SigType" SG_ 2364545022 EngCyl7KnockLevel 1;
BA_ "SPN" SG_ 2364545022 EngCyl6KnockLevel 1357;
BA_ "SigType" SG_ 2364545022 EngCyl6KnockLevel 1;
BA_ "SPN" SG_ 2364545022 EngCyl5KnockLevel 1356;
BA_ "SigType" SG_ 2364545022 EngCyl5KnockLevel 1;
BA_ "SPN" SG_ 2364545022 EngCyl4KnockLevel 1355;
BA_ "SigType" SG_ 2364545022 EngCyl4KnockLevel 1;
BA_ "SPN" SG_ 2364545022 EngCyl3KnockLevel 1354;
BA_ "SigType" SG_ 2364545022 EngCyl3KnockLevel 1;
BA_ "SPN" SG_ 2364545022 EngCyl2KnockLevel 1353;
BA_ "SigType" SG_ 2364545022 EngCyl2KnockLevel 1;
BA_ "SPN" SG_ 2364545022 EngCyl1KnockLevel 1352;
BA_ "SigType" SG_ 2364545022 EngCyl1KnockLevel 1;
BA_ "SPN" SG_ 2364544766 EngCyl24CombustionStatus 3410;
BA_ "SigType" SG_ 2364544766 EngCyl24CombustionStatus 5;
BA_ "SPN" SG_ 2364544766 EngCyl23CombustionStatus 3409;
BA_ "SigType" SG_ 2364544766 EngCyl23CombustionStatus 5;
BA_ "SPN" SG_ 2364544766 EngCyl22CombustionStatus 3408;
BA_ "SigType" SG_ 2364544766 EngCyl22CombustionStatus 5;
BA_ "SPN" SG_ 2364544766 EngCyl21CombustionStatus 3407;
BA_ "SigType" SG_ 2364544766 EngCyl21CombustionStatus 5;
BA_ "SPN" SG_ 2364544766 EngCyl20CombustionStatus 3406;
BA_ "SigType" SG_ 2364544766 EngCyl20CombustionStatus 5;
BA_ "SPN" SG_ 2364544766 EngCyl19CombustionStatus 3405;
BA_ "SigType" SG_ 2364544766 EngCyl19CombustionStatus 5;
BA_ "SPN" SG_ 2364544766 EngCyl18CombustionStatus 3404;
BA_ "SigType" SG_ 2364544766 EngCyl18CombustionStatus 5;
BA_ "SPN" SG_ 2364544766 EngCyl17CombustionStatus 3403;
BA_ "SigType" SG_ 2364544766 EngCyl17CombustionStatus 5;
BA_ "SPN" SG_ 2364544766 EngCyl16CombustionStatus 3402;
BA_ "SigType" SG_ 2364544766 EngCyl16CombustionStatus 5;
BA_ "SPN" SG_ 2364544766 EngCyl15CombustionStatus 3401;
BA_ "SigType" SG_ 2364544766 EngCyl15CombustionStatus 5;
BA_ "SPN" SG_ 2364544766 EngCyl14CombustionStatus 3400;
BA_ "SigType" SG_ 2364544766 EngCyl14CombustionStatus 5;
BA_ "SPN" SG_ 2364544766 EngCyl13CombustionStatus 3399;
BA_ "SigType" SG_ 2364544766 EngCyl13CombustionStatus 5;
BA_ "SPN" SG_ 2364544766 EngCyl12CombustionStatus 3398;
BA_ "SigType" SG_ 2364544766 EngCyl12CombustionStatus 5;
BA_ "SPN" SG_ 2364544766 EngCyl11CombustionStatus 3397;
BA_ "SigType" SG_ 2364544766 EngCyl11CombustionStatus 5;
BA_ "SPN" SG_ 2364544766 EngCyl10CombustionStatus 3396;
BA_ "SigType" SG_ 2364544766 EngCyl10CombustionStatus 5;
BA_ "SPN" SG_ 2364544766 EngCyl9CombustionStatus 3395;
BA_ "SigType" SG_ 2364544766 EngCyl9CombustionStatus 5;
BA_ "SPN" SG_ 2364544766 EngCyl8CombustionStatus 3394;
BA_ "SigType" SG_ 2364544766 EngCyl8CombustionStatus 5;
BA_ "SPN" SG_ 2364544766 EngCyl7CombustionStatus 3393;
BA_ "SigType" SG_ 2364544766 EngCyl7CombustionStatus 5;
BA_ "SPN" SG_ 2364544766 EngCyl6CombustionStatus 3392;
BA_ "SigType" SG_ 2364544766 EngCyl6CombustionStatus 5;
BA_ "SPN" SG_ 2364544766 EngCyl5CombustionStatus 3391;
BA_ "SigType" SG_ 2364544766 EngCyl5CombustionStatus 5;
BA_ "SPN" SG_ 2364544766 EngCyl4CombustionStatus 3390;
BA_ "SigType" SG_ 2364544766 EngCyl4CombustionStatus 5;
BA_ "SPN" SG_ 2364544766 EngCyl3CombustionStatus 3389;
BA_ "SigType" SG_ 2364544766 EngCyl3CombustionStatus 5;
BA_ "SPN" SG_ 2364544766 EngCyl2CombustionStatus 3388;
BA_ "SigType" SG_ 2364544766 EngCyl2CombustionStatus 5;
BA_ "SPN" SG_ 2364544766 EngCyl1CombustionStatus 3387;
BA_ "SigType" SG_ 2364544766 EngCyl1CombustionStatus 5;
BA_ "SPN" SG_ 2364544510 RqGenOverallPowerFactorLagging 3385;
BA_ "SigType" SG_ 2364544510 RqGenOverallPowerFactorLagging 5;
BA_ "SPN" SG_ 2364544510 RqGeneratorOverallPowerFactor 3384;
BA_ "SigType" SG_ 2364544510 RqGeneratorOverallPowerFactor 1;
BA_ "SPN" SG_ 2364544510 RqGeneratorTotalACReactivePower 3383;
BA_ "SigType" SG_ 2364544510 RqGeneratorTotalACReactivePower 1;
BA_ "SPN" SG_ 2364544254 BladeRotationAngleFigureOfMerit 3332;
BA_ "SigType" SG_ 2364544254 BladeRotationAngleFigureOfMerit 5;
BA_ "SPN" SG_ 2364544254 RelativeBladeHeightFigureOfMerit 3367;
BA_ "SigType" SG_ 2364544254 RelativeBladeHeightFigureOfMerit 5;
BA_ "SPN" SG_ 2364544254 RltvBldHghtAndBldRttnAnglMsrmntL 3366;
BA_ "SigType" SG_ 2364544254 RltvBldHghtAndBldRttnAnglMsrmntL 1;
BA_ "SPN" SG_ 2364544254 BladeRotationAngle 3331;
BA_ "SigType" SG_ 2364544254 BladeRotationAngle 1;
BA_ "SPN" SG_ 2364544254 RelativeBladeHeight 3365;
BA_ "SigType" SG_ 2364544254 RelativeBladeHeight 1;
BA_ "SigType" SG_ 2349006590 BrakeLightSwitch 4;
BA_ "SigType" SG_ 2349006590 ASREngineControlActive 4;
BA_ "SigType" SG_ 2349006590 ASRBreakControlActive 4;
BA_ "SigType" SG_ 2349006590 VehicleRetarderCtrlActive 4;
BA_ "SigType" SG_ 2349006590 VehicleABSActive 4;
BA_ "SPN" SG_ 2365508094 RoadCurvature 1591;
BA_ "SigType" SG_ 2365508094 RoadCurvature 1;
BA_ "SigType" SG_ 2365508094 PneumaticControlLine 4;
BA_ "SigType" SG_ 2365508094 ABSOffroadRequest 4;
BA_ "SigType" SG_ 2365508094 TwoElCircuitsBrakeDemand 4;
BA_ "SigType" SG_ 2365508094 VehicleRetarderCtrlActive 4;
BA_ "SigType" SG_ 2349072126 ActualRetarderPercTorque 1;
BA_ "SigType" SG_ 2349072126 Wheel_BasedVehicleSpeed 1;
BA_ "SigType" SG_ 2349072126 SupplyLineBrakingRequest 4;
BA_ "SigType" SG_ 2349072126 VDCActive 4;
BA_ "SigType" SG_ 2349072126 AutomTowedVehBreakActive 4;
BA_ "SigType" SG_ 2349072126 VehicleServiceBrakeActive 4;
BA_ "SigType" SG_ 2349072126 VehicleRetarderCtrlActive 4;
BA_ "SigType" SG_ 2349072126 VehicleABSActive 4;
BA_ "SPN" SG_ 2365506814 ReferenceRetarderTorque 556;
BA_ "SigType" SG_ 2365506814 ReferenceRetarderTorque 1;
BA_ "SigType" SG_ 2365506814 SupplyLineBrakingRequest 4;
BA_ "SigType" SG_ 2365506814 LoadingRampApproachAssist 4;
BA_ "SigType" SG_ 2365506814 SpringBrakeEngaged 4;
BA_ "SigType" SG_ 2365506814 ElectrLoadPropFunc 4;
BA_ "SigType" SG_ 2365506814 SpringBrakeInstalled 4;
BA_ "SigType" SG_ 2365506814 ElecSupplyOfNonBrakingSys 4;
BA_ "SigType" SG_ 2365506814 AmberWarningSignalReq 4;
BA_ "SigType" SG_ 2365506814 RedWarningSignalRequest 4;
BA_ "SigType" SG_ 2365506814 VehicleElectrSupplySuff 4;
BA_ "SigType" SG_ 2365506814 AutomTowedVehBreakActive 4;
BA_ "SigType" SG_ 2365506814 VehicleServiceBrakeActive 4;
BA_ "SigType" SG_ 2365506814 VehicleRetarderCtrlActive 4;
BA_ "SigType" SG_ 2365506814 VehicleABSActive 4;
BA_ "SigType" SG_ 2365507326 VehiclePneumSupplySuff 4;
BA_ "SigType" SG_ 2365507326 BrakeTemperatureStatus 4;
BA_ "SigType" SG_ 2365507326 BrakeLiningSufficient 4;
BA_ "SigType" SG_ 2365507326 TyrePressureSufficient 4;
BA_ "SigType" SG_ 2363686654 ODDRequest 4;
BA_ "SigType" SG_ 2363686654 AntiTheftDeviceReq 4;
BA_ "SPN" SG_ 2365480446 MaxVehicleSpeedLimit 74;
BA_ "SigType" SG_ 2365480446 MaxVehicleSpeedLimit 1;
BA_ "SigType" SG_ 2365480958 VehicleSpeed 1;
BA_ "SigType" SG_ 2365480958 PercentLoadAtCurrentSpeed 1;
BA_ "SigType" SG_ 2365480958 EngineSpeed 1;
BA_ "SigType" SG_ 2365480958 ActualEngine_PercTorque 1;
BA_ "SigType" SG_ 2365480958 DriversDemandEngine_PercTorque 1;
BA_ "SigType" SG_ 2365480958 EngineRunning 4;
BA_ "SigType" SG_ 2365480958 EngineControlAllowed 4;
VAL_ 2566799614 ImplementRearWorkLight 3 "Not Available" 2 "Fault Detected" 1 "Activated" 0 "Deactivated" ;
VAL_ 2566799614 ImplementLeftFacingWorkLight 3 "Not Available" 2 "Fault Detected" 1 "Activated" 0 "Deactivated" ;
VAL_ 2566799614 ImplementRightForwardWorkLight 3 "Not Available" 2 "Fault Detected" 1 "Activated" 0 "Deactivated" ;
VAL_ 2566799614 ImplementLeftForwardWorkLight 3 "Not Available" 2 "Fault Detected" 1 "Activate" 0 "Deactivate" ;
VAL_ 2566799614 ImplementRightFacingWorkLight 3 "Not Available" 2 "Fault Detected" 1 "Activated" 0 "Deactivated" ;
VAL_ 2566799614 ImplementOEMOption1Light 3 "Not Available" 2 "Fault Detected" 1 "Activated" 0 "Deactivated" ;
VAL_ 2566799614 ImplementOEMOption2Light 3 "Not Available" 2 "Fault Detected" 1 "Activated" 0 "Deactivated" ;
VAL_ 2566799614 TrctorFrontHighMountedWorkLights 3 "Not Available" 2 "Fault Detected" 1 "Activated" 0 "Deactivated" ;
VAL_ 2566799614 TractorFrontLowMountedWorkLights 3 "Not Available" 2 "Fault Detected" 1 "Activated" 0 "Deactivated" ;
VAL_ 2566799614 TractorSideHighMountedWorkLights 3 "Not Available" 2 "Fault Detected" 1 "Activated" 0 "Deactivated" ;
VAL_ 2566799614 TractorSideLowMountedWorkLights 3 "Not Available" 2 "Fault Detected" 1 "Activated" 0 "Deactivated" ;
VAL_ 2566799614 TractorRearHighMountedWorkLights 3 "Not Available" 2 "Fault Detected" 1 "Activated" 0 "Deactivated" ;
VAL_ 2566799614 TractorRearLowMountedWorkLights 3 "Not Available" 2 "Fault Detected" 1 "Activated" 0 "Deactivated" ;
VAL_ 2566799614 TrctorUndersideMountedWorkLights 3 "Not Available" 2 "Fault Detected" 1 "Activated" 0 "Deactivated" ;
VAL_ 2566799614 RearFogLights 3 "Not Available" 2 "Fault Detected" 1 "Activated" 0 "Deactivated" ;
VAL_ 2566799614 TractorMarkerLight 3 "Not Available" 2 "Fault Detected" 1 "Activated" 0 "Deactivated" ;
VAL_ 2566799614 ImplementMarkerLight 3 "Not Available" 2 "Fault Detected" 1 "Activated" 0 "Deactivated" ;
VAL_ 2566799614 TractorClearanceLight 3 "Not Available" 2 "Fault Detected" 1 "Activated" 0 "Deactivated" ;
VAL_ 2566799614 ImplementClearanceLight 3 "Not Available" 2 "Fault Detected" 1 "Activated" 0 "Deactivated" ;
VAL_ 2566799614 LeftStopLight 3 "Not Available" 2 "Fault Detected" 1 "Activated" 0 "Deactivated" ;
VAL_ 2566799614 RightStopLight 3 "Not Available" 2 "Fault Detected" 1 "Activated" 0 "Deactivated" ;
VAL_ 2566799614 CenterStopLight 3 "Not Available" 2 "Fault Detected" 1 "Activated" 0 "Deactivated" ;
VAL_ 2566799614 BackUpLightAndAlarmHorn 3 "Not Available" 2 "Fault Detected" 1 "Activated" 0 "Deactivated" ;
VAL_ 2566799614 LeftTurnSignalLights 3 "Not Available" 2 "Fault Detected" 1 "Activated" 0 "Deactivated" ;
VAL_ 2566799614 RightTurnSignalLights 3 "Not Available" 2 "Fault Detected" 1 "Activated" 0 "Deactivated" ;
VAL_ 2566799614 RotatingBeaconLight 3 "Not Available" 2 "Fault Detected" 1 "Activated" 0 "Deactivated" ;
VAL_ 2566799614 TractorFrontFogLights 3 "Not Available" 2 "Fault Detected" 1 "Activated" 0 "Deactivated" ;
VAL_ 2566799614 HighBeamHeadLightData 3 "Not Available" 2 "Fault Detected" 1 "Activated" 0 "Deactivated" ;
VAL_ 2566799614 LowBeamHeadLightData 3 "Not Available" 2 "Fault Detected" 1 "Activated" 0 "Deactivated" ;
VAL_ 2566799614 AltBeamHeadLightData 3 "Not Available" 2 "Fault Detected" 1 "Activated" 0 "Deactivated" ;
VAL_ 2566799614 RunningLight 3 "Not Available" 2 "Fault Detected" 1 "Activated" 0 "Deactivated" ;
VAL_ 2365473278 ImplementRearWorkLightCmd 3 "Dont Care" 2 "Reserved" 1 "Activate" 0 "Deactivate" ;
VAL_ 2365473278 ImplementLeftFacingWorkLightCmd 3 "Dont Care" 2 "Reserved" 1 "Activate" 0 "Deactivate" ;
VAL_ 2365473278 ImplmentRightForwardWorkLightCmd 3 "Dont Care" 2 "Reserved" 1 "Activate" 0 "Deactivate" ;
VAL_ 2365473278 LightingDataRqCmd 3 "Dont Care" 2 "Reserved" 1 "Activate" 0 "Deactivate" ;
VAL_ 2365473278 ImplementLeftForwardWorkLightCmd 3 "Dont Care" 2 "Reserved" 1 "Activate" 0 "Deactivate" ;
VAL_ 2365473278 ImplementRightFacingWorkLightCmd 3 "Dont Care" 2 "Reserved" 1 "Activate" 0 "Deactivate" ;
VAL_ 2365473278 ImplementOEMOption1LightCmd 3 "Dont Care" 2 "Reserved" 1 "Activate" 0 "Deactivate" ;
VAL_ 2365473278 ImplementOEMOption2LightCmd 3 "Dont Care" 2 "Reserved" 1 "Activate" 0 "Deactivate" ;
VAL_ 2365473278 TrctrFrntHghMountedWorkLightsCmd 3 "Dont Care" 2 "Reserved" 1 "Activate" 0 "Deactivate" ;
VAL_ 2365473278 TrctrFrntLowMountedWorkLightsCmd 3 "Dont Care" 2 "Reserved" 1 "Activate" 0 "Deactivate" ;
VAL_ 2365473278 TrctrSdeHighMountedWorkLightsCmd 3 "Dont Care" 2 "Reserved" 1 "Activate" 0 "Deactivate" ;
VAL_ 2365473278 TrctrSideLowMountedWorkLightsCmd 3 "Dont Care" 2 "Reserved" 1 "Activate" 0 "Deactivate" ;
VAL_ 2365473278 TrctrRarHighMountedWorkLightsCmd 3 "Dont Care" 2 "Reserved" 1 "Activate" 0 "Deactivate" ;
VAL_ 2365473278 TrctrRearLowMountedWorkLightsCmd 3 "Dont Care" 2 "Reserved" 1 "Activate" 0 "Deactivate" ;
VAL_ 2365473278 TrctrUndrsdeMountedWorkLightsCmd 3 "Dont Care" 2 "Reserved" 1 "Activate" 0 "Deactivate" ;
VAL_ 2365473278 RearFogLightCmd 3 "Dont Care" 2 "Reserved" 1 "Activate" 0 "Deactivate" ;
VAL_ 2365473278 TractorMarkerLightCmd 3 "Dont Care" 2 "Reserved" 1 "Activate" 0 "Deactivate" ;
VAL_ 2365473278 ImplementMarkerLightCmd 3 "Dont Care" 2 "Reserved" 1 "Activate" 0 "Deactivate" ;
VAL_ 2365473278 TractorClearanceLightCmd 3 "Dont Care" 2 "Reserved" 1 "Activate" 0 "Deactivate" ;
VAL_ 2365473278 ImplementClearanceLightCmd 3 "Dont Care" 2 "Reserved" 1 "Activate" 0 "Deactivate" ;
VAL_ 2365473278 LeftStopLightCmd 3 "Dont Care" 2 "Reserved" 1 "Activate" 0 "Deactivate" ;
VAL_ 2365473278 RightStopLightCmd 3 "Dont Care" 2 "Reserved" 1 "Activate" 0 "Deactivate" ;
VAL_ 2365473278 CenterStopLightCmd 3 "Dont Care" 2 "Reserved" 1 "Activate" 0 "Deactivate" ;
VAL_ 2365473278 BackUpLightAndAlarmHornCmd 3 "Dont Care" 2 "Reserved" 1 "Activate" 0 "Deactivate" ;
VAL_ 2365473278 LeftTurnSignalLightsCmd 3 "Dont Care" 2 "Reserved" 1 "Activate" 0 "Deactivate" ;
VAL_ 2365473278 RightTurnSignalLightsCmd 3 "Dont Care" 2 "Reserved" 1 "Activate" 0 "Deactivate" ;
VAL_ 2365473278 RotatingBeaconLightCmd 3 "Dont Care" 2 "Reserved" 1 "Activate" 0 "Deactivate" ;
VAL_ 2365473278 TractorFrontFogLightsCmd 3 "Dont Care" 2 "Reserved" 1 "Activate" 0 "Deactivate" ;
VAL_ 2365473278 HighBeamHeadLightCmd 3 "Dont Care" 2 "Reserved" 1 "Activate" 0 "Deactivate" ;
VAL_ 2365473278 LowBeamHeadLightCmd 3 "Dont Care" 2 "Reserved" 1 "Activate" 0 "Deactivate" ;
VAL_ 2365473278 AltBeamHeadLightCmd 3 "Dont Care" 2 "Reserved" 1 "Activate" 0 "Deactivate" ;
VAL_ 2365473278 RunningLightCmd 3 "Dont Care" 2 "Reserved" 1 "Activate" 0 "Deactivate" ;
VAL_ 2365485822 LandLevelingSystemEnableStatus 3 "Not available / Not installed" 2 "Error" 0 "Disabled" ;
VAL_ 2365485822 BladeCtrlModeRight 15 "Not Available" 14 "Error" 2 "Inactive Auto" 1 "Auto" 0 "Manual" ;
VAL_ 2365485822 BladeCtrlModeLeft 15 "Not Available" 14 "Error" 2 "Inactive Auto" 1 "Auto" 0 "Manual" ;
VAL_ 2365485822 BladeCtrlMode 2 "Inactive automatic mode" 1 "Automatic mode" 0 "Manual mode" ;
VAL_ 2566768894 EngOprtrPrmryIntrmdtSpdSlctState 15 "not available" 14 "SAE reserved" 1 "thru 1101  Control state is ISC Setting 1 thru 13 in sequential order" 0 "Control state is ISC functionality is not requested engine operates normally" ;
VAL_ 2566769406 EngOprtrPrmryIntrmdteSpeedSelect 15 "not available" 14 "error condition" 1 "thru 1101  indicates that the ISC Setting 1 thru 13 in sequential order is selected" 0 "indicates that the ISC functionality is not requested engine operates normally" ;
VAL_ 2566811134 ADRCompliantHeaterInstallation 3 "Not Available" 2 "Error" 1 "Heater installation is ADR compliant" 0 "Heater installation is not ADR compliant" ;
VAL_ 2566811134 CabHeatingZone 3 "Not available" 2 "Reserved" 1 "Cab heating zone on" 0 "Cab heating zone off" ;
VAL_ 2566811134 EngHeatingZone 3 "Not available" 2 "Reserved" 1 "Engine heating zone on" 0 "Engine heating zone off" ;
VAL_ 2566811134 CabVentilation 3 "Not available" 2 "Reserved" 1 "Cab is ventilated" 0 "Cab not ventilated" ;
VAL_ 2566811134 AuxHeaterWaterPumpStatus 3 "Not available" 2 "Reserved" 1 "Water Pump is running" 0 "Water Pump is not running" ;
VAL_ 2566811134 AuxHeaterMode 15 "Not available" 14 "Error" 8 "Heater Locked - Indicates a sticky error state after running a number of failed heater start attempts.  Heater will need to be unlocked at a workshop." 7 "Diagnose Active - Indicates any active/running diagnostic service/routine/IO-control without the normal heater burn taking place." 6 "Heater Stopping - Indicates the burn-out phase of the heater which can be used to control the fan and circulation air flaps." 5 "Heater Starting - Indicates the start-phase of the heater which can be used to control the fan and circulation air flaps." 4 "Heater pump up-keep   (running the equipment in order to keep it in good condition)" 3 "Normal mode" 2 "Economy mode" 1 "Off due to ADR per European Regulations for Transport of hazardous materials" 0 "Heater not active" ;
VAL_ 2565867774 FireApparatusPumpEngagement 3 "Not available or not installed" 2 "Error" 1 "Pump engaged" 0 "Pump not engaged" ;
VAL_ 2565867774 HydPressGovernorPresetSwitch 3 "Not available" 2 "Error" 1 "Preset Switch Active" 0 "Preset Switch Inactive" ;
VAL_ 2565867774 HydPressGovernorIncreaseSwitch 3 "Not available" 2 "Error" 1 "Increase Switch Active" 0 "Increase Switch Inactive" ;
VAL_ 2565867774 HydPressGovernorDecreaseSwitch 3 "Not available" 2 "Error" 1 "Decrease Switch Active" 0 "Decrease Switch Inactive" ;
VAL_ 2565867774 HydPressGovernorIdleSwitch 3 "Not available" 2 "Error" 1 "Idle Switch Active" 0 "Idle Switch Inactive" ;
VAL_ 2565867774 FireApparatusOkayToPumpInterlock 3 "Not Available" 2 "Error" 1 "Okay to Pump Interlock Active" 0 "Okay to Pump Interlock Inactive" ;
VAL_ 2565867774 EngHydPressGovernorSwitch 3 "Not Available" 2 "Error Indicator" 1 "Pressure Mode Active" 0 "Pressure Mode Inactive" ;
VAL_ 2565867774 EngHydPressGovernorModeIndicator 3 "Not Available" 2 "Error Indicator" 1 "Enabled" 0 "Disabled" ;
VAL_ 2365449982 HydBrakeFluidLevelSwitch 3 "Not available" 2 "Error indicator" 1 "Fluid level is sufficient" 0 "Fluid level is not sufficient" ;
VAL_ 2365449982 HydBrakeSystemAudibleWarningCmd 3 "Dont care" 2 "Reserved" 1 "Audible warning on" 0 "Audible warning off" ;
VAL_ 2365449982 HydBrakePressSupplyStateCircuit2 3 "Not available" 2 "Error indicator" 1 "Supply is reliable" 0 "Supply is not reliable" ;
VAL_ 2365449982 HydBrakePressSupplyStateCircuit1 3 "Not available" 2 "Error indicator" 1 "Supply is reliable" 0 "Supply is not reliable" ;
VAL_ 2365449982 HydBrkePressWarningStateCircuit2 3 "Not available" 2 "Error indicator" 1 "Pressure level below warning level" 0 "Pressure level sufficient" ;
VAL_ 2365449982 HydBrkePressWarningStateCircuit1 3 "Not available" 2 "Error indicator" 1 "Pressure level below warning level" 0 "Pressure level sufficient" ;
VAL_ 2566759678 AtLeastOnePTOEngaged 3 "Not available" 2 "Error" 1 "At least one PTO drive is engaged" 0 "No PTO drive is engaged" ;
VAL_ 2566759678 EnggmntSttsPTOEngAccessoryDrive2 3 "Not available" 2 "Error" 1 "Drive engaged" 0 "Drive not engaged" ;
VAL_ 2566759678 EnggmntSttsPTOEngAccessoryDrive1 3 "Not available" 2 "Error" 1 "Drive engaged" 0 "Drive not engaged" ;
VAL_ 2566759678 EngagementStatusPTOEngFlywheel 3 "Not available" 2 "Error" 1 "Drive engaged" 0 "Drive not engaged" ;
VAL_ 2566759678 EnggmntStatusTransInputShaftPTO1 3 "Not available" 2 "Error" 1 "Drive is engaged" 0 "Drive not engaged" ;
VAL_ 2566759678 EnggmntStatusTransInputShaftPTO2 3 "Not available" 2 "Error" 1 "Drive is engaged" 0 "Drive not engaged" ;
VAL_ 2566759678 EnggmntStatusTransOutputShaftPTO 3 "Not available" 2 "Error" 1 "Drive is engaged" 0 "Drive not engaged" ;
VAL_ 2566759678 EnggmntSttsTrnsfrCsOtputShaftPTO 3 "Not available" 2 "Error" 1 "Drive is engaged" 0 "Drive not engaged" ;
VAL_ 2566759678 EnggmntCnsntPTOEngAccssoryDrive2 3 "Not available" 2 "Error" 1 "Consent given  PTO drive may be engaged" 0 "Consent not given  PTO drive may not be engaged" ;
VAL_ 2566759678 EnggmntCnsntPTOEngAccssoryDrive1 3 "Not available" 2 "Error" 1 "Consent given  PTO drive may be engaged" 0 "Consent not given  PTO drive may not be engaged" ;
VAL_ 2566759678 EngagementConsentPTOEngFlywheel 3 "Not available" 2 "Error" 1 "Consent given  PTO drive may be engaged" 0 "Consent not given  PTO drive may not be engaged" ;
VAL_ 2566759678 EnggmntCnsentTransInputShaftPTO1 3 "Not available" 2 "Error" 1 "Consent given  PTO drive may be engaged" 0 "Consent not given  PTO drive should not be engaged" ;
VAL_ 2566759678 EnggmntCnsentTransInputShaftPTO2 3 "Not available" 2 "Error" 1 "Consent given  PTO drive may be engaged" 0 "Consent not given  PTO drive should not be engaged" ;
VAL_ 2566759678 EnggmntCnsentTransOutputShaftPTO 3 "Not available" 2 "Error" 1 "Consent given  PTO drive may be engaged" 0 "Consent not given  PTO drive should not be engaged" ;
VAL_ 2566759678 EnggmntCnsntTrnsfrCsOtptShaftPTO 3 "Not available" 2 "Error" 1 "Consent given  PTO drive may be engaged" 0 "Consent not given  PTO drive should not be engaged" ;
VAL_ 2566759678 EnbleSwitchPTOEngAccessoryDrive2 3 "Not available" 2 "Error" 1 "Enable switch on  PTO operation desired" 0 "Enable switch off  PTO operation not desired" ;
VAL_ 2566759678 EnbleSwitchPTOEngAccessoryDrive1 3 "Not available" 2 "Error" 1 "Enable switch on  PTO operation desired" 0 "Enable switch off  PTO operation not desired" ;
VAL_ 2566759678 EnableSwitchPTOEngFlywheel 3 "Not available" 2 "Error" 1 "Enable switch on  PTO operation desired" 0 "Enable switch off  PTO operation not desired" ;
VAL_ 2566759678 EnableSwitchTransInputShaftPTO1 3 "Not available" 2 "Error" 1 "Enable switch off  PTO operation desired" 0 "Enable switch off  PTO operation not desired" ;
VAL_ 2566759678 EnableSwitchTransInputShaftPTO2 3 "Not available" 2 "Error" 1 "Enable switch off  PTO operation desired" 0 "Enable switch off  PTO operation not desired" ;
VAL_ 2566759678 EnableSwitchTransOutputShaftPTO 3 "Not available" 2 "Error" 1 "Enable switch off  PTO operation desired" 0 "Enable switch off  PTO operation not desired" ;
VAL_ 2566759678 EnblSwtchTrnsfrCseOutputShaftPTO 3 "Not available" 2 "Error" 1 "Enable switch off  PTO operation desired" 0 "Enable switch off  PTO operation not desired" ;
VAL_ 2432541694 EngTrbCmprssrBypssActtr1TmpSttus 7 "Not available" 6 "Error" 5 "Not Defined" 4 "Low Most severe" 3 "Low Least severe" 2 "In Range" 1 "High Least severe" 0 "High Most severe" ;
VAL_ 2566759934 EnableStatusOfDoor10 3 "not available" 2 "error" 1 "door enabled" 0 "door disabled" ;
VAL_ 2566759934 OpenStatusOfDoor10 3 "not available" 2 "error" 1 "door opened" 0 "door closed" ;
VAL_ 2566759934 LockStatusOfDoor10 3 "not available" 2 "error" 1 "locked" 0 "unlocked" ;
VAL_ 2566759934 EnableStatusOfDoor9 3 "not available" 2 "error" 1 "door enabled" 0 "door disabled" ;
VAL_ 2566759934 OpenStatusOfDoor9 3 "not available" 2 "error" 1 "door opened" 0 "door closed" ;
VAL_ 2566759934 LockStatusOfDoor9 3 "not available" 2 "error" 1 "locked" 0 "unlocked" ;
VAL_ 2566759934 EnableStatusOfDoor8 3 "not available" 2 "error" 1 "door enabled" 0 "door disabled" ;
VAL_ 2566759934 OpenStatusOfDoor8 3 "not available" 2 "error" 1 "door opened" 0 "door closed" ;
VAL_ 2566759934 LockStatusOfDoor8 3 "not available" 2 "error" 1 "locked" 0 "unlocked" ;
VAL_ 2566759934 EnableStatusOfDoor7 3 "not available" 2 "error" 1 "door enabled" 0 "door disabled" ;
VAL_ 2566759934 OpenStatusOfDoor7 3 "not available" 2 "error" 1 "door opened" 0 "door closed" ;
VAL_ 2566759934 LockStatusOfDoor7 3 "not available" 2 "error" 1 "locked" 0 "unlocked" ;
VAL_ 2566759934 EnableStatusOfDoor6 3 "not available" 2 "error" 1 "door enabled" 0 "door disabled" ;
VAL_ 2566759934 OpenStatusOfDoor6 3 "not available" 2 "error" 1 "door opened" 0 "door closed" ;
VAL_ 2566759934 LockStatusOfDoor6 3 "not available" 2 "error" 1 "locked" 0 "unlocked" ;
VAL_ 2566759934 EnableStatusOfDoor5 3 "not available" 2 "error" 1 "door enabled" 0 "door disabled" ;
VAL_ 2566759934 OpenStatusOfDoor5 3 "not available" 2 "error" 1 "door opened" 0 "door closed" ;
VAL_ 2566759934 LockStatusOfDoor5 3 "not available" 2 "error" 1 "locked" 0 "unlocked" ;
VAL_ 2566759934 EnableStatusOfDoor4 3 "not available" 2 "error" 1 "door enabled" 0 "door disabled" ;
VAL_ 2566759934 OpenStatusOfDoor4 3 "not available" 2 "error" 1 "door opened" 0 "door closed" ;
VAL_ 2566759934 LockStatusOfDoor4 3 "not available" 2 "error" 1 "locked" 0 "unlocked" ;
VAL_ 2566759934 EnableStatusOfDoor3 3 "not available" 2 "error" 1 "door enabled" 0 "door disabled" ;
VAL_ 2566759934 OpenStatusOfDoor3 3 "not available" 2 "error" 1 "door opened" 0 "door closed" ;
VAL_ 2566759934 LockStatusOfDoor3 3 "not available" 2 "error" 1 "locked" 0 "unlocked" ;
VAL_ 2566759934 EnableStatusOfDoor2 3 "not available" 2 "error" 1 "door enabled" 0 "door disabled" ;
VAL_ 2566759934 OpenStatusOfDoor2 3 "not available" 2 "error" 1 "door opened" 0 "door closed" ;
VAL_ 2566759934 LockStatusOfDoor2 3 "not available" 2 "error" 1 "locked" 0 "unlocked" ;
VAL_ 2566759934 EnableStatusOfDoor1 3 "not available" 2 "error" 1 "door enabled" 0 "door disabled" ;
VAL_ 2566759934 OpenStatusOfDoor1 3 "not available" 2 "error" 1 "door opened" 0 "door closed" ;
VAL_ 2566759934 LockStatusOfDoor1 3 "not available" 2 "error" 1 "locked" 0 "unlocked" ;
VAL_ 2566757374 AT1DieselExhaustFluidProperty 15 "Not available" 14 "Error detected with urea reagent type detection" 13 "Not able to determine catalyst reagent type type unknown" 3 "Catalyst reagent is proper mixture" 2 "Catalyst reagent is diesel" 1 "Catalyst reagent is urea concentration too low" 0 "Catalyst reagent is urea concentration too high" ;
VAL_ 2364544766 EngCyl24CombustionStatus 3 "Not available" 2 "Error" 1 "Combustion exists" 0 "No combustion" ;
VAL_ 2364544766 EngCyl23CombustionStatus 3 "Not available" 2 "Error" 1 "Combustion exists" 0 "No combustion" ;
VAL_ 2364544766 EngCyl22CombustionStatus 3 "Not available" 2 "Error" 1 "Combustion exists" 0 "No combustion" ;
VAL_ 2364544766 EngCyl21CombustionStatus 3 "Not available" 2 "Error" 1 "Combustion exists" 0 "No combustion" ;
VAL_ 2364544766 EngCyl20CombustionStatus 3 "Not available" 2 "Error" 1 "Combustion exists" 0 "No combustion" ;
VAL_ 2364544766 EngCyl19CombustionStatus 3 "Not available" 2 "Error" 1 "Combustion exists" 0 "No combustion" ;
VAL_ 2364544766 EngCyl18CombustionStatus 3 "Not available" 2 "Error" 1 "Combustion exists" 0 "No combustion" ;
VAL_ 2364544766 EngCyl17CombustionStatus 3 "Not available" 2 "Error" 1 "Combustion exists" 0 "No combustion" ;
VAL_ 2364544766 EngCyl16CombustionStatus 3 "Not available" 2 "Error" 1 "Combustion exists" 0 "No combustion" ;
VAL_ 2364544766 EngCyl15CombustionStatus 3 "Not available" 2 "Error" 1 "Combustion exists" 0 "No combustion" ;
VAL_ 2364544766 EngCyl14CombustionStatus 3 "Not available" 2 "Error" 1 "Combustion exists" 0 "No combustion" ;
VAL_ 2364544766 EngCyl13CombustionStatus 3 "Not available" 2 "Error" 1 "Combustion exists" 0 "No combustion" ;
VAL_ 2364544766 EngCyl12CombustionStatus 3 "Not available" 2 "Error" 1 "Combustion exists" 0 "No combustion" ;
VAL_ 2364544766 EngCyl11CombustionStatus 3 "Not available" 2 "Error" 1 "Combustion exists" 0 "No combustion" ;
VAL_ 2364544766 EngCyl10CombustionStatus 3 "Not available" 2 "Error" 1 "Combustion exists" 0 "No combustion" ;
VAL_ 2364544766 EngCyl9CombustionStatus 3 "Not available" 2 "Error" 1 "Combustion exists" 0 "No combustion" ;
VAL_ 2364544766 EngCyl8CombustionStatus 3 "Not available" 2 "Error" 1 "Combustion exists" 0 "No combustion" ;
VAL_ 2364544766 EngCyl7CombustionStatus 3 "Not available" 2 "Error" 1 "Combustion exists" 0 "No combustion" ;
VAL_ 2364544766 EngCyl6CombustionStatus 3 "Not available" 2 "Error" 1 "Combustion exists" 0 "No combustion" ;
VAL_ 2364544766 EngCyl5CombustionStatus 1 "Combustion exists" 0 "No combustion" 3 "Not available" 2 "Error" ;
VAL_ 2364544766 EngCyl4CombustionStatus 3 "Not available" 2 "Error" 1 "Combustion exists" 0 "No combustion" ;
VAL_ 2364544766 EngCyl3CombustionStatus 3 "Not available" 2 "Error" 1 "Combustion exists" 0 "No combustion" ;
VAL_ 2364544766 EngCyl2CombustionStatus 3 "Not available" 2 "Error" 1 "Combustion exists" 0 "No combustion" ;
VAL_ 2364544766 EngCyl1CombustionStatus 3 "Not available" 2 "Error" 1 "Combustion exists" 0 "No combustion" ;
VAL_ 2364544510 RqGenOverallPowerFactorLagging 3 "NotAvailable" 2 "Error" 1 "Lagging" 0 "Leading" ;
VAL_ 2364544254 BladeRotationAngleFigureOfMerit 3 "Blade Rotation Angle not available" 2 "Blade Rotation Angle failed Roll sensor failed to operate correctly" 1 "Blade Rotation Angle degraded Data is suspect due to environmental conditions" 0 "Blade Rotation Angle fully functional Data is within sensor specification" ;
VAL_ 2364544254 RelativeBladeHeightFigureOfMerit 3 "Relative Blade Height not available" 2 "Relative Blade Height failed" 1 "Relative Blade Height degraded Data is suspect due to environmental conditions" 0 "Relative Blade Height fully functional Data is within sensor specification" ;
VAL_ 2349006590 VehicleType 1 "Dolly axle" 0 "Towing or towed vehicle" ;
VAL_ 2349006590 BrakeLightSwitch 1 "Switch on" 0 "Switch off" ;
VAL_ 2349006590 ASREngineControlActive 3 "NotAvailable" 2 "Reserved" 1 "ASREngineControlActive" 0 "ASREngnCntrlPassiveButInstalled" ;
VAL_ 2349006590 ASRBreakControlActive 1 "Active" 0 "Passive, but installed" ;
VAL_ 2349006590 VehicleRetarderCtrlActive 1 "Active" 0 "Passive" ;
VAL_ 2349006590 VehicleABSActive 1 "Active" 0 "Passiv, but installed" ;
VAL_ 2365508094 PneumaticControlLine 1 "Towing veh with pn ctrl line" 0 "Towing veh without pn ctrl line" ;
VAL_ 2365508094 ABSOffroadRequest 1 "ABS off-road switch on" 0 "ABS off-road switch off" ;
VAL_ 2365508094 TwoElCircuitsBrakeDemand 1 "Two el. circuit brake available" 0 "One el. circuit brake available" ;
VAL_ 2365508094 VehicleRetarderCtrlActive 1 "Active" 0 "Passive" ;
VAL_ 2349072126 SupplyLineBrakingRequest 1 "Supply line braking request" 0 "No supply line braking request" ;
VAL_ 2349072126 VDCActive 1 "Active" 0 "Passive, but installed" ;
VAL_ 2349072126 AutomTowedVehBreakActive 1 "Active" 0 "Passive" ;
VAL_ 2349072126 VehicleServiceBrakeActive 1 "Active" 0 "Passive" ;
VAL_ 2349072126 VehicleRetarderCtrlActive 1 "Active" 0 "Passive" ;
VAL_ 2349072126 VehicleABSActive 1 "Active" 0 "Passiv, but installed" ;
VAL_ 2365506814 SupplyLineBrakingRequest 1 "Supply line braking request" 0 "No supply line braking request" ;
VAL_ 2365506814 LoadingRampApproachAssist 1 "Assistance active" 0 "Assistance not active" ;
VAL_ 2365506814 SpringBrakeEngaged 1 "Vehicle spring brake is engaged" 0 "Vehicle spring brake is released" ;
VAL_ 2365506814 ElectrLoadPropFunc 1 "Vehicle with el. load proportion" 0 "Vehicle without el. load proport" ;
VAL_ 2365506814 SpringBrakeInstalled 1 "Vehicle with spring brakes" 0 "Vehicle without spring brakes" ;
VAL_ 2365506814 VehicleType 1 "Dolly axle" 0 "Towing or towed vehicle" ;
VAL_ 2365506814 ElecSupplyOfNonBrakingSys 1 "Supply switched on" 0 "Supply switched off" ;
VAL_ 2365506814 AmberWarningSignalReq 1 "Towed vehicle failure indicated" 0 "No towed vehicle failure indicat" ;
VAL_ 2365506814 RedWarningSignalRequest 1 "Towed vehicle failure indicated" 0 "No towed vehicle failure indicat" ;
VAL_ 2365506814 VehicleElectrSupplySuff 1 "Vehicle el. supply sufficient" 0 "Vehicle el. supply insufficient" ;
VAL_ 2365506814 AutomTowedVehBreakActive 1 "Active" 0 "Passive" ;
VAL_ 2365506814 VehicleServiceBrakeActive 1 "Active" 0 "Passive" ;
VAL_ 2365506814 VehicleRetarderCtrlActive 1 "Active" 0 "Passive" ;
VAL_ 2365506814 VehicleABSActive 1 "Active" 0 "Passiv, but installed" ;
VAL_ 2365507326 TyreWheelIdentTemp2 15 "Axle position 15" 14 "Axle position 14" 13 "Axle position 13" 12 "Axle position 12" 11 "Axle position 11" 10 "Axle position 10" 9 "Axle position 9" 8 "Axle position 8" 7 "Axle position 7" 6 "Axle position 6" 5 "Axle position 5" 4 "Axle position 4" 3 "Axle position 3" 2 "Axle position 2" 1 "Axle position 1" 0 "Axle position not identified" ;
VAL_ 2365507326 TyreWheelIdentTemp1 15 "Wheel position 15" 14 "Wheel position 14" 13 "Wheel position 13" 12 "Wheel position 12" 11 "Wheel position 11" 10 "Wheel position 10" 9 "Wheel position 9" 8 "Wheel position 8" 7 "Wheel position 7" 6 "Wheel position 6" 5 "Wheel position 5" 4 "Wheel position 4" 3 "Wheel position 3" 2 "Wheel position 2" 1 "Wheel position 1" 0 "Wheel position not identified" ;
VAL_ 2365507326 TyreWheelIdentPressure2 15 "Axle position 15" 14 "Axle position 14" 13 "Axle position 13" 12 "Axle position 12" 11 "Axle position 11" 10 "Axle position 10" 9 "Axle position 9" 8 "Axle position 8" 7 "Axle position 7" 6 "Axle position 6" 5 "Axle position 5" 4 "Axle position 4" 3 "Axle position 3" 2 "Axle position 2" 1 "Axle position 1" 0 "Axle position not identified" ;
VAL_ 2365507326 TyreWheelIdentPressure1 15 "Wheel position 15" 14 "Wheel position 14" 13 "Wheel position 13" 12 "Wheel position 12" 11 "Wheel position 11" 10 "Wheel position 10" 9 "Wheel position 9" 8 "Wheel position 8" 7 "Wheel position 7" 6 "Wheel position 6" 5 "Wheel position 5" 4 "Wheel position 4" 3 "Wheel position 3" 2 "Wheel position 2" 1 "Wheel position 1" 0 "Wheel position not identified" ;
VAL_ 2365507326 TyreWheelIdentLining2 15 "Axle position 15" 14 "Axle position 14" 13 "Axle position 13" 12 "Axle position 12" 11 "Axle position 11" 10 "Axle position 10" 9 "Axle position 9" 8 "Axle position 8" 7 "Axle position 7" 6 "Axle position 6" 5 "Axle position 5" 4 "Axle position 4" 3 "Axle position 3" 2 "Axle position 2" 1 "Axle position 1" 0 "Axle position not identified" ;
VAL_ 2365507326 TyreWheelIdentLining1 15 "Wheel position 15" 14 "Wheel position 14" 13 "Wheel position 13" 12 "Wheel position 12" 11 "Wheel position 11" 10 "Wheel position 10" 9 "Wheel position 9" 8 "Wheel position 8" 7 "Wheel position 7" 6 "Wheel position 6" 5 "Wheel position 5" 4 "Wheel position 4" 3 "Wheel position 3" 2 "Wheel position 2" 1 "Wheel position 1" 0 "Wheel position not identified" ;
VAL_ 2365507326 VehiclePneumSupplySuff 1 "Pneumatic supply sufficient" 0 "Pneumatic supply insufficient" ;
VAL_ 2365507326 BrakeTemperatureStatus 1 "Brake temperature normal" 0 "Brake temperature out of range" ;
VAL_ 2365507326 BrakeLiningSufficient 1 "Brake linings sufficient" 0 "Brake linings insufficient" ;
VAL_ 2365507326 TyrePressureSufficient 1 "Tyre pressure sufficient" 0 "Tyre pressure insufficient" ;
VAL_ 2363686654 ODDRequest 3 "Take no action" 1 "ODD on" 0 "ODD off" ;
VAL_ 2363686654 AntiTheftDeviceReq 3 "Take no action" 1 "Anti-theft device on" 0 "Anti-theft device off" ;
VAL_ 2363686654 VehicleType 1 "Dolly axle" 0 "Towing or towed vehicle" ;
VAL_ 2365480958 EngineTorqueMode 15 "Not available" 11 "Remote accelerator" 10 "Braking system" 9 "High speed governor" 8 "Torque limiting" 7 "ABS control" 6 "Transmission control" 5 "ASR control" 4 "Road speed governor" 3 "PTO governor" 2 "Cruise control" 1 "Accelerator pedal/operator selec" 0 "Low idle governor/no request (de" ;
VAL_ 2365480958 EngineRunning 1 "Engine running" 0 "Engine not running" ;
VAL_ 2365480958 EngineControlAllowed 1 "Engine control allowed" 0 "Engine control not allowed" ;
